VERSION ""

NS_ :

BS_:

BU_: CAMERA_ALL ALM_DX ALM_SX CAMERA_DEFAULT LOGBOX CAMERA_POS0 CAMERA_POS1 CAMERA_POS2 CAMERA_POS3 CAMERA_POS4 CAMERA_POS5 CAMERA_POS6 CAMERA_POS7 SVS RUR RUF RUC BC _TESTER BMS3_ADB BMS0_ADB BMS4_ADB BMS5_ADB BMS6_ADB
VAL_TABLE_ ___spare___ 3 "_SPARE_3" 2 "_SPARE_2" 1 "_SPARE_1" 0 "_SPARE_0" ;
VAL_TABLE_ HeaterWaterTemp 255 "NOT AVAILABLE" 254 "ERROR" ;

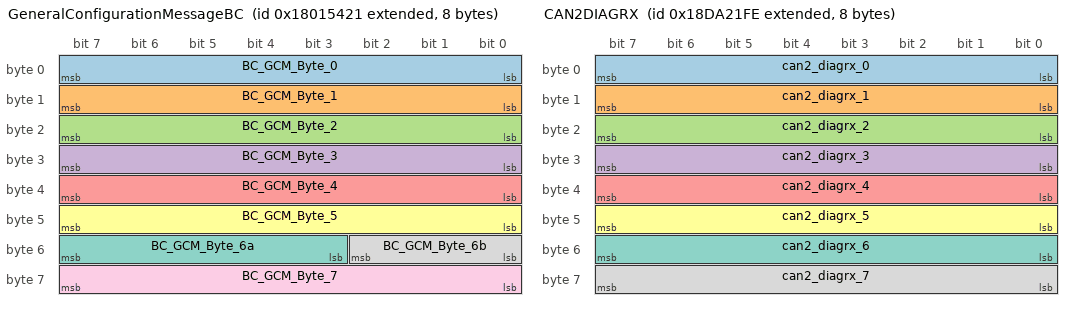
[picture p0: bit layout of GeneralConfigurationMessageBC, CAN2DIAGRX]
BO_ 2550223905 GeneralConfigurationMessageBC: 8 BC
 SG_ BC_GCM_Byte_0 : 0|8@1+ (1,0) [170|170] "-"  SVS
 SG_ BC_GCM_Byte_1 : 8|8@1+ (1,0) [107|107] "-"  SVS
 SG_ BC_GCM_Byte_2 : 16|8@1+ (1,0) [128|136] "-"  SVS
 SG_ BC_GCM_Byte_3 : 24|8@1+ (1,0) [0|0] "-"  SVS
 SG_ BC_GCM_Byte_4 : 32|8@1+ (1,0) [0|0] "-"  SVS
 SG_ BC_GCM_Byte_5 : 40|8@1+ (1,0) [0|0] "-"  SVS
 SG_ BC_GCM_Byte_6a : 51|5@1+ (1,0) [0|0] "-"  SVS
 SG_ BC_GCM_Byte_6b : 48|3@1+ (1,0) [0|7] "-"  SVS
 SG_ BC_GCM_Byte_7 : 56|8@1+ (1,0) [128|135] "-"  SVS

BO_ 2564432382 CAN2DIAGRX: 8 _TESTER
 SG_ can2_diagrx_0 : 0|8@1+ (1,0) [0|0] "-"  BC
 SG_ can2_diagrx_1 : 8|8@1+ (1,0) [0|0] "-"  BC
 SG_ can2_diagrx_2 : 16|8@1+ (1,0) [0|0] "-"  BC
 SG_ can2_diagrx_3 : 24|8@1+ (1,0) [0|0] "-"  BC
 SG_ can2_diagrx_4 : 32|8@1+ (1,0) [0|0] "-"  BC
 SG_ can2_diagrx_5 : 40|8@1+ (1,0) [0|0] "-"  BC
 SG_ can2_diagrx_6 : 48|8@1+ (1,0) [0|0] "-"  BC
 SG_ can2_diagrx_7 : 56|8@1+ (1,0) [0|0] "-"  BC

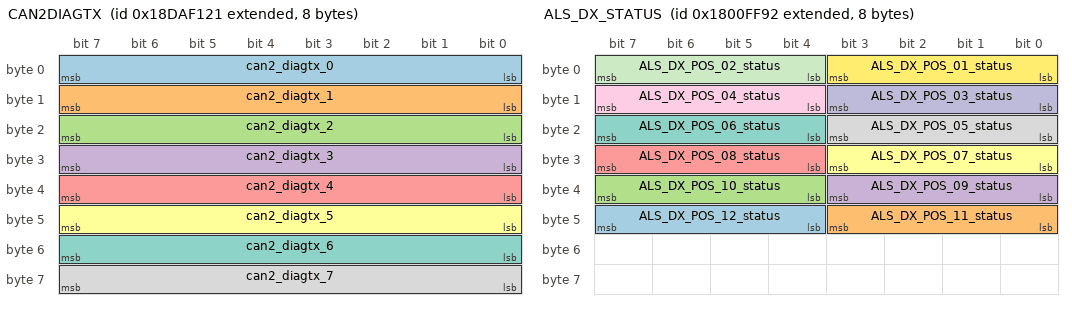
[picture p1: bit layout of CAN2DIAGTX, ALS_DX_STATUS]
BO_ 2564485409 CAN2DIAGTX: 8 BC
 SG_ can2_diagtx_0 : 0|8@1+ (1,0) [0|0] "-"  _TESTER
 SG_ can2_diagtx_1 : 8|8@1+ (1,0) [0|0] "-"  _TESTER
 SG_ can2_diagtx_2 : 16|8@1+ (1,0) [0|0] "-"  _TESTER
 SG_ can2_diagtx_3 : 24|8@1+ (1,0) [0|0] "-"  _TESTER
 SG_ can2_diagtx_4 : 32|8@1+ (1,0) [0|0] "-"  _TESTER
 SG_ can2_diagtx_5 : 40|8@1+ (1,0) [0|0] "-"  _TESTER
 SG_ can2_diagtx_6 : 48|8@1+ (1,0) [0|0] "-"  _TESTER
 SG_ can2_diagtx_7 : 56|8@1+ (1,0) [0|0] "-"  _TESTER

BO_ 2550202258 ALS_DX_STATUS: 8 ALM_DX
 SG_ ALS_DX_POS_12_status : 44|4@1+ (1,0) [0|15] "-"  BC,LOGBOX,SVS
 SG_ ALS_DX_POS_11_status : 40|4@1+ (1,0) [0|15] "-"  BC,LOGBOX,SVS
 SG_ ALS_DX_POS_10_status : 36|4@1+ (1,0) [0|15] "-"  BC,LOGBOX,SVS
 SG_ ALS_DX_POS_09_status : 32|4@1+ (1,0) [0|15] "-"  BC,LOGBOX,SVS
 SG_ ALS_DX_POS_08_status : 28|4@1+ (1,0) [0|15] "-"  BC,LOGBOX,SVS
 SG_ ALS_DX_POS_07_status : 24|4@1+ (1,0) [0|15] "-"  BC,LOGBOX,SVS
 SG_ ALS_DX_POS_06_status : 20|4@1+ (1,0) [0|15] "-"  BC,LOGBOX,SVS
 SG_ ALS_DX_POS_05_status : 16|4@1+ (1,0) [0|15] "-"  BC,LOGBOX,SVS
 SG_ ALS_DX_POS_04_status : 12|4@1+ (1,0) [0|15] "-"  BC,LOGBOX,SVS
 SG_ ALS_DX_POS_03_status : 8|4@1+ (1,0) [0|15] "-"  BC,LOGBOX,SVS
 SG_ ALS_DX_POS_02_status : 4|4@1+ (1,0) [0|15] "-"  BC,LOGBOX,SVS
 SG_ ALS_DX_POS_01_status : 0|4@1+ (1,0) [0|15] "-"  BC,LOGBOX,SVS

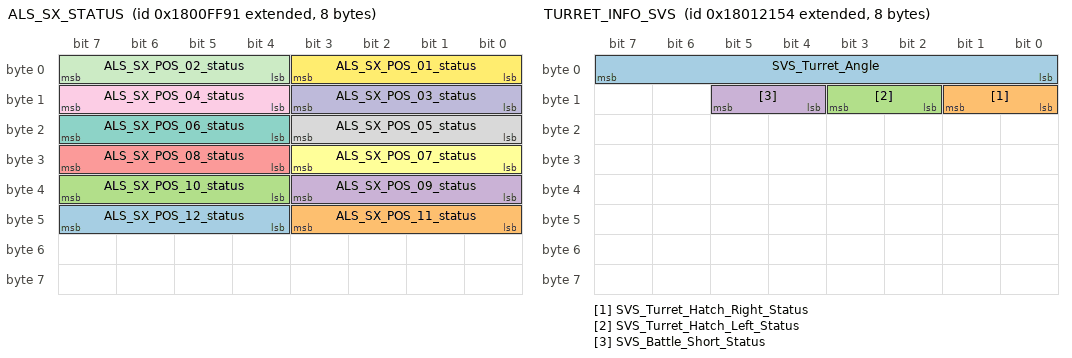
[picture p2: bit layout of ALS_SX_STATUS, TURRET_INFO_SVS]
BO_ 2550202257 ALS_SX_STATUS: 8 ALM_SX
 SG_ ALS_SX_POS_12_status : 44|4@1+ (1,0) [0|15] "-"  BC,LOGBOX,SVS
 SG_ ALS_SX_POS_11_status : 40|4@1+ (1,0) [0|15] "-"  BC,LOGBOX,SVS
 SG_ ALS_SX_POS_10_status : 36|4@1+ (1,0) [0|15] "-"  BC,LOGBOX,SVS
 SG_ ALS_SX_POS_09_status : 32|4@1+ (1,0) [0|15] "-"  BC,LOGBOX,SVS
 SG_ ALS_SX_POS_08_status : 28|4@1+ (1,0) [0|15] "-"  BC,LOGBOX,SVS
 SG_ ALS_SX_POS_07_status : 24|4@1+ (1,0) [0|15] "-"  BC,LOGBOX,SVS
 SG_ ALS_SX_POS_06_status : 20|4@1+ (1,0) [0|15] "-"  BC,LOGBOX,SVS
 SG_ ALS_SX_POS_05_status : 16|4@1+ (1,0) [0|15] "-"  BC,LOGBOX,SVS
 SG_ ALS_SX_POS_04_status : 12|4@1+ (1,0) [0|15] "-"  BC,LOGBOX,SVS
 SG_ ALS_SX_POS_03_status : 8|4@1+ (1,0) [0|15] "-"  BC,LOGBOX,SVS
 SG_ ALS_SX_POS_02_status : 4|4@1+ (1,0) [0|15] "-"  BC,LOGBOX,SVS
 SG_ ALS_SX_POS_01_status : 0|4@1+ (1,0) [0|15] "-"  BC,LOGBOX,SVS

BO_ 2550210900 TURRET_INFO_SVS: 8 SVS
 SG_ SVS_Turret_Angle : 0|8@1+ (1.44,-180) [-180|180] "deg"  LOGBOX,BC
 SG_ SVS_Turret_Hatch_Right_Status : 8|2@1+ (1,0) [0|3] "-"  LOGBOX,BC
 SG_ SVS_Turret_Hatch_Left_Status : 10|2@1+ (1,0) [0|3] "-"  LOGBOX,BC
 SG_ SVS_Battle_Short_Status : 12|2@1+ (1,0) [0|3] "-"  LOGBOX,BC

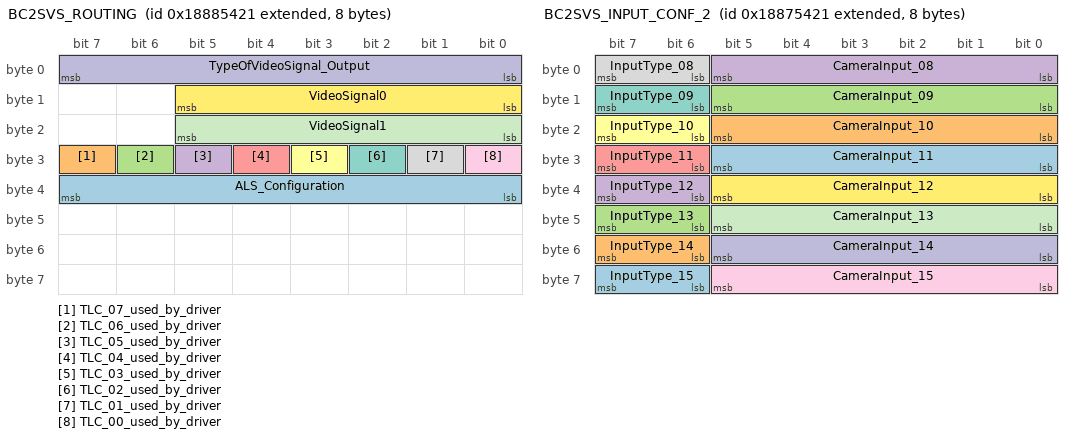
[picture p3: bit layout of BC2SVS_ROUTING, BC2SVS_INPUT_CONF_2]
BO_ 2559071265 BC2SVS_ROUTING: 8 BC
 SG_ ALS_Configuration : 32|8@1+ (1,0) [0|255] "-"  LOGBOX,SVS
 SG_ TLC_07_used_by_driver : 31|1@1+ (1,0) [0|1] "-"  LOGBOX,SVS
 SG_ TLC_06_used_by_driver : 30|1@1+ (1,0) [0|1] "-"  LOGBOX,SVS
 SG_ TLC_05_used_by_driver : 29|1@1+ (1,0) [0|1] "-"  LOGBOX,SVS
 SG_ TLC_04_used_by_driver : 28|1@1+ (1,0) [0|1] "-"  LOGBOX,SVS
 SG_ TLC_03_used_by_driver : 27|1@1+ (1,0) [0|1] "-"  LOGBOX,SVS
 SG_ TLC_02_used_by_driver : 26|1@1+ (1,0) [0|1] "-"  LOGBOX,SVS
 SG_ TLC_01_used_by_driver : 25|1@1+ (1,0) [0|1] "-"  LOGBOX,SVS
 SG_ TLC_00_used_by_driver : 24|1@1+ (1,0) [0|1] "-"  LOGBOX,SVS
 SG_ TypeOfVideoSignal_Output : 0|8@1+ (1,0) [0|255] "-"  LOGBOX,SVS
 SG_ VideoSignal1 : 16|6@1+ (1,0) [0|31] "-"  LOGBOX,SVS
 SG_ VideoSignal0 : 8|6@1+ (1,0) [0|31] "-"  LOGBOX,SVS

BO_ 2559005729 BC2SVS_INPUT_CONF_2: 8 BC
 SG_ InputType_15 : 62|2@1+ (1,0) [0|3] "-"  LOGBOX,SVS
 SG_ InputType_14 : 54|2@1+ (1,0) [0|3] "-"  LOGBOX,SVS
 SG_ InputType_13 : 46|2@1+ (1,0) [0|3] "-"  LOGBOX,SVS
 SG_ InputType_12 : 38|2@1+ (1,0) [0|3] "-"  LOGBOX,SVS
 SG_ InputType_11 : 30|2@1+ (1,0) [0|3] "-"  LOGBOX,SVS
 SG_ InputType_10 : 22|2@1+ (1,0) [0|3] "-"  LOGBOX,SVS
 SG_ InputType_09 : 14|2@1+ (1,0) [0|3] "-"  LOGBOX,SVS
 SG_ InputType_08 : 6|2@1+ (1,0) [0|3] "-"  LOGBOX,SVS
 SG_ CameraInput_15 : 56|6@1+ (1,0) [0|31] "-"  LOGBOX,SVS
 SG_ CameraInput_14 : 48|6@1+ (1,0) [0|31] "-"  LOGBOX,SVS
 SG_ CameraInput_13 : 40|6@1+ (1,0) [0|31] "-"  LOGBOX,SVS
 SG_ CameraInput_12 : 32|6@1+ (1,0) [0|31] "-"  LOGBOX,SVS
 SG_ CameraInput_11 : 24|6@1+ (1,0) [0|31] "-"  LOGBOX,SVS
 SG_ CameraInput_10 : 16|6@1+ (1,0) [0|31] "-"  LOGBOX,SVS
 SG_ CameraInput_09 : 8|6@1+ (1,0) [0|31] "-"  LOGBOX,SVS
 SG_ CameraInput_08 : 0|6@1+ (1,0) [0|31] "-"  LOGBOX,SVS

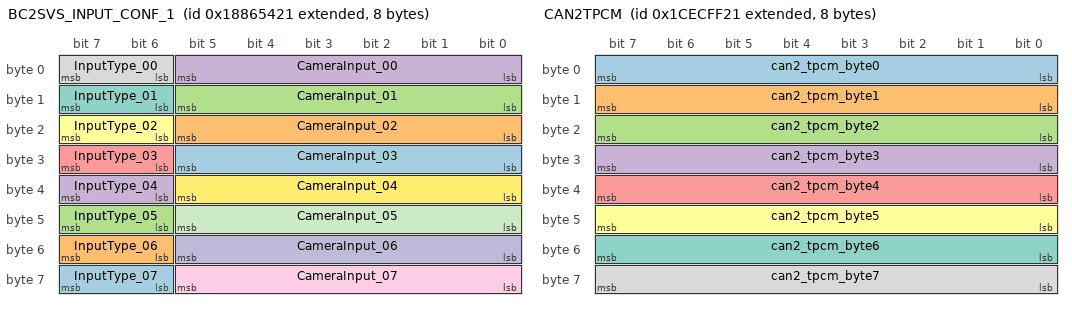
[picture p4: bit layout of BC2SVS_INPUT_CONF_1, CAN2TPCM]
BO_ 2558940193 BC2SVS_INPUT_CONF_1: 8 BC
 SG_ InputType_07 : 62|2@1+ (1,0) [0|3] "-"  LOGBOX,SVS
 SG_ InputType_06 : 54|2@1+ (1,0) [0|3] "-"  LOGBOX,SVS
 SG_ InputType_05 : 46|2@1+ (1,0) [0|3] "-"  LOGBOX,SVS
 SG_ InputType_04 : 38|2@1+ (1,0) [0|3] "-"  LOGBOX,SVS
 SG_ InputType_03 : 30|2@1+ (1,0) [0|3] "-"  LOGBOX,SVS
 SG_ InputType_02 : 22|2@1+ (1,0) [0|3] "-"  LOGBOX,SVS
 SG_ InputType_01 : 14|2@1+ (1,0) [0|3] "-"  LOGBOX,SVS
 SG_ InputType_00 : 6|2@1+ (1,0) [0|3] "-"  LOGBOX,SVS
 SG_ CameraInput_07 : 56|6@1+ (1,0) [0|31] "-"  LOGBOX,SVS
 SG_ CameraInput_06 : 48|6@1+ (1,0) [0|31] "-"  LOGBOX,SVS
 SG_ CameraInput_05 : 40|6@1+ (1,0) [0|31] "-"  LOGBOX,SVS
 SG_ CameraInput_04 : 32|6@1+ (1,0) [0|31] "-"  LOGBOX,SVS
 SG_ CameraInput_03 : 24|6@1+ (1,0) [0|31] "-"  LOGBOX,SVS
 SG_ CameraInput_02 : 16|6@1+ (1,0) [0|31] "-"  LOGBOX,SVS
 SG_ CameraInput_01 : 8|6@1+ (1,0) [0|31] "-"  LOGBOX,SVS
 SG_ CameraInput_00 : 0|6@1+ (1,0) [0|31] "-"  LOGBOX,SVS

BO_ 2632777505 CAN2TPCM: 8 BC
 SG_ can2_tpcm_byte0 : 0|8@1+ (1,0) [0|0] "-"  LOGBOX,_TESTER
 SG_ can2_tpcm_byte1 : 8|8@1+ (1,0) [0|0] "-"  LOGBOX,_TESTER
 SG_ can2_tpcm_byte2 : 16|8@1+ (1,0) [0|0] "-"  LOGBOX,_TESTER
 SG_ can2_tpcm_byte3 : 24|8@1+ (1,0) [0|0] "-"  LOGBOX,_TESTER
 SG_ can2_tpcm_byte4 : 32|8@1+ (1,0) [0|0] "-"  LOGBOX,_TESTER
 SG_ can2_tpcm_byte5 : 40|8@1+ (1,0) [0|0] "-"  LOGBOX,_TESTER
 SG_ can2_tpcm_byte6 : 48|8@1+ (1,0) [0|0] "-"  LOGBOX,_TESTER
 SG_ can2_tpcm_byte7 : 56|8@1+ (1,0) [0|0] "-"  LOGBOX,_TESTER

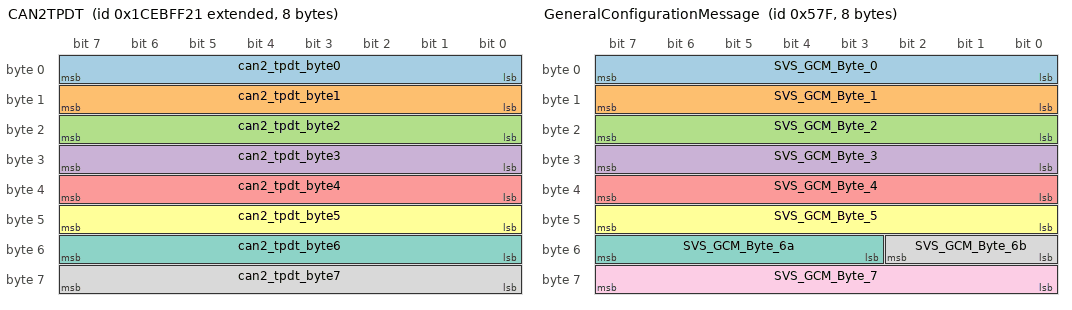
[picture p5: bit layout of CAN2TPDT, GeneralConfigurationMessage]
BO_ 2632711969 CAN2TPDT: 8 BC
 SG_ can2_tpdt_byte0 : 0|8@1+ (1,0) [0|0] "-"  LOGBOX,_TESTER
 SG_ can2_tpdt_byte1 : 8|8@1+ (1,0) [0|0] "-"  LOGBOX,_TESTER
 SG_ can2_tpdt_byte2 : 16|8@1+ (1,0) [0|0] "-"  LOGBOX,_TESTER
 SG_ can2_tpdt_byte3 : 24|8@1+ (1,0) [0|0] "-"  LOGBOX,_TESTER
 SG_ can2_tpdt_byte4 : 32|8@1+ (1,0) [0|0] "-"  LOGBOX,_TESTER
 SG_ can2_tpdt_byte5 : 40|8@1+ (1,0) [0|0] "-"  LOGBOX,_TESTER
 SG_ can2_tpdt_byte6 : 48|8@1+ (1,0) [0|0] "-"  LOGBOX,_TESTER
 SG_ can2_tpdt_byte7 : 56|8@1+ (1,0) [0|0] "-"  LOGBOX,_TESTER

BO_ 2550145364 CameraStatus: 8 SVS
 SG_ SVS_IN_31_status : 62|2@1+ (1,0) [0|3] "-"  LOGBOX
 SG_ SVS_IN_30_status : 60|2@1+ (1,0) [0|3] "-"  LOGBOX
 SG_ SVS_IN_29_status : 58|2@1+ (1,0) [0|3] "-"  LOGBOX
 SG_ SVS_IN_28_status : 56|2@1+ (1,0) [0|3] "-"  LOGBOX
 SG_ SVS_IN_27_status : 54|2@1+ (1,0) [0|3] "-"  LOGBOX
 SG_ SVS_IN_26_status : 52|2@1+ (1,0) [0|3] "-"  LOGBOX
 SG_ SVS_IN_25_status : 50|2@1+ (1,0) [0|3] "-"  LOGBOX
 SG_ SVS_IN_24_status : 48|2@1+ (1,0) [0|3] "-"  LOGBOX
 SG_ SVS_IN_23_status : 46|2@1+ (1,0) [0|3] "-"  LOGBOX
 SG_ SVS_IN_22_status : 44|2@1+ (1,0) [0|3] "-"  LOGBOX
 SG_ SVS_IN_21_status : 42|2@1+ (1,0) [0|3] "-"  LOGBOX
 SG_ SVS_IN_20_status : 40|2@1+ (1,0) [0|3] "-"  LOGBOX
 SG_ SVS_IN_19_status : 38|2@1+ (1,0) [0|3] "-"  LOGBOX
 SG_ SVS_IN_18_status : 36|2@1+ (1,0) [0|3] "-"  LOGBOX
 SG_ SVS_IN_17_status : 34|2@1+ (1,0) [0|3] "-"  LOGBOX
 SG_ SVS_IN_16_status : 32|2@1+ (1,0) [0|3] "-"  LOGBOX
 SG_ SVS_IN_15_status : 30|2@1+ (1,0) [0|3] "-"  LOGBOX
 SG_ SVS_IN_14_status : 28|2@1+ (1,0) [0|3] "-"  LOGBOX
 SG_ SVS_IN_13_status : 26|2@1+ (1,0) [0|3] "-"  LOGBOX
 SG_ SVS_IN_12_status : 24|2@1+ (1,0) [0|3] "-"  LOGBOX
 SG_ SVS_IN_11_status : 22|2@1+ (1,0) [0|3] "-"  LOGBOX
 SG_ SVS_IN_10_status : 20|2@1+ (1,0) [0|3] "-"  LOGBOX
 SG_ SVS_IN_09_status : 18|2@1+ (1,0) [0|3] "-"  LOGBOX
 SG_ SVS_IN_08_status : 16|2@1+ (1,0) [0|3] "-"  LOGBOX
 SG_ SVS_IN_07_status : 14|2@1+ (1,0) [0|3] "-"  LOGBOX
 SG_ SVS_IN_06_status : 12|2@1+ (1,0) [0|3] "-"  BC,LOGBOX
 SG_ SVS_IN_05_status : 10|2@1+ (1,0) [0|3] "-"  BC,LOGBOX
 SG_ SVS_IN_04_status : 8|2@1+ (1,0) [0|3] "-"  BC,LOGBOX
 SG_ SVS_IN_03_status : 6|2@1+ (1,0) [0|3] "-"  BC,LOGBOX
 SG_ SVS_IN_02_status : 4|2@1+ (1,0) [0|3] "-"  BC,LOGBOX
 SG_ SVS_IN_01_status : 2|2@1+ (1,0) [0|3] "-"  BC,LOGBOX
 SG_ SVS_IN_00_status : 0|2@1+ (1,0) [0|3] "-"  BC,LOGBOX

BO_ 2550158369 CameraControlBC: 8 BC
 SG_ CCBC_Reserved_02 : 32|7@1+ (1,0) [0|0] "-"  LOGBOX,SVS
 SG_ CCBC_DCAM_Preset : 44|4@1+ (1,0) [0|8] "-"  LOGBOX,SVS
 SG_ CCBC_TI_NUC_mode_reset_p1 : 0|4@1+ (1,0) [0|8] "-"  LOGBOX,SVS
 SG_ CCBC_ProtectiveLid : 4|2@1+ (1,0) [0|2] "-"  LOGBOX,SVS
 SG_ CCBC_VideoSource_ch0 : 6|2@1+ (1,0) [0|2] "-"  LOGBOX,SVS
 SG_ CCBC_TI_DDE : 8|2@1+ (1,0) [0|2] "-"  LOGBOX,SVS
 SG_ CCBC_HorizontalFlip : 10|2@1+ (1,0) [0|2] "-"  LOGBOX,SVS
 SG_ CCBC_OverlayGraphics : 12|2@1+ (1,0) [0|2] "-"  LOGBOX,SVS
 SG_ CCBC_VideoSource_ch1 : 14|2@1+ (1,0) [0|0] "-"  LOGBOX,SVS
 SG_ CCBC_TI_Polarity : 16|2@1+ (1,0) [0|2] "-"  LOGBOX,SVS
 SG_ CCBC_TI_Zoom : 18|2@1+ (1,0) [0|2] "-"  LOGBOX,SVS
 SG_ CCBC_TI_ROI : 20|4@1+ (1,0) [0|8] "-"  LOGBOX,SVS
 SG_ CCBC_VideoBlending_ch0 : 24|4@1+ (1,0) [0|8] "-"  LOGBOX,SVS
 SG_ CCBC_Reserved_01 : 28|3@1+ (1,0) [0|0] "-"  LOGBOX,SVS
 SG_ CCBC_TI_NUC_mode_reset_p2 : 31|1@1+ (1,0) [0|0] "-"  LOGBOX,SVS
 SG_ CCBC_WindowHeaters : 39|1@1+ (1,0) [0|1] "-"  LOGBOX,SVS
 SG_ CCBC_TLC_07_Requested : 63|1@1+ (1,0) [0|1] "-"  LOGBOX,SVS
 SG_ CCBC_TLC_06_Requested : 62|1@1+ (1,0) [0|1] "-"  LOGBOX,SVS
 SG_ CCBC_TLC_05_Requested : 61|1@1+ (1,0) [0|1] "-"  LOGBOX,SVS
 SG_ CCBC_TLC_04_Requested : 60|1@1+ (1,0) [0|1] "-"  LOGBOX,SVS
 SG_ CCBC_TLC_03_Requested : 59|1@1+ (1,0) [0|1] "-"  LOGBOX,SVS
 SG_ CCBC_TLC_02_Requested : 58|1@1+ (1,0) [0|1] "-"  LOGBOX,SVS
 SG_ CCBC_TLC_01_Requested : 57|1@1+ (1,0) [0|1] "-"  LOGBOX,SVS
 SG_ CCBC_TLC_00_Requested : 56|1@1+ (1,0) [0|1] "-"  LOGBOX,SVS
 SG_ CCBC_Reserved_03 : 40|4@1+ (1,0) [0|0] "-"  LOGBOX,SVS
 SG_ CCBC_Reserved_04 : 48|8@1+ (1,0) [0|0] "-"  LOGBOX,SVS

BO_ 2015 InformationMessage: 8 CAMERA_ALL
 SG_ IM_VideoSource_ch1 : 15|1@1+ (1,0) [0|1] "-"  LOGBOX,SVS
 SG_ IM_CameraPosition : 0|3@1+ (1,0) [0|7] "-"  LOGBOX,SVS
 SG_ IM_Reserved_01 : 3|1@1+ (1,0) [0|0] "-"  LOGBOX,SVS
 SG_ IM_ImageBlending_Available : 4|1@1+ (1,0) [0|1] "-"  LOGBOX,SVS
 SG_ IM_Reserved_02 : 5|1@1+ (1,0) [0|0] "-"  LOGBOX,SVS
 SG_ IM_DCAM_Available : 6|1@1+ (1,0) [0|1] "-"  LOGBOX,SVS
 SG_ IM_TI_Available : 7|1@1+ (1,0) [0|1] "-"  LOGBOX,SVS
 SG_ IM_Reserved_03 : 8|7@1+ (1,0) [0|0] "-"  LOGBOX,SVS
 SG_ IM_msgID_msb : 16|3@1+ (1,0) [0|7] "-"  LOGBOX,SVS
 SG_ IM_Reserved_04 : 19|5@1+ (1,0) [0|0] "-"  LOGBOX,SVS
 SG_ IM_msgID_lsb : 24|8@1+ (1,0) [0|255] "-"  LOGBOX,SVS
 SG_ IM_FieldOfView : 32|8@1+ (1,0) [0|255] "deg"  LOGBOX,SVS
 SG_ IM_Humidity_TooHigh : 40|1@1+ (1,0) [0|1] "-"  LOGBOX,SVS
 SG_ IM_Temperature_TooHigh : 41|1@1+ (1,0) [0|1] "-"  LOGBOX,SVS
 SG_ IM_POST_Failed : 42|1@1+ (1,0) [0|1] "-"  LOGBOX,SVS
 SG_ IM_Reserved_05 : 43|5@1+ (1,0) [0|0] "-"  LOGBOX,SVS
 SG_ IM_TI_Zoom : 48|2@1+ (1,0) [1|2] "-"  LOGBOX,SVS
 SG_ IM_VideoHeaters : 50|1@1+ (1,0) [0|1] "-"  LOGBOX,SVS
 SG_ IM_HorizontalFlip : 51|1@1+ (1,0) [0|1] "-"  LOGBOX,SVS
 SG_ IM_NUC : 52|1@1+ (1,0) [0|1] "-"  LOGBOX,SVS
 SG_ IM_VideoBlendingMode : 53|1@1+ (1,0) [0|1] "-"  LOGBOX,SVS
 SG_ IM_DCAM_Preset : 54|2@1+ (1,0) [0|0] "-"  LOGBOX,SVS
 SG_ IM_ProtectiveLid : 56|1@1+ (1,0) [0|1] "-"  LOGBOX,SVS
 SG_ IM_VideoSource_ch0 : 57|1@1+ (1,0) [0|1] "-"  LOGBOX,SVS
 SG_ IM_PAL_Stretch : 58|1@1+ (1,0) [0|1] "-"  LOGBOX,SVS
 SG_ IM_TI_DDE : 59|1@1+ (1,0) [0|1] "-"  LOGBOX,SVS
 SG_ IM_OverlayGraphic : 60|1@1+ (1,0) [0|1] "-"  LOGBOX,SVS
 SG_ IM_ROI : 61|2@1+ (1,0) [0|3] "-"  LOGBOX,SVS
 SG_ IM_TI_Polarity : 63|1@1+ (1,0) [0|1] "-"  LOGBOX,SVS

BO_ 1416 CameraControlD: 8 SVS
 SG_ CCD_Reserved_02 : 28|3@1+ (1,0) [0|0] "-"  LOGBOX,CAMERA_DEFAULT
 SG_ CCD_DCAM_Preset : 44|4@1+ (1,0) [0|8] "-"  LOGBOX,CAMERA_DEFAULT
 SG_ CCD_TI_NUC_mode_reset_p1 : 0|4@1+ (1,0) [0|8] "-"  LOGBOX,CAMERA_DEFAULT
 SG_ CCD_ProtectiveLid : 4|2@1+ (1,0) [0|2] "-"  LOGBOX,CAMERA_DEFAULT
 SG_ CCD_VideoSource_ch0 : 6|2@1+ (1,0) [0|2] "-"  LOGBOX,CAMERA_DEFAULT
 SG_ CCD_TI_DDE : 8|2@1+ (1,0) [0|2] "-"  LOGBOX,CAMERA_DEFAULT
 SG_ CCD_HorizontalFlip : 10|2@1+ (1,0) [0|2] "-"  LOGBOX,CAMERA_DEFAULT
 SG_ CCD_OverlayGraphics : 12|2@1+ (1,0) [0|2] "-"  LOGBOX,CAMERA_DEFAULT
 SG_ CCD_VideoSource_ch1 : 14|2@1+ (1,0) [0|0] "-"  LOGBOX,CAMERA_DEFAULT
 SG_ CCD_TI_Polarity : 16|2@1+ (1,0) [0|2] "-"  LOGBOX,CAMERA_DEFAULT
 SG_ CCD_TI_Zoom : 18|2@1+ (1,0) [0|2] "-"  LOGBOX,CAMERA_DEFAULT
 SG_ CCD_TI_ROI : 20|4@1+ (1,0) [0|8] "-"  LOGBOX,CAMERA_DEFAULT
 SG_ CCD_VideoBlending_ch0 : 24|4@1+ (1,0) [0|8] "-"  LOGBOX,CAMERA_DEFAULT
 SG_ CCD_Reserved_03 : 32|7@1+ (1,0) [0|0] "-"  LOGBOX,CAMERA_DEFAULT
 SG_ CCD_TI_NUC_mode_reset_p2 : 31|1@1+ (1,0) [0|0] "-"  LOGBOX,CAMERA_DEFAULT
 SG_ CCD_WindowHeaters : 39|1@1+ (1,0) [0|1] "-"  LOGBOX,CAMERA_DEFAULT
 SG_ CCD_Reserved_04 : 40|4@1+ (1,0) [0|0] "-"  LOGBOX,CAMERA_DEFAULT
 SG_ CCD_Reserved_05 : 48|8@1+ (1,0) [0|0] "-"  LOGBOX,CAMERA_DEFAULT
 SG_ CCD_Reserved_06 : 56|8@1+ (1,0) [0|0] "-"  LOGBOX,CAMERA_DEFAULT

BO_ 1415 CameraControl7: 8 SVS
 SG_ CC7_Reserved_02 : 28|3@1+ (1,0) [0|0] "-"  LOGBOX,CAMERA_POS7
 SG_ CC7_DCAM_Preset : 44|4@1+ (1,0) [0|8] "-"  LOGBOX,CAMERA_POS7
 SG_ CC7_TI_NUC_mode_reset_p1 : 0|4@1+ (1,0) [0|8] "-"  LOGBOX,CAMERA_POS7
 SG_ CC7_ProtectiveLid : 4|2@1+ (1,0) [0|2] "-"  LOGBOX,CAMERA_POS7
 SG_ CC7_VideoSource_ch0 : 6|2@1+ (1,0) [0|2] "-"  LOGBOX,CAMERA_POS7
 SG_ CC7_TI_DDE : 8|2@1+ (1,0) [0|2] "-"  LOGBOX,CAMERA_POS7
 SG_ CC7_HorizontalFlip : 10|2@1+ (1,0) [0|2] "-"  LOGBOX,CAMERA_POS7
 SG_ CC7_OverlayGraphics : 12|2@1+ (1,0) [0|2] "-"  LOGBOX,CAMERA_POS7
 SG_ CC7_VideoSource_ch1 : 14|2@1+ (1,0) [0|0] "-"  LOGBOX,CAMERA_POS7
 SG_ CC7_TI_Polarity : 16|2@1+ (1,0) [0|2] "-"  LOGBOX,CAMERA_POS7
 SG_ CC7_TI_Zoom : 18|2@1+ (1,0) [0|2] "-"  LOGBOX,CAMERA_POS7
 SG_ CC7_TI_ROI : 20|4@1+ (1,0) [0|8] "-"  LOGBOX,CAMERA_POS7
 SG_ CC7_VideoBlending_ch0 : 24|4@1+ (1,0) [0|8] "-"  LOGBOX,CAMERA_POS7
 SG_ CC7_Reserved_03 : 32|7@1+ (1,0) [0|0] "-"  LOGBOX,CAMERA_POS7
 SG_ CC7_TI_NUC_mode_reset_p2 : 31|1@1+ (1,0) [0|0] "-"  LOGBOX,CAMERA_POS7
 SG_ CC7_WindowHeaters : 39|1@1+ (1,0) [0|1] "-"  LOGBOX,CAMERA_POS7
 SG_ CC7_Reserved_04 : 40|4@1+ (1,0) [0|0] "-"  LOGBOX,CAMERA_POS7
 SG_ CC7_Reserved_05 : 48|8@1+ (1,0) [0|0] "-"  LOGBOX,CAMERA_POS7
 SG_ CC7_Reserved_06 : 56|8@1+ (1,0) [0|0] "-"  LOGBOX,CAMERA_POS7

BO_ 1414 CameraControl6: 8 SVS
 SG_ CC6_Reserved_02 : 28|3@1+ (1,0) [0|0] "-"  LOGBOX,CAMERA_POS6
 SG_ CC6_DCAM_Preset : 44|4@1+ (1,0) [0|8] "-"  LOGBOX,CAMERA_POS6
 SG_ CC6_TI_NUC_mode_reset_p1 : 0|4@1+ (1,0) [0|8] "-"  LOGBOX,CAMERA_POS6
 SG_ CC6_ProtectiveLid : 4|2@1+ (1,0) [0|2] "-"  LOGBOX,CAMERA_POS6
 SG_ CC6_VideoSource_ch0 : 6|2@1+ (1,0) [0|2] "-"  LOGBOX,CAMERA_POS6
 SG_ CC6_TI_DDE : 8|2@1+ (1,0) [0|2] "-"  LOGBOX,CAMERA_POS6
 SG_ CC6_HorizontalFlip : 10|2@1+ (1,0) [0|2] "-"  LOGBOX,CAMERA_POS6
 SG_ CC6_OverlayGraphics : 12|2@1+ (1,0) [0|2] "-"  LOGBOX,CAMERA_POS6
 SG_ CC6_VideoSource_ch1 : 14|2@1+ (1,0) [0|0] "-"  LOGBOX,CAMERA_POS6
 SG_ CC6_TI_Polarity : 16|2@1+ (1,0) [0|2] "-"  LOGBOX,CAMERA_POS6
 SG_ CC6_TI_Zoom : 18|2@1+ (1,0) [0|2] "-"  LOGBOX,CAMERA_POS6
 SG_ CC6_TI_ROI : 20|4@1+ (1,0) [0|8] "-"  LOGBOX,CAMERA_POS6
 SG_ CC6_VideoBlending_ch0 : 24|4@1+ (1,0) [0|8] "-"  LOGBOX,CAMERA_POS6
 SG_ CC6_Reserved_03 : 32|7@1+ (1,0) [0|0] "-"  LOGBOX,CAMERA_POS6
 SG_ CC6_TI_NUC_mode_reset_p2 : 31|1@1+ (1,0) [0|0] "-"  LOGBOX,CAMERA_POS6
 SG_ CC6_WindowHeaters : 39|1@1+ (1,0) [0|1] "-"  LOGBOX,CAMERA_POS6
 SG_ CC6_Reserved_04 : 40|4@1+ (1,0) [0|0] "-"  LOGBOX,CAMERA_POS6
 SG_ CC6_Reserved_05 : 48|8@1+ (1,0) [0|0] "-"  LOGBOX,CAMERA_POS6
 SG_ CC6_Reserved_06 : 56|8@1+ (1,0) [0|0] "-"  LOGBOX,CAMERA_POS6

BO_ 1413 CameraControl5: 8 SVS
 SG_ CC5_Reserved_02 : 28|3@1+ (1,0) [0|0] "-"  LOGBOX,CAMERA_POS5
 SG_ CC5_DCAM_Preset : 44|4@1+ (1,0) [0|8] "-"  LOGBOX,CAMERA_POS5
 SG_ CC5_TI_NUC_mode_reset_p1 : 0|4@1+ (1,0) [0|8] "-"  LOGBOX,CAMERA_POS5
 SG_ CC5_ProtectiveLid : 4|2@1+ (1,0) [0|2] "-"  LOGBOX,CAMERA_POS5
 SG_ CC5_VideoSource_ch0 : 6|2@1+ (1,0) [0|2] "-"  LOGBOX,CAMERA_POS5
 SG_ CC5_TI_DDE : 8|2@1+ (1,0) [0|2] "-"  LOGBOX,CAMERA_POS5
 SG_ CC5_HorizontalFlip : 10|2@1+ (1,0) [0|2] "-"  LOGBOX,CAMERA_POS5
 SG_ CC5_OverlayGraphics : 12|2@1+ (1,0) [0|2] "-"  LOGBOX,CAMERA_POS5
 SG_ CC5_VideoSource_ch1 : 14|2@1+ (1,0) [0|0] "-"  LOGBOX,CAMERA_POS5
 SG_ CC5_TI_Polarity : 16|2@1+ (1,0) [0|2] "-"  LOGBOX,CAMERA_POS5
 SG_ CC5_TI_Zoom : 18|2@1+ (1,0) [0|2] "-"  LOGBOX,CAMERA_POS5
 SG_ CC5_TI_ROI : 20|4@1+ (1,0) [0|8] "-"  LOGBOX,CAMERA_POS5
 SG_ CC5_VideoBlending_ch0 : 24|4@1+ (1,0) [0|8] "-"  LOGBOX,CAMERA_POS5
 SG_ CC5_Reserved_03 : 32|7@1+ (1,0) [0|0] "-"  LOGBOX,CAMERA_POS5
 SG_ CC5_TI_NUC_mode_reset_p2 : 31|1@1+ (1,0) [0|0] "-"  LOGBOX,CAMERA_POS5
 SG_ CC5_WindowHeaters : 39|1@1+ (1,0) [0|1] "-"  LOGBOX,CAMERA_POS5
 SG_ CC5_Reserved_04 : 40|4@1+ (1,0) [0|0] "-"  LOGBOX,CAMERA_POS5
 SG_ CC5_Reserved_05 : 48|8@1+ (1,0) [0|0] "-"  LOGBOX,CAMERA_POS5
 SG_ CC5_Reserved_06 : 56|8@1+ (1,0) [0|0] "-"  LOGBOX,CAMERA_POS5

BO_ 1412 CameraControl4: 8 SVS
 SG_ CC4_Reserved_02 : 28|3@1+ (1,0) [0|0] "-"  LOGBOX,CAMERA_POS4
 SG_ CC4_DCAM_Preset : 44|4@1+ (1,0) [0|8] "-"  LOGBOX,CAMERA_POS4
 SG_ CC4_TI_NUC_mode_reset_p1 : 0|4@1+ (1,0) [0|8] "-"  LOGBOX,CAMERA_POS4
 SG_ CC4_ProtectiveLid : 4|2@1+ (1,0) [0|2] "-"  LOGBOX,CAMERA_POS4
 SG_ CC4_VideoSource_ch0 : 6|2@1+ (1,0) [0|2] "-"  LOGBOX,CAMERA_POS4
 SG_ CC4_TI_DDE : 8|2@1+ (1,0) [0|2] "-"  LOGBOX,CAMERA_POS4
 SG_ CC4_HorizontalFlip : 10|2@1+ (1,0) [0|2] "-"  LOGBOX,CAMERA_POS4
 SG_ CC4_OverlayGraphics : 12|2@1+ (1,0) [0|2] "-"  LOGBOX,CAMERA_POS4
 SG_ CC4_VideoSource_ch1 : 14|2@1+ (1,0) [0|0] "-"  LOGBOX,CAMERA_POS4
 SG_ CC4_TI_Polarity : 16|2@1+ (1,0) [0|2] "-"  LOGBOX,CAMERA_POS4
 SG_ CC4_TI_Zoom : 18|2@1+ (1,0) [0|2] "-"  LOGBOX,CAMERA_POS4
 SG_ CC4_TI_ROI : 20|4@1+ (1,0) [0|8] "-"  LOGBOX,CAMERA_POS4
 SG_ CC4_VideoBlending_ch0 : 24|4@1+ (1,0) [0|8] "-"  LOGBOX,CAMERA_POS4
 SG_ CC4_Reserved_03 : 32|7@1+ (1,0) [0|0] "-"  LOGBOX,CAMERA_POS4
 SG_ CC4_TI_NUC_mode_reset_p2 : 31|1@1+ (1,0) [0|0] "-"  LOGBOX,CAMERA_POS4
 SG_ CC4_WindowHeaters : 39|1@1+ (1,0) [0|1] "-"  LOGBOX,CAMERA_POS4
 SG_ CC4_Reserved_04 : 40|4@1+ (1,0) [0|0] "-"  LOGBOX,CAMERA_POS4
 SG_ CC4_Reserved_05 : 48|8@1+ (1,0) [0|0] "-"  LOGBOX,CAMERA_POS4
 SG_ CC4_Reserved_06 : 56|8@1+ (1,0) [0|0] "-"  LOGBOX,CAMERA_POS4

BO_ 1411 CameraControl3: 8 SVS
 SG_ CC3_Reserved_02 : 28|3@1+ (1,0) [0|0] "-"  LOGBOX,CAMERA_POS3
 SG_ CC3_DCAM_Preset : 44|4@1+ (1,0) [0|8] "-"  LOGBOX,CAMERA_POS3
 SG_ CC3_TI_NUC_mode_reset_p1 : 0|4@1+ (1,0) [0|8] "-"  LOGBOX,CAMERA_POS3
 SG_ CC3_ProtectiveLid : 4|2@1+ (1,0) [0|2] "-"  LOGBOX,CAMERA_POS3
 SG_ CC3_VideoSource_ch0 : 6|2@1+ (1,0) [0|2] "-"  LOGBOX,CAMERA_POS3
 SG_ CC3_TI_DDE : 8|2@1+ (1,0) [0|2] "-"  LOGBOX,CAMERA_POS3
 SG_ CC3_HorizontalFlip : 10|2@1+ (1,0) [0|2] "-"  LOGBOX,CAMERA_POS3
 SG_ CC3_OverlayGraphics : 12|2@1+ (1,0) [0|2] "-"  LOGBOX,CAMERA_POS3
 SG_ CC3_VideoSource_ch1 : 14|2@1+ (1,0) [0|0] "-"  LOGBOX,CAMERA_POS3
 SG_ CC3_TI_Polarity : 16|2@1+ (1,0) [0|2] "-"  LOGBOX,CAMERA_POS3
 SG_ CC3_TI_Zoom : 18|2@1+ (1,0) [0|2] "-"  LOGBOX,CAMERA_POS3
 SG_ CC3_TI_ROI : 20|4@1+ (1,0) [0|8] "-"  LOGBOX,CAMERA_POS3
 SG_ CC3_VideoBlending_ch0 : 24|4@1+ (1,0) [0|8] "-"  LOGBOX,CAMERA_POS3
 SG_ CC3_Reserved_03 : 32|7@1+ (1,0) [0|0] "-"  LOGBOX,CAMERA_POS3
 SG_ CC3_TI_NUC_mode_reset_p2 : 31|1@1+ (1,0) [0|0] "-"  LOGBOX,CAMERA_POS3
 SG_ CC3_WindowHeaters : 39|1@1+ (1,0) [0|1] "-"  LOGBOX,CAMERA_POS3
 SG_ CC3_Reserved_04 : 40|4@1+ (1,0) [0|0] "-"  LOGBOX,CAMERA_POS3
 SG_ CC3_Reserved_05 : 48|8@1+ (1,0) [0|0] "-"  LOGBOX,CAMERA_POS3
 SG_ CC3_Reserved_06 : 56|8@1+ (1,0) [0|0] "-"  LOGBOX,CAMERA_POS3

BO_ 1410 CameraControl2: 8 SVS
 SG_ CC2_Reserved_02 : 28|3@1+ (1,0) [0|0] "-"  LOGBOX,CAMERA_POS2
 SG_ CC2_DCAM_Preset : 44|4@1+ (1,0) [0|8] "-"  LOGBOX,CAMERA_POS2
 SG_ CC2_TI_NUC_mode_reset_p1 : 0|4@1+ (1,0) [0|8] "-"  LOGBOX,CAMERA_POS2
 SG_ CC2_ProtectiveLid : 4|2@1+ (1,0) [0|2] "-"  LOGBOX,CAMERA_POS2
 SG_ CC2_VideoSource_ch0 : 6|2@1+ (1,0) [0|2] "-"  LOGBOX,CAMERA_POS2
 SG_ CC2_TI_DDE : 8|2@1+ (1,0) [0|2] "-"  LOGBOX,CAMERA_POS2
 SG_ CC2_HorizontalFlip : 10|2@1+ (1,0) [0|2] "-"  LOGBOX,CAMERA_POS2
 SG_ CC2_OverlayGraphics : 12|2@1+ (1,0) [0|2] "-"  LOGBOX,CAMERA_POS2
 SG_ CC2_VideoSource_ch1 : 14|2@1+ (1,0) [0|0] "-"  LOGBOX,CAMERA_POS2
 SG_ CC2_TI_Polarity : 16|2@1+ (1,0) [0|2] "-"  LOGBOX,CAMERA_POS2
 SG_ CC2_TI_Zoom : 18|2@1+ (1,0) [0|2] "-"  LOGBOX,CAMERA_POS2
 SG_ CC2_TI_ROI : 20|4@1+ (1,0) [0|8] "-"  LOGBOX,CAMERA_POS2
 SG_ CC2_VideoBlending_ch0 : 24|4@1+ (1,0) [0|8] "-"  LOGBOX,CAMERA_POS2
 SG_ CC2_Reserved_03 : 32|7@1+ (1,0) [0|0] "-"  LOGBOX,CAMERA_POS2
 SG_ CC2_TI_NUC_mode_reset_p2 : 31|1@1+ (1,0) [0|0] "-"  LOGBOX,CAMERA_POS2
 SG_ CC2_WindowHeaters : 39|1@1+ (1,0) [0|1] "-"  LOGBOX,CAMERA_POS2
 SG_ CC2_Reserved_04 : 40|4@1+ (1,0) [0|0] "-"  LOGBOX,CAMERA_POS2
 SG_ CC2_Reserved_05 : 48|8@1+ (1,0) [0|0] "-"  LOGBOX,CAMERA_POS2
 SG_ CC2_Reserved_06 : 56|8@1+ (1,0) [0|0] "-"  LOGBOX,CAMERA_POS2

BO_ 1409 CameraControl1: 8 SVS
 SG_ CC1_Reserved_02 : 28|3@1+ (1,0) [0|0] "-"  LOGBOX,CAMERA_POS1
 SG_ CC1_DCAM_Preset : 44|4@1+ (1,0) [0|8] "-"  LOGBOX,CAMERA_POS1
 SG_ CC1_TI_NUC_mode_reset_p1 : 0|4@1+ (1,0) [0|8] "-"  LOGBOX,CAMERA_POS1
 SG_ CC1_ProtectiveLid : 4|2@1+ (1,0) [0|2] "-"  LOGBOX,CAMERA_POS1
 SG_ CC1_VideoSource_ch0 : 6|2@1+ (1,0) [0|2] "-"  LOGBOX,CAMERA_POS1
 SG_ CC1_TI_DDE : 8|2@1+ (1,0) [0|2] "-"  LOGBOX,CAMERA_POS1
 SG_ CC1_HorizontalFlip : 10|2@1+ (1,0) [0|2] "-"  LOGBOX,CAMERA_POS1
 SG_ CC1_OverlayGraphics : 12|2@1+ (1,0) [0|2] "-"  LOGBOX,CAMERA_POS1
 SG_ CC1_VideoSource_ch1 : 14|2@1+ (1,0) [0|0] "-"  LOGBOX,CAMERA_POS1
 SG_ CC1_TI_Polarity : 16|2@1+ (1,0) [0|2] "-"  LOGBOX,CAMERA_POS1
 SG_ CC1_TI_Zoom : 18|2@1+ (1,0) [0|2] "-"  LOGBOX,CAMERA_POS1
 SG_ CC1_TI_ROI : 20|4@1+ (1,0) [0|8] "-"  LOGBOX,CAMERA_POS1
 SG_ CC1_VideoBlending_ch0 : 24|4@1+ (1,0) [0|8] "-"  LOGBOX,CAMERA_POS1
 SG_ CC1_Reserved_03 : 32|7@1+ (1,0) [0|0] "-"  LOGBOX,CAMERA_POS1
 SG_ CC1_TI_NUC_mode_reset_p2 : 31|1@1+ (1,0) [0|0] "-"  LOGBOX,CAMERA_POS1
 SG_ CC1_WindowHeaters : 39|1@1+ (1,0) [0|1] "-"  LOGBOX,CAMERA_POS1
 SG_ CC1_Reserved_04 : 40|4@1+ (1,0) [0|0] "-"  LOGBOX,CAMERA_POS1
 SG_ CC1_Reserved_05 : 48|8@1+ (1,0) [0|0] "-"  LOGBOX,CAMERA_POS1
 SG_ CC1_Reserved_06 : 56|8@1+ (1,0) [0|0] "-"  LOGBOX,CAMERA_POS1

BO_ 1408 CameraControl0: 8 SVS
 SG_ CC0_Reserved_02 : 28|3@1+ (1,0) [0|0] "-"  LOGBOX,CAMERA_POS0
 SG_ CC0_DCAM_Preset : 44|4@1+ (1,0) [0|8] "-"  LOGBOX,CAMERA_POS0
 SG_ CC0_TI_NUC_mode_reset_p1 : 0|4@1+ (1,0) [0|8] "-"  LOGBOX,CAMERA_POS0
 SG_ CC0_ProtectiveLid : 4|2@1+ (1,0) [0|2] "-"  LOGBOX,CAMERA_POS0
 SG_ CC0_VideoSource_ch0 : 6|2@1+ (1,0) [0|2] "-"  LOGBOX,CAMERA_POS0
 SG_ CC0_TI_DDE : 8|2@1+ (1,0) [0|2] "-"  LOGBOX,CAMERA_POS0
 SG_ CC0_HorizontalFlip : 10|2@1+ (1,0) [0|2] "-"  LOGBOX,CAMERA_POS0
 SG_ CC0_OverlayGraphics : 12|2@1+ (1,0) [0|2] "-"  LOGBOX,CAMERA_POS0
 SG_ CC0_VideoSource_ch1 : 14|2@1+ (1,0) [0|0] "-"  LOGBOX,CAMERA_POS0
 SG_ CC0_TI_Polarity : 16|2@1+ (1,0) [0|2] "-"  LOGBOX,CAMERA_POS0
 SG_ CC0_TI_Zoom : 18|2@1+ (1,0) [0|2] "-"  LOGBOX,CAMERA_POS0
 SG_ CC0_TI_ROI : 20|4@1+ (1,0) [0|8] "-"  LOGBOX,CAMERA_POS0
 SG_ CC0_VideoBlending_ch0 : 24|4@1+ (1,0) [0|8] "-"  LOGBOX,CAMERA_POS0
 SG_ CC0_Reserved_03 : 32|7@1+ (1,0) [0|0] "-"  LOGBOX,CAMERA_POS0
 SG_ CC0_TI_NUC_mode_reset_p2 : 31|1@1+ (1,0) [0|0] "-"  LOGBOX,CAMERA_POS0
 SG_ CC0_WindowHeaters : 39|1@1+ (1,0) [0|1] "-"  LOGBOX,CAMERA_POS0
 SG_ CC0_Reserved_04 : 40|4@1+ (1,0) [0|0] "-"  LOGBOX,CAMERA_POS0
 SG_ CC0_Reserved_05 : 48|8@1+ (1,0) [0|0] "-"  LOGBOX,CAMERA_POS0
 SG_ CC0_Reserved_06 : 56|8@1+ (1,0) [0|0] "-"  LOGBOX,CAMERA_POS0

BO_ 1407 GeneralConfigurationMessage: 8 SVS
 SG_ SVS_GCM_Byte_0 : 0|8@1+ (1,0) [170|170] "-"  CAMERA_DEFAULT,CAMERA_POS7,CAMERA_POS6,CAMERA_POS5,CAMERA_POS4,CAMERA_POS3,CAMERA_POS2,CAMERA_POS1,LOGBOX,CAMERA_POS0
 SG_ SVS_GCM_Byte_1 : 8|8@1+ (1,0) [107|107] "-"  CAMERA_DEFAULT,CAMERA_POS7,CAMERA_POS6,CAMERA_POS5,CAMERA_POS4,CAMERA_POS3,CAMERA_POS2,CAMERA_POS1,LOGBOX,CAMERA_POS0
 SG_ SVS_GCM_Byte_2 : 16|8@1+ (1,0) [128|136] "-"  CAMERA_DEFAULT,CAMERA_POS7,CAMERA_POS6,CAMERA_POS5,CAMERA_POS4,CAMERA_POS3,CAMERA_POS2,CAMERA_POS1,LOGBOX,CAMERA_POS0
 SG_ SVS_GCM_Byte_3 : 24|8@1+ (1,0) [0|0] "-"  CAMERA_DEFAULT,CAMERA_POS7,CAMERA_POS6,CAMERA_POS5,CAMERA_POS4,CAMERA_POS3,CAMERA_POS2,CAMERA_POS1,LOGBOX,CAMERA_POS0
 SG_ SVS_GCM_Byte_4 : 32|8@1+ (1,0) [0|0] "-"  CAMERA_DEFAULT,CAMERA_POS7,CAMERA_POS6,CAMERA_POS5,CAMERA_POS4,CAMERA_POS3,CAMERA_POS2,CAMERA_POS1,LOGBOX,CAMERA_POS0
 SG_ SVS_GCM_Byte_5 : 40|8@1+ (1,0) [0|0] "-"  CAMERA_DEFAULT,CAMERA_POS7,CAMERA_POS6,CAMERA_POS5,CAMERA_POS4,CAMERA_POS3,CAMERA_POS2,CAMERA_POS1,LOGBOX,CAMERA_POS0
 SG_ SVS_GCM_Byte_6a : 51|5@1+ (1,0) [0|0] "-"  CAMERA_DEFAULT,CAMERA_POS7,CAMERA_POS6,CAMERA_POS5,CAMERA_POS4,CAMERA_POS3,CAMERA_POS2,CAMERA_POS1,LOGBOX,CAMERA_POS0
 SG_ SVS_GCM_Byte_6b : 48|3@1+ (1,0) [0|7] "-"  CAMERA_DEFAULT,CAMERA_POS7,CAMERA_POS6,CAMERA_POS5,CAMERA_POS4,CAMERA_POS3,CAMERA_POS2,CAMERA_POS1,LOGBOX,CAMERA_POS0
 SG_ SVS_GCM_Byte_7 : 56|8@1+ (1,0) [128|135] "-"  CAMERA_DEFAULT,CAMERA_POS7,CAMERA_POS6,CAMERA_POS5,CAMERA_POS4,CAMERA_POS3,CAMERA_POS2,CAMERA_POS1,LOGBOX,CAMERA_POS0

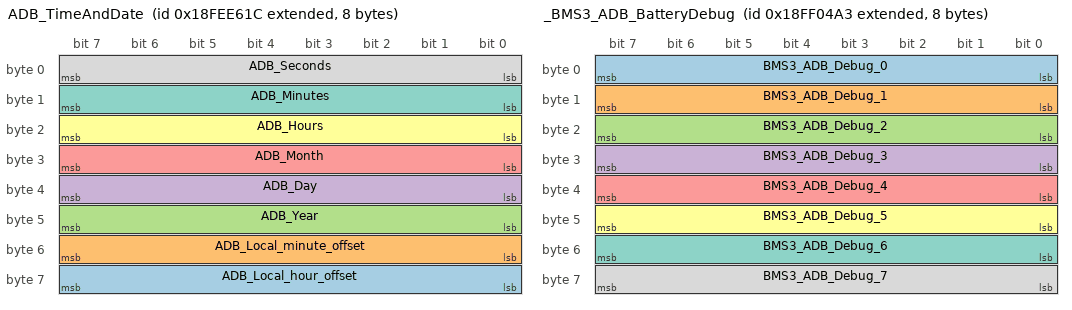
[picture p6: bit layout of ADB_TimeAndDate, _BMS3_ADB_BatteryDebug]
BO_ 2566841884 ADB_TimeAndDate: 8 LOGBOX
 SG_ ADB_Local_hour_offset : 56|8@1+ (1,-125) [-23|23] "hr"  LOGBOX
 SG_ ADB_Local_minute_offset : 48|8@1+ (1,-125) [-125|125] "min"  LOGBOX
 SG_ ADB_Year : 40|8@1+ (1,1985) [1985|2235] "-"  LOGBOX
 SG_ ADB_Day : 32|8@1+ (0.25,0.75) [0.25|31.75] "-"  LOGBOX
 SG_ ADB_Month : 24|8@1+ (1,0) [1|12] "-"  LOGBOX
 SG_ ADB_Hours : 16|8@1+ (1,0) [0|23] "hr"  LOGBOX
 SG_ ADB_Minutes : 8|8@1+ (1,0) [0|59] "min"  LOGBOX
 SG_ ADB_Seconds : 0|8@1+ (0.25,0) [0|59.75] "sec"  LOGBOX

BO_ 2566849955 BMS3_ADB_BatterySummaryStatus: 8 BMS3_ADB
 SG_ BMS3_ADB_BatSumS_serial_number : 0|24@1+ (1,0) [0|16777214] "-"  BC,LOGBOX
 SG_ BMS3_ADB_BatSumS_Reserved_01 : 24|8@1+ (1,0) [0|255] "-"  LOGBOX
 SG_ BMS3_ADB_BatSumS_State_of_Charge : 32|8@1+ (1,0) [0|100] "%"  LOGBOX,BC
 SG_ BMS3_ADB_BatSumS_State_of_Health : 40|8@1+ (1,0) [0|2] "-"  LOGBOX,BC
 SG_ BMS3_ADB_BatSumS_Temp_Alarm : 48|2@1+ (1,0) [0|3] "-"  LOGBOX,BC
 SG_ BMS3_ADB_BatSumS_DischargeDis : 50|1@1+ (1,0) [0|1] "-"  LOGBOX,BC
 SG_ BMS3_ADB_BatSumS_ChargingDisable : 51|1@1+ (1,0) [0|1] "-"  LOGBOX,BC
 SG_ BMS3_ADB_BatSumS_HeaterEnabled : 52|1@1+ (1,0) [0|1] "-"  LOGBOX,BC
 SG_ BMS3_ADB_BatSumS_BypassEnabled : 53|1@1+ (1,0) [0|1] "-"  LOGBOX,BC
 SG_ BMS3_ADB_BatSumS_Voltage_Alarm : 56|1@1+ (1,0) [0|1] "-"  LOGBOX,BC
 SG_ BMS3_ADB_BatSumS_Reserved_04 : 54|2@1+ (1,0) [0|3] "-"  LOGBOX
 SG_ BMS3_ADB_BatSumS_Reserved_05 : 57|1@1+ (1,0) [0|1] "-"  LOGBOX,BC
 SG_ BMS3_ADB_BatSumS_Reserved_06 : 58|1@1+ (1,0) [0|1] "-"  LOGBOX
 SG_ BMS3_ADB_BatSumS_Reserved_07 : 59|1@1+ (1,0) [0|1] "-"  LOGBOX
 SG_ BMS3_ADB_BatSumS_Reserved_08 : 60|1@1+ (1,0) [0|1] "-"  LOGBOX
 SG_ BMS3_ADB_BatSumS_Reserved_09 : 61|1@1+ (1,0) [0|1] "-"  LOGBOX
 SG_ BMS3_ADB_BatSumS_Reserved_10 : 62|1@1+ (1,0) [0|1] "-"  LOGBOX
 SG_ BMS3_ADB_BatSumS_Reserved_11 : 63|1@1+ (1,0) [0|1] "-"  LOGBOX

BO_ 2566849699 _BMS3_ADB_BatteryDebug: 8 BMS3_ADB
 SG_ BMS3_ADB_Debug_0 : 0|8@1+ (1,0) [0|255] "-"  LOGBOX
 SG_ BMS3_ADB_Debug_1 : 8|8@1+ (1,0) [0|255] "-"  LOGBOX
 SG_ BMS3_ADB_Debug_2 : 16|8@1+ (1,0) [0|255] "-"  LOGBOX
 SG_ BMS3_ADB_Debug_3 : 24|8@1+ (1,0) [0|255] "-"  LOGBOX
 SG_ BMS3_ADB_Debug_4 : 32|8@1+ (1,0) [0|255] "-"  LOGBOX
 SG_ BMS3_ADB_Debug_5 : 40|8@1+ (1,0) [0|255] "-"  LOGBOX
 SG_ BMS3_ADB_Debug_6 : 48|8@1+ (1,0) [0|255] "-"  LOGBOX
 SG_ BMS3_ADB_Debug_7 : 56|8@1+ (1,0) [0|255] "-"  LOGBOX

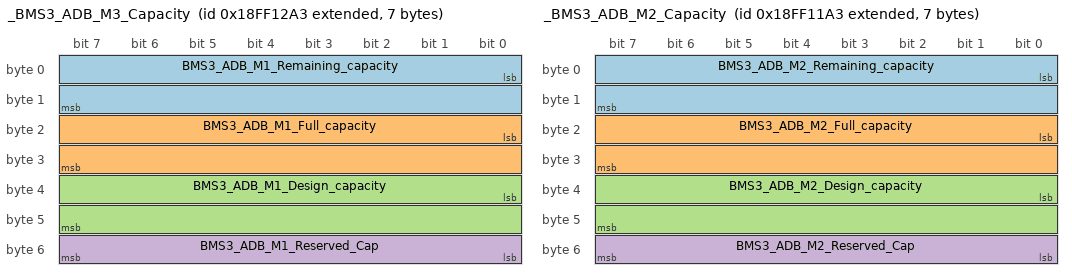
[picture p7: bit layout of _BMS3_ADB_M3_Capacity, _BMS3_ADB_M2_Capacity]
BO_ 2566853283 _BMS3_ADB_M3_Capacity: 7 BMS3_ADB
 SG_ BMS3_ADB_M1_Remaining_capacity : 0|16@1+ (0.01,0) [0|642.55] "Ah"  LOGBOX
 SG_ BMS3_ADB_M1_Full_capacity : 16|16@1+ (0.01,0) [0|642.55] "Ah"  LOGBOX
 SG_ BMS3_ADB_M1_Design_capacity : 32|16@1+ (0.01,0) [0|642.55] "Ah"  LOGBOX
 SG_ BMS3_ADB_M1_Reserved_Cap : 48|8@1+ (1,0) [255|255] "-"  LOGBOX

BO_ 2566853027 _BMS3_ADB_M2_Capacity: 7 BMS3_ADB
 SG_ BMS3_ADB_M2_Remaining_capacity : 0|16@1+ (0.01,0) [0|642.55] "Ah"  LOGBOX
 SG_ BMS3_ADB_M2_Full_capacity : 16|16@1+ (0.01,0) [0|642.55] "Ah"  LOGBOX
 SG_ BMS3_ADB_M2_Design_capacity : 32|16@1+ (0.01,0) [0|642.55] "Ah"  LOGBOX
 SG_ BMS3_ADB_M2_Reserved_Cap : 48|8@1+ (1,0) [255|255] "-"  LOGBOX

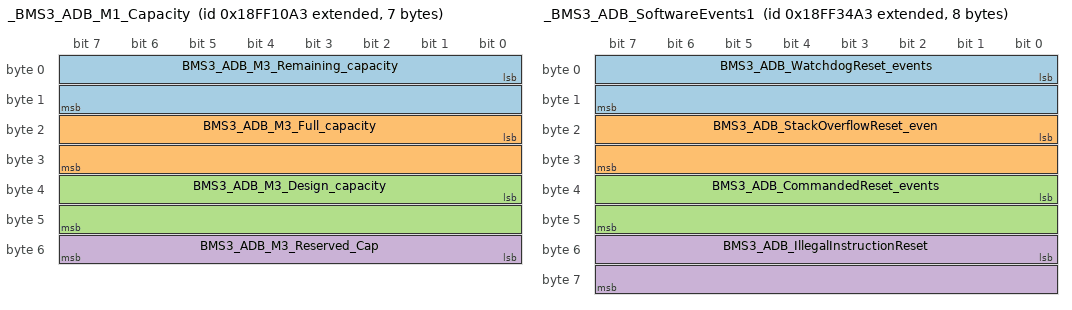
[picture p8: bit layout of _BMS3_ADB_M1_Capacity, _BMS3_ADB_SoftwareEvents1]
BO_ 2566852771 _BMS3_ADB_M1_Capacity: 7 BMS3_ADB
 SG_ BMS3_ADB_M3_Remaining_capacity : 0|16@1+ (0.01,0) [0|642.55] "Ah"  LOGBOX
 SG_ BMS3_ADB_M3_Full_capacity : 16|16@1+ (0.01,0) [0|642.55] "Ah"  LOGBOX
 SG_ BMS3_ADB_M3_Design_capacity : 32|16@1+ (0.01,0) [0|642.55] "Ah"  LOGBOX
 SG_ BMS3_ADB_M3_Reserved_Cap : 48|8@1+ (1,0) [255|255] "-"  LOGBOX

BO_ 2566861987 _BMS3_ADB_SoftwareEvents1: 8 BMS3_ADB
 SG_ BMS3_ADB_WatchdogReset_events : 0|16@1+ (1,0) [0|64255] "-"  LOGBOX
 SG_ BMS3_ADB_StackOverflowReset_even : 16|16@1+ (1,0) [0|64255] "-"  LOGBOX
 SG_ BMS3_ADB_CommandedReset_events : 32|16@1+ (1,0) [0|64255] "-"  LOGBOX
 SG_ BMS3_ADB_IllegalInstructionReset : 48|16@1+ (1,0) [0|64255] "-"  LOGBOX

BO_ 2566861731 _BMS3_ADB_VoltageEvents: 4 BMS3_ADB
 SG_ BMS3_ADB_OverVoltage_events : 0|16@1+ (1,0) [0|64255] "-"  LOGBOX
 SG_ BMS3_ADB_UnderVoltage_events : 16|16@1+ (1,0) [0|64255] "-"  LOGBOX

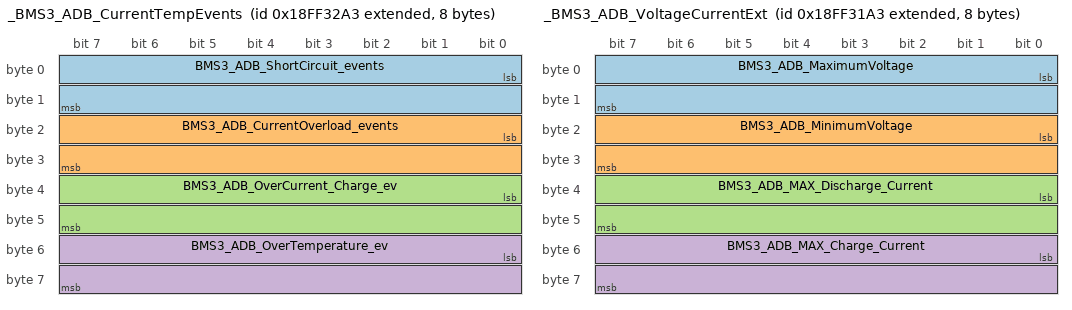
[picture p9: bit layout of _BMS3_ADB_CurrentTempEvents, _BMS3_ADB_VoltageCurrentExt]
BO_ 2566861475 _BMS3_ADB_CurrentTempEvents: 8 BMS3_ADB
 SG_ BMS3_ADB_ShortCircuit_events : 0|16@1+ (1,0) [0|64255] "-"  LOGBOX
 SG_ BMS3_ADB_CurrentOverload_events : 16|16@1+ (1,0) [0|64255] "-"  LOGBOX
 SG_ BMS3_ADB_OverCurrent_Charge_ev : 32|16@1+ (1,0) [0|64255] "-"  LOGBOX
 SG_ BMS3_ADB_OverTemperature_ev : 48|16@1+ (1,0) [0|64255] "-"  LOGBOX

BO_ 2566861219 _BMS3_ADB_VoltageCurrentExt: 8 BMS3_ADB
 SG_ BMS3_ADB_MaximumVoltage : 0|16@1+ (0.001,0) [0|64255] "V"  LOGBOX
 SG_ BMS3_ADB_MinimumVoltage : 16|16@1+ (0.001,0) [0|64255] "V"  LOGBOX
 SG_ BMS3_ADB_MAX_Discharge_Current : 32|16@1+ (0.1,0) [0|6425.5] "A"  LOGBOX
 SG_ BMS3_ADB_MAX_Charge_Current : 48|16@1+ (0.1,0) [0|6425.5] "A"  LOGBOX

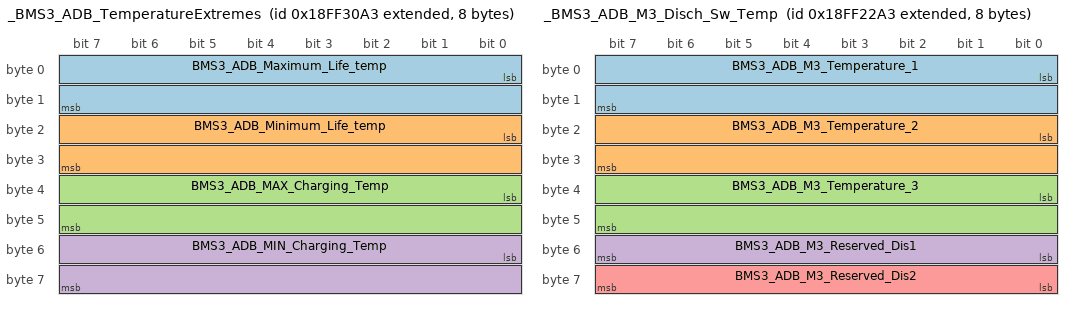
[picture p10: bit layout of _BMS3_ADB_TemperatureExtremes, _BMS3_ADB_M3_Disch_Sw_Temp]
BO_ 2566860963 _BMS3_ADB_TemperatureExtremes: 8 BMS3_ADB
 SG_ BMS3_ADB_Maximum_Life_temp : 0|16@1+ (0.1,-100) [-100|200] "°C"  LOGBOX
 SG_ BMS3_ADB_Minimum_Life_temp : 16|16@1+ (0.1,-100) [-100|200] "°C"  LOGBOX
 SG_ BMS3_ADB_MAX_Charging_Temp : 32|16@1+ (0.1,-100) [-100|200] "°C"  LOGBOX
 SG_ BMS3_ADB_MIN_Charging_Temp : 48|16@1+ (0.1,-100) [-100|200] "°C"  LOGBOX

BO_ 2566857379 _BMS3_ADB_M3_Disch_Sw_Temp: 8 BMS3_ADB
 SG_ BMS3_ADB_M3_Temperature_1 : 0|16@1+ (0.1,-100) [-100|200] "°C"  LOGBOX
 SG_ BMS3_ADB_M3_Temperature_2 : 16|16@1+ (0.1,-100) [-100|200] "°C"  LOGBOX
 SG_ BMS3_ADB_M3_Temperature_3 : 32|16@1+ (0.1,-100) [-100|200] "°C"  LOGBOX
 SG_ BMS3_ADB_M3_Reserved_Dis1 : 48|8@1+ (1,0) [255|255] "-"  LOGBOX
 SG_ BMS3_ADB_M3_Reserved_Dis2 : 56|8@1+ (1,0) [255|255] "-"  LOGBOX

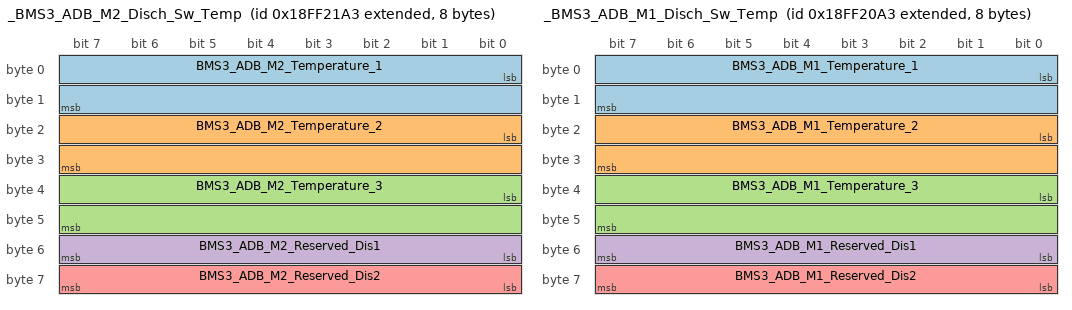
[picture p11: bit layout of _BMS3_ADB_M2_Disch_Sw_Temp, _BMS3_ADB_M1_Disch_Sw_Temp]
BO_ 2566857123 _BMS3_ADB_M2_Disch_Sw_Temp: 8 BMS3_ADB
 SG_ BMS3_ADB_M2_Temperature_1 : 0|16@1+ (0.1,-100) [-100|200] "°C"  LOGBOX
 SG_ BMS3_ADB_M2_Temperature_2 : 16|16@1+ (0.1,-100) [-100|200] "°C"  LOGBOX
 SG_ BMS3_ADB_M2_Temperature_3 : 32|16@1+ (0.1,-100) [-100|200] "°C"  LOGBOX
 SG_ BMS3_ADB_M2_Reserved_Dis1 : 48|8@1+ (1,0) [255|255] "-"  LOGBOX
 SG_ BMS3_ADB_M2_Reserved_Dis2 : 56|8@1+ (1,0) [255|255] "-"  LOGBOX

BO_ 2566856867 _BMS3_ADB_M1_Disch_Sw_Temp: 8 BMS3_ADB
 SG_ BMS3_ADB_M1_Temperature_1 : 0|16@1+ (0.1,-100) [-100|200] "°C"  LOGBOX
 SG_ BMS3_ADB_M1_Temperature_2 : 16|16@1+ (0.1,-100) [-100|200] "°C"  LOGBOX
 SG_ BMS3_ADB_M1_Temperature_3 : 32|16@1+ (0.1,-100) [-100|200] "°C"  LOGBOX
 SG_ BMS3_ADB_M1_Reserved_Dis1 : 48|8@1+ (1,0) [255|255] "-"  LOGBOX
 SG_ BMS3_ADB_M1_Reserved_Dis2 : 56|8@1+ (1,0) [255|255] "-"  LOGBOX

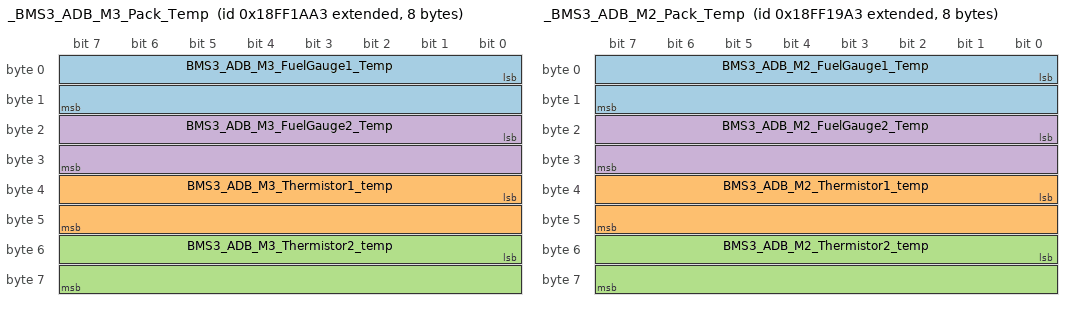
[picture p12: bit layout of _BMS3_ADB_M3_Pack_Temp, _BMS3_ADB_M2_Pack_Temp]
BO_ 2566855331 _BMS3_ADB_M3_Pack_Temp: 8 BMS3_ADB
 SG_ BMS3_ADB_M3_FuelGauge1_Temp : 0|16@1+ (0.1,-100) [-100|200] "°C"  LOGBOX
 SG_ BMS3_ADB_M3_Thermistor1_temp : 32|16@1+ (0.1,-100) [-100|200] "-"  LOGBOX
 SG_ BMS3_ADB_M3_Thermistor2_temp : 48|16@1+ (0.1,-100) [-100|200] "-"  LOGBOX
 SG_ BMS3_ADB_M3_FuelGauge2_Temp : 16|16@1+ (0.1,-100) [-100|200] "°C"  LOGBOX

BO_ 2566855075 _BMS3_ADB_M2_Pack_Temp: 8 BMS3_ADB
 SG_ BMS3_ADB_M2_FuelGauge1_Temp : 0|16@1+ (0.1,-100) [-100|200] "°C"  LOGBOX
 SG_ BMS3_ADB_M2_Thermistor1_temp : 32|16@1+ (0.1,-100) [-100|200] "-"  LOGBOX
 SG_ BMS3_ADB_M2_Thermistor2_temp : 48|16@1+ (0.1,-100) [-100|200] "-"  LOGBOX
 SG_ BMS3_ADB_M2_FuelGauge2_Temp : 16|16@1+ (0.1,-100) [-100|200] "°C"  LOGBOX

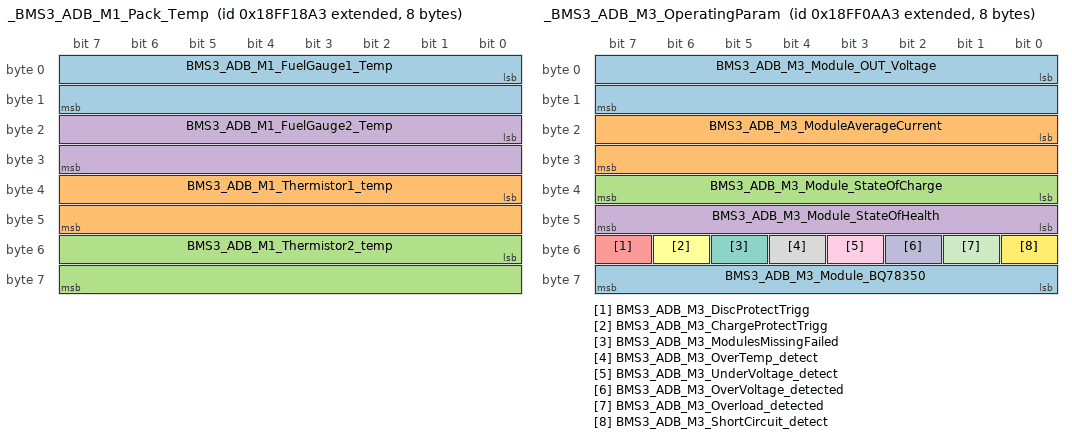
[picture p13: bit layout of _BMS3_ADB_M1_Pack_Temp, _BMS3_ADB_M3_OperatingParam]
BO_ 2566854819 _BMS3_ADB_M1_Pack_Temp: 8 BMS3_ADB
 SG_ BMS3_ADB_M1_FuelGauge1_Temp : 0|16@1+ (0.1,-100) [-100|200] "°C"  LOGBOX
 SG_ BMS3_ADB_M1_Thermistor1_temp : 32|16@1+ (0.1,-100) [-100|200] "-"  LOGBOX
 SG_ BMS3_ADB_M1_Thermistor2_temp : 48|16@1+ (0.1,-100) [-100|200] "-"  LOGBOX
 SG_ BMS3_ADB_M1_FuelGauge2_Temp : 16|16@1+ (0.1,-100) [-100|200] "°C"  LOGBOX

BO_ 2566851235 _BMS3_ADB_M3_OperatingParam: 8 BMS3_ADB
 SG_ BMS3_ADB_M3_Module_OUT_Voltage : 0|16@1+ (0.001,0) [0|64255] "V"  LOGBOX
 SG_ BMS3_ADB_M3_ModuleAverageCurrent : 16|16@1+ (0.1,-5500) [-5500|925.5] "A"  LOGBOX
 SG_ BMS3_ADB_M3_Module_StateOfCharge : 32|8@1+ (1,0) [0|100] "%"  LOGBOX
 SG_ BMS3_ADB_M3_Module_StateOfHealth : 40|8@1+ (1,0) [0|2] "-"  LOGBOX
 SG_ BMS3_ADB_M3_DiscProtectTrigg : 55|1@1+ (1,0) [0|1] "-"  LOGBOX
 SG_ BMS3_ADB_M3_ChargeProtectTrigg : 54|1@1+ (1,0) [0|1] "-"  LOGBOX
 SG_ BMS3_ADB_M3_ModulesMissingFailed : 53|1@1+ (1,0) [0|1] "-"  LOGBOX
 SG_ BMS3_ADB_M3_OverTemp_detect : 52|1@1+ (1,0) [0|1] "-"  LOGBOX
 SG_ BMS3_ADB_M3_UnderVoltage_detect : 51|1@1+ (1,0) [0|1] "-"  LOGBOX
 SG_ BMS3_ADB_M3_OverVoltage_detected : 50|1@1+ (1,0) [0|1] "-"  LOGBOX
 SG_ BMS3_ADB_M3_Overload_detected : 49|1@1+ (1,0) [0|1] "-"  LOGBOX
 SG_ BMS3_ADB_M3_ShortCircuit_detect : 48|1@1+ (1,0) [0|1] "-"  LOGBOX
 SG_ BMS3_ADB_M3_Module_BQ78350 : 56|8@1+ (1,0) [0|2] "-"  LOGBOX

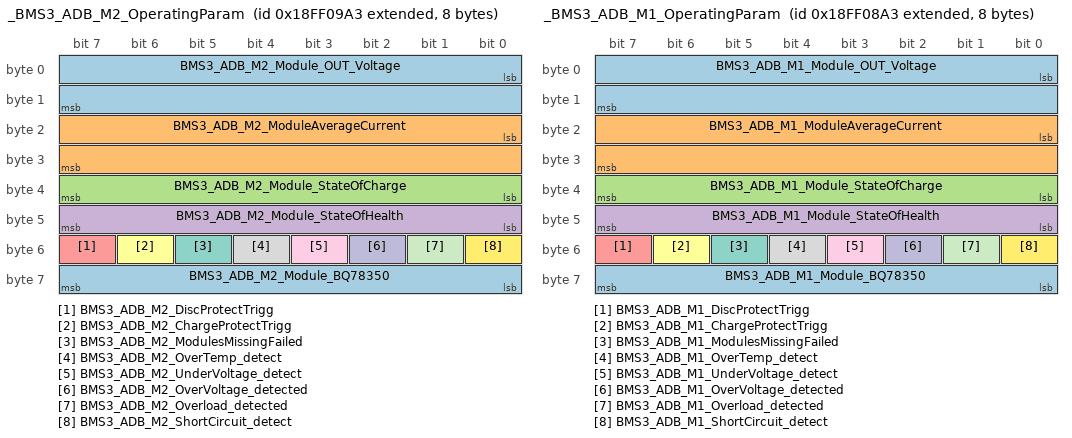
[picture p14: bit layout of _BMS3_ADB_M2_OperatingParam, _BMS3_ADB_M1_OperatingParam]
BO_ 2566850979 _BMS3_ADB_M2_OperatingParam: 8 BMS3_ADB
 SG_ BMS3_ADB_M2_Module_OUT_Voltage : 0|16@1+ (0.001,0) [0|64255] "V"  LOGBOX
 SG_ BMS3_ADB_M2_ModuleAverageCurrent : 16|16@1+ (0.1,-5500) [-5500|925.5] "A"  LOGBOX
 SG_ BMS3_ADB_M2_Module_StateOfCharge : 32|8@1+ (1,0) [0|100] "%"  LOGBOX
 SG_ BMS3_ADB_M2_Module_StateOfHealth : 40|8@1+ (1,0) [0|2] "-"  LOGBOX
 SG_ BMS3_ADB_M2_DiscProtectTrigg : 55|1@1+ (1,0) [0|1] "-"  LOGBOX
 SG_ BMS3_ADB_M2_ChargeProtectTrigg : 54|1@1+ (1,0) [0|1] "-"  LOGBOX
 SG_ BMS3_ADB_M2_ModulesMissingFailed : 53|1@1+ (1,0) [0|1] "-"  LOGBOX
 SG_ BMS3_ADB_M2_OverTemp_detect : 52|1@1+ (1,0) [0|1] "-"  LOGBOX
 SG_ BMS3_ADB_M2_UnderVoltage_detect : 51|1@1+ (1,0) [0|1] "-"  LOGBOX
 SG_ BMS3_ADB_M2_OverVoltage_detected : 50|1@1+ (1,0) [0|1] "-"  LOGBOX
 SG_ BMS3_ADB_M2_Overload_detected : 49|1@1+ (1,0) [0|1] "-"  LOGBOX
 SG_ BMS3_ADB_M2_ShortCircuit_detect : 48|1@1+ (1,0) [0|1] "-"  LOGBOX
 SG_ BMS3_ADB_M2_Module_BQ78350 : 56|8@1+ (1,0) [0|2] "-"  LOGBOX

BO_ 2566850723 _BMS3_ADB_M1_OperatingParam: 8 BMS3_ADB
 SG_ BMS3_ADB_M1_Module_OUT_Voltage : 0|16@1+ (0.001,0) [0|64255] "V"  LOGBOX
 SG_ BMS3_ADB_M1_ModuleAverageCurrent : 16|16@1+ (0.1,-5500) [-5500|925.5] "A"  LOGBOX
 SG_ BMS3_ADB_M1_Module_StateOfCharge : 32|8@1+ (1,0) [0|100] "%"  LOGBOX
 SG_ BMS3_ADB_M1_Module_StateOfHealth : 40|8@1+ (1,0) [0|2] "-"  LOGBOX
 SG_ BMS3_ADB_M1_DiscProtectTrigg : 55|1@1+ (1,0) [0|1] "-"  LOGBOX
 SG_ BMS3_ADB_M1_ChargeProtectTrigg : 54|1@1+ (1,0) [0|1] "-"  LOGBOX
 SG_ BMS3_ADB_M1_ModulesMissingFailed : 53|1@1+ (1,0) [0|1] "-"  LOGBOX
 SG_ BMS3_ADB_M1_OverTemp_detect : 52|1@1+ (1,0) [0|1] "-"  LOGBOX
 SG_ BMS3_ADB_M1_UnderVoltage_detect : 51|1@1+ (1,0) [0|1] "-"  LOGBOX
 SG_ BMS3_ADB_M1_OverVoltage_detected : 50|1@1+ (1,0) [0|1] "-"  LOGBOX
 SG_ BMS3_ADB_M1_Overload_detected : 49|1@1+ (1,0) [0|1] "-"  LOGBOX
 SG_ BMS3_ADB_M1_ShortCircuit_detect : 48|1@1+ (1,0) [0|1] "-"  LOGBOX
 SG_ BMS3_ADB_M1_Module_BQ78350 : 56|8@1+ (1,0) [0|2] "-"  LOGBOX

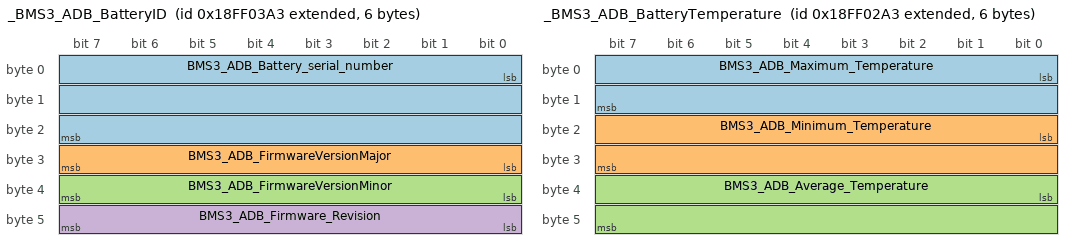
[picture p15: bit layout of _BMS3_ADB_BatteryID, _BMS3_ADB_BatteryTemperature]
BO_ 2566849443 _BMS3_ADB_BatteryID: 6 BMS3_ADB
 SG_ BMS3_ADB_Battery_serial_number : 0|24@1+ (1,0) [0|16777214] "-"  LOGBOX
 SG_ BMS3_ADB_FirmwareVersionMajor : 24|8@1+ (1,0) [0|255] "-"  LOGBOX
 SG_ BMS3_ADB_FirmwareVersionMinor : 32|8@1+ (1,0) [0|255] "-"  LOGBOX
 SG_ BMS3_ADB_Firmware_Revision : 40|8@1+ (1,0) [0|255] "-"  LOGBOX

BO_ 2566849187 _BMS3_ADB_BatteryTemperature: 6 BMS3_ADB
 SG_ BMS3_ADB_Maximum_Temperature : 0|16@1+ (0.1,-100) [-100|200] "°C"  LOGBOX
 SG_ BMS3_ADB_Minimum_Temperature : 16|16@1+ (0.1,-100) [-100|200] "°C"  LOGBOX
 SG_ BMS3_ADB_Average_Temperature : 32|16@1+ (0.1,-100) [-100|200] "°C"  LOGBOX

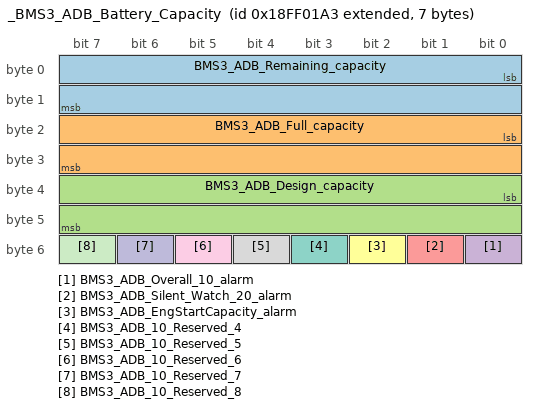
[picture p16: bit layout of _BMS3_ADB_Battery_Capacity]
BO_ 2566848931 _BMS3_ADB_Battery_Capacity: 7 BMS3_ADB
 SG_ BMS3_ADB_Remaining_capacity : 0|16@1+ (0.01,0) [0|642.55] "Ah"  LOGBOX
 SG_ BMS3_ADB_Full_capacity : 16|16@1+ (0.01,0) [0|642.55] "Ah"  LOGBOX
 SG_ BMS3_ADB_Design_capacity : 32|16@1+ (0.01,0) [0|642.55] "Ah"  LOGBOX
 SG_ BMS3_ADB_Overall_10_alarm : 48|1@1+ (1,0) [0|1] "-"  LOGBOX
 SG_ BMS3_ADB_Silent_Watch_20_alarm : 49|1@1+ (1,0) [0|1] "-"  LOGBOX
 SG_ BMS3_ADB_EngStartCapacity_alarm : 50|1@1+ (1,0) [0|1] "-"  LOGBOX
 SG_ BMS3_ADB_10_Reserved_4 : 51|1@1+ (1,0) [0|0] "-"  LOGBOX
 SG_ BMS3_ADB_10_Reserved_5 : 52|1@1+ (1,0) [0|0] "-"  LOGBOX
 SG_ BMS3_ADB_10_Reserved_6 : 53|1@1+ (1,0) [0|0] "-"  LOGBOX
 SG_ BMS3_ADB_10_Reserved_7 : 54|1@1+ (1,0) [0|0] "-"  LOGBOX
 SG_ BMS3_ADB_10_Reserved_8 : 55|1@1+ (1,0) [0|0] "-"  LOGBOX

BO_ 2566848675 _BMS3_ADB_BatteryOperatingParam: 8 BMS3_ADB
 SG_ BMS3_ADB_Batt_OUT_Voltage : 0|16@1+ (0.001,0) [0|64255] "V"  LOGBOX
 SG_ BMS3_ADB_Batt_Average_Current : 16|16@1+ (0.1,-5500) [-5500|925.5] "A"  LOGBOX
 SG_ BMS3_ADB_Batt_StsOfCharge : 32|8@1+ (1,0) [0|100] "%"  LOGBOX
 SG_ BMS3_ADB_Batt_StsOfHealth : 40|8@1+ (1,0) [0|2] "-"  LOGBOX
 SG_ BMS3_ADB_Batt_PS8_discharge_prot : 55|1@1+ (1,0) [0|1] "-"  LOGBOX
 SG_ BMS3_ADB_Batt_PS7_charge_prot : 54|1@1+ (1,0) [0|1] "-"  LOGBOX
 SG_ BMS3_ADB_Batt_PS6_mod_failed : 53|1@1+ (1,0) [0|1] "-"  LOGBOX
 SG_ BMS3_ADB_Batt_PS5_over_temp : 52|1@1+ (1,0) [0|1] "-"  LOGBOX
 SG_ BMS3_ADB_Batt_PS4_under_voltage : 51|1@1+ (1,0) [0|1] "-"  LOGBOX
 SG_ BMS3_ADB_Batt_PS3_over_voltage : 50|1@1+ (1,0) [0|1] "-"  LOGBOX
 SG_ BMS3_ADB_Batt_PS2_overload : 49|1@1+ (1,0) [0|1] "-"  LOGBOX
 SG_ BMS3_ADB_Batt_PS1_short_circuit : 48|1@1+ (1,0) [0|1] "-"  LOGBOX
 SG_ BMS3_ADB_Batt_OS_8_sleep_mode : 63|1@1+ (1,0) [0|1] "-"  LOGBOX
 SG_ BMS3_ADB_Batt_OS_7_emerg_used : 62|1@1+ (1,0) [0|1] "-"  LOGBOX
 SG_ BMS3_ADB_Batt_OS_6_emergency : 61|1@1+ (1,0) [0|1] "-"  LOGBOX
 SG_ BMS3_ADB_Batt_OS_45_charge_level : 59|2@1+ (1,0) [0|3] "-"  LOGBOX
 SG_ BMS3_ADB_Batt_OS_3_charge_cont : 58|1@1+ (1,0) [0|1] "-"  LOGBOX
 SG_ BMS3_ADB_Batt_OS_2_heater_cont : 57|1@1+ (1,0) [0|1] "-"  LOGBOX
 SG_ BMS3_ADB_Batt_OS_1_master_prot : 56|1@1+ (1,0) [0|1] "-"  LOGBOX

BO_ 2566804131 _BMS3_ADB_VEP_3: 8 BMS3_ADB
 SG_ _nu_BMS3_ADB_AlternatorCurrent : 0|16@1+ (0.05,-1600) [-1600|1612.75] "A"  LOGBOX
 SG_ BMS3_ADB_NetBattery_Current : 16|16@1+ (0.05,-1600) [-1600|1612.75] "A"  LOGBOX

BO_ 2566803619 _BMS3_ADB_Battery_1_Temp: 8 BMS3_ADB
 SG_ BMS3_ADB_Battery1_Temperature : 0|8@1+ (1,-40) [-40|210] "°C"  LOGBOX
 SG_ _nu_BMS3_ADB_Battery2_Temp : 8|8@1+ (1,-40) [-40|210] "°C"  LOGBOX

CM_ "Auxiliary data bus";
CM_ BU_ CAMERA_ALL "Telecamera 'fittizia' per simulare 'tutte' le telecamere";
CM_ BU_ ALM_DX "Ammunition loading (right)";
CM_ BU_ ALM_SX "Ammunition loading (left)";
CM_ BU_ CAMERA_DEFAULT "Telecamera in posizione deafult";
CM_ BU_ LOGBOX "Logbox";
CM_ BU_ CAMERA_POS0 "Telecamera in posizione 0";
CM_ BU_ CAMERA_POS1 "Telecamera in posizione 1";
CM_ BU_ CAMERA_POS2 "Telecamera in posizione 2";
CM_ BU_ CAMERA_POS3 "Telecamera in posizione 3";
CM_ BU_ CAMERA_POS4 "Telecamera in posizione 4";
CM_ BU_ CAMERA_POS5 "Telecamera in posizione 5";
CM_ BU_ CAMERA_POS6 "Telecamera in posizione 6";
CM_ BU_ CAMERA_POS7 "Telecamera in posizione 7";
CM_ BU_ SVS "Switch Video System";
CM_ BU_ RUR "Remote Unit Rear (MUX slave)";
CM_ BU_ RUF "Remote Unit Front (MUX slave)";
CM_ BU_ RUC "Remote Unit Central (MUX slave)";
CM_ BU_ BC "Body Computer";
CM_ BU_ _TESTER "Strumento di diagnosi per configurazione telecamere.
Potrà essere sostituito dal BC.";
CM_ BU_ BMS3_ADB "BMS3 (Normal battery)";
CM_ BU_ BMS0_ADB "BMSx (Normal or Extra battery)";
CM_ BU_ BMS4_ADB "BMS4 (Normal battery)";
CM_ BU_ BMS5_ADB "BMS5 (Normal battery)";
CM_ BU_ BMS6_ADB "BMS6 (Normal battery)";
CM_ BO_ 2550223905 "Camera configuration message";
CM_ SG_ 2550223905 BC_GCM_Byte_0 "Should be 0xAA.";
CM_ SG_ 2550223905 BC_GCM_Byte_1 "Should be 0x6B.";
CM_ SG_ 2550223905 BC_GCM_Byte_2 "The PARAM field defines the parameter to configure:
0x88 Set camera to use default control message ID.
0x80 Set camera control message ID according to field CAN_HI and CAN_LOW.
For all PARAM values other than 0x80, CAN_HI and CAN_LOW
are don’t care. Note that the control message ID is not stored to non-volatile memory until a node specific control message with command 'Store control message ID' has been sent. Hence if the store command is not issued before a power reset the camera will startup and use the last stored ID.";
CM_ SG_ 2550223905 BC_GCM_Byte_3 "Reserved, set to 0.";
CM_ SG_ 2550223905 BC_GCM_Byte_4 "Reserved, set to 0.";
CM_ SG_ 2550223905 BC_GCM_Byte_5 "Reserved, set to 0.";
CM_ SG_ 2550223905 BC_GCM_Byte_6a "Reserved, set to 0.";
CM_ SG_ 2550223905 BC_GCM_Byte_6b "3 most significant bits of source’s CAN message ID, should be 0x5.";
CM_ SG_ 2550223905 BC_GCM_Byte_7 "8 last significant bits of source’s CAN message ID, should be in the range 0x80 to 0x87.";
CM_ BO_ 2564432382 "Diagnostic message - used for tester communication";
CM_ SG_ 2564432382 can2_diagrx_0 "Diagnostic signal - used for tester communication";
CM_ SG_ 2564432382 can2_diagrx_1 "Diagnostic signal - used for tester communication";
CM_ SG_ 2564432382 can2_diagrx_2 "Diagnostic signal - used for tester communication";
CM_ SG_ 2564432382 can2_diagrx_3 "Diagnostic signal - used for tester communication";
CM_ SG_ 2564432382 can2_diagrx_4 "Diagnostic signal - used for tester communication";
CM_ SG_ 2564432382 can2_diagrx_5 "Diagnostic signal - used for tester communication";
CM_ SG_ 2564432382 can2_diagrx_6 "Diagnostic signal - used for tester communication";
CM_ SG_ 2564432382 can2_diagrx_7 "Diagnostic signal - used for tester communication";
CM_ BO_ 2564485409 "Diagnostic message - used for tester communication";
CM_ SG_ 2564485409 can2_diagtx_0 "Diagnostic signal - used for tester communication";
CM_ SG_ 2564485409 can2_diagtx_1 "Diagnostic signal - used for tester communication";
CM_ SG_ 2564485409 can2_diagtx_2 "Diagnostic signal - used for tester communication";
CM_ SG_ 2564485409 can2_diagtx_3 "Diagnostic signal - used for tester communication";
CM_ SG_ 2564485409 can2_diagtx_4 "Diagnostic signal - used for tester communication";
CM_ SG_ 2564485409 can2_diagtx_5 "Diagnostic signal - used for tester communication";
CM_ SG_ 2564485409 can2_diagtx_6 "Diagnostic signal - used for tester communication";
CM_ SG_ 2564485409 can2_diagtx_7 "Diagnostic signal - used for tester communication";
CM_ BO_ 2550202258 "Status of right ammunition loading (9 ammunitions)";
CM_ SG_ 2550202258 ALS_DX_POS_12_status "This signal contains the type of ammunition presente in the position 12 of the right ammunition loading.
The configuration used on the C2 application is:

0: EMPTY
1: HE
2: AP
3: MP";
CM_ SG_ 2550202258 ALS_DX_POS_11_status "This signal contains the type of ammunition presente in the position 12 of the right ammunition loading.
The configuration used on the C2 application is:

0: EMPTY
1: HE
2: AP
3: MP";
CM_ SG_ 2550202258 ALS_DX_POS_10_status "This signal contains the type of ammunition presente in the position 12 of the right ammunition loading.
The configuration used on the C2 application is:

0: EMPTY
1: HE
2: AP
3: MP";
CM_ SG_ 2550202258 ALS_DX_POS_09_status "This signal contains the type of ammunition presente in the position 12 of the right ammunition loading.
The configuration used on the C2 application is:

0: EMPTY
1: HE
2: AP
3: MP";
CM_ SG_ 2550202258 ALS_DX_POS_08_status "This signal contains the type of ammunition presente in the position 12 of the right ammunition loading.
The configuration used on the C2 application is:

0: EMPTY
1: HE
2: AP
3: MP";
CM_ SG_ 2550202258 ALS_DX_POS_07_status "This signal contains the type of ammunition presente in the position 12 of the right ammunition loading.
The configuration used on the C2 application is:

0: EMPTY
1: HE
2: AP
3: MP";
CM_ SG_ 2550202258 ALS_DX_POS_06_status "This signal contains the type of ammunition presente in the position 12 of the right ammunition loading.
The configuration used on the C2 application is:

0: EMPTY
1: HE
2: AP
3: MP";
CM_ SG_ 2550202258 ALS_DX_POS_05_status "This signal contains the type of ammunition presente in the position 12 of the right ammunition loading.
The configuration used on the C2 application is:

0: EMPTY
1: HE
2: AP
3: MP";
CM_ SG_ 2550202258 ALS_DX_POS_04_status "This signal contains the type of ammunition presente in the position 12 of the right ammunition loading.
The configuration used on the C2 application is:

0: EMPTY
1: HE
2: AP
3: MP";
CM_ SG_ 2550202258 ALS_DX_POS_03_status "This signal contains the type of ammunition presente in the position 12 of the right ammunition loading.
The configuration used on the C2 application is:

0: EMPTY
1: HE
2: AP
3: MP";
CM_ SG_ 2550202258 ALS_DX_POS_02_status "This signal contains the type of ammunition presente in the position 12 of the right ammunition loading.
The configuration used on the C2 application is:

0: EMPTY
1: HE
2: AP
3: MP";
CM_ SG_ 2550202258 ALS_DX_POS_01_status "This signal contains the type of ammunition presente in the position 12 of the right ammunition loading.
The configuration used on the C2 application is:

0: EMPTY
1: HE
2: AP
3: MP";
CM_ BO_ 2550202257 "Status of left  ammunition loading (10 ammunitions)";
CM_ SG_ 2550202257 ALS_SX_POS_12_status "This signal contains the type of ammunition presente in the position 12 of the right ammunition loading.
The configuration used on the C2 application is:

0: EMPTY
1: HE
2: AP
3: MP";
CM_ SG_ 2550202257 ALS_SX_POS_11_status "This signal contains the type of ammunition presente in the position 12 of the right ammunition loading.
The configuration used on the C2 application is:

0: EMPTY
1: HE
2: AP
3: MP";
CM_ SG_ 2550202257 ALS_SX_POS_10_status "This signal contains the type of ammunition presente in the position 12 of the right ammunition loading.
The configuration used on the C2 application is:

0: EMPTY
1: HE
2: AP
3: MP";
CM_ SG_ 2550202257 ALS_SX_POS_09_status "This signal contains the type of ammunition presente in the position 12 of the right ammunition loading.
The configuration used on the C2 application is:

0: EMPTY
1: HE
2: AP
3: MP";
CM_ SG_ 2550202257 ALS_SX_POS_08_status "This signal contains the type of ammunition presente in the position 12 of the right ammunition loading.
The configuration used on the C2 application is:

0: EMPTY
1: HE
2: AP
3: MP";
CM_ SG_ 2550202257 ALS_SX_POS_07_status "This signal contains the type of ammunition presente in the position 12 of the right ammunition loading.
The configuration used on the C2 application is:

0: EMPTY
1: HE
2: AP
3: MP";
CM_ SG_ 2550202257 ALS_SX_POS_06_status "This signal contains the type of ammunition presente in the position 12 of the right ammunition loading.
The configuration used on the C2 application is:

0: EMPTY
1: HE
2: AP
3: MP";
CM_ SG_ 2550202257 ALS_SX_POS_05_status "This signal contains the type of ammunition presente in the position 12 of the right ammunition loading.
The configuration used on the C2 application is:

0: EMPTY
1: HE
2: AP
3: MP";
CM_ SG_ 2550202257 ALS_SX_POS_04_status "This signal contains the type of ammunition presente in the position 12 of the right ammunition loading.
The configuration used on the C2 application is:

0: EMPTY
1: HE
2: AP
3: MP";
CM_ SG_ 2550202257 ALS_SX_POS_03_status "This signal contains the type of ammunition presente in the position 12 of the right ammunition loading.
The configuration used on the C2 application is:

0: EMPTY
1: HE
2: AP
3: MP";
CM_ SG_ 2550202257 ALS_SX_POS_02_status "This signal contains the type of ammunition presente in the position 12 of the right ammunition loading.
The configuration used on the C2 application is:

0: EMPTY
1: HE
2: AP
3: MP";
CM_ SG_ 2550202257 ALS_SX_POS_01_status "This signal contains the type of ammunition presente in the position 12 of the right ammunition loading.
The configuration used on the C2 application is:

0: EMPTY
1: HE
2: AP
3: MP";
CM_ BO_ 2550210900 "Turret information (coming from the turret)";
CM_ SG_ 2550210900 SVS_Turret_Angle "The signal define the current Turret Angle (coming from the turret).";
CM_ SG_ 2550210900 SVS_Turret_Hatch_Right_Status "The signal define the current Turret Right Hatch Status (coming from the turret).";
CM_ SG_ 2550210900 SVS_Turret_Hatch_Left_Status "The signal define the current Turret Left Hatch Status (coming from the turret).";
CM_ SG_ 2550210900 SVS_Battle_Short_Status "The signal define the current Battle Short Status (coming from the turret).";
CM_ BO_ 2559071265 "SVS configuration message";
CM_ SG_ 2559071265 ALS_Configuration "This signal indicates the ALS configuration installed on the vehicle";
CM_ SG_ 2559071265 TLC_07_used_by_driver "This signal indicates that the camera is used by the driver";
CM_ SG_ 2559071265 TLC_06_used_by_driver "This signal indicates that the camera is used by the driver";
CM_ SG_ 2559071265 TLC_05_used_by_driver "This signal indicates that the camera is used by the driver";
CM_ SG_ 2559071265 TLC_04_used_by_driver "This signal indicates that the camera is used by the driver";
CM_ SG_ 2559071265 TLC_03_used_by_driver "This signal indicates that the camera is used by the driver";
CM_ SG_ 2559071265 TLC_02_used_by_driver "This signal indicates that the camera is used by the driver";
CM_ SG_ 2559071265 TLC_01_used_by_driver "This signal indicates that the camera is used by the driver";
CM_ SG_ 2559071265 TLC_00_used_by_driver "This signal indicates that the camera is used by the driver";
CM_ SG_ 2559071265 TypeOfVideoSignal_Output "This signal indicates the type of the composite video signal to be used.
The allowed values are:";
CM_ SG_ 2559071265 VideoSignal1 "This signal indicates the first input channel to be used for the 'double monitor' composite immage.";
CM_ SG_ 2559071265 VideoSignal0 "This signal indicates the second input channel to be used for the 'double monitor' composite immage.";
CM_ BO_ 2559005729 "SVS configuration message";
CM_ SG_ 2559005729 InputType_15 "This signal indicates the type of the input to be used for the selected SVS output.
The allowed values are:
- INPUT_CAMERA
- NOT_CONNECTED";
CM_ SG_ 2559005729 InputType_14 "This signal indicates the type of the input to be used for the selected SVS output.
The allowed values are:
- INPUT_CAMERA
- NOT_CONNECTED";
CM_ SG_ 2559005729 InputType_13 "This signal indicates the type of the input to be used for the selected SVS output.
The allowed values are:
- INPUT_CAMERA
- NOT_CONNECTED";
CM_ SG_ 2559005729 InputType_12 "This signal indicates the type of the input to be used for the selected SVS output.
The allowed values are:
- INPUT_CAMERA
- NOT_CONNECTED";
CM_ SG_ 2559005729 InputType_11 "This signal indicates the type of the input to be used for the selected SVS output.
The allowed values are:
- INPUT_CAMERA
- NOT_CONNECTED";
CM_ SG_ 2559005729 InputType_10 "This signal indicates the type of the input to be used for the selected SVS output.
The allowed values are:
- INPUT_CAMERA
- NOT_CONNECTED";
CM_ SG_ 2559005729 InputType_09 "This signal indicates the type of the input to be used for the selected SVS output.
The allowed values are:
- INPUT_CAMERA
- NOT_CONNECTED";
CM_ SG_ 2559005729 InputType_08 "This signal indicates the type of the input to be used for the selected SVS output.
The allowed values are:
- INPUT_CAMERA
- NOT_CONNECTED";
CM_ SG_ 2559005729 CameraInput_15 "This signal indicates the camera to be connected to the SVS output N#15";
CM_ SG_ 2559005729 CameraInput_14 "This signal indicates the camera to be connected to the SVS output n#14";
CM_ SG_ 2559005729 CameraInput_13 "This signal indicates the camera to be connected to the SVS output n#13";
CM_ SG_ 2559005729 CameraInput_12 "This signal indicates the camera to be connected to the SVS output n#12";
CM_ SG_ 2559005729 CameraInput_11 "This signal indicates the camera to be connected to the SVS output n#11";
CM_ SG_ 2559005729 CameraInput_10 "This signal indicates the camera to be connected to the SVS output n#10";
CM_ SG_ 2559005729 CameraInput_09 "This signal indicates the camera to be connected to the SVS output n#09";
CM_ SG_ 2559005729 CameraInput_08 "This signal indicates the camera to be connected to the SVS output n#08";
CM_ BO_ 2558940193 "SVS configuration message";
CM_ SG_ 2558940193 InputType_07 "This signal indicates the type of the input to be used for the selected SVS output.
The allowed values are:
- INPUT_CAMERA
- NOT_CONNECTED";
CM_ SG_ 2558940193 InputType_06 "This signal indicates the type of the input to be used for the selected SVS output.
The allowed values are:
- INPUT_CAMERA
- NOT_CONNECTED";
CM_ SG_ 2558940193 InputType_05 "This signal indicates the type of the input to be used for the selected SVS output.
The allowed values are:
- INPUT_CAMERA
- NOT_CONNECTED";
CM_ SG_ 2558940193 InputType_04 "This signal indicates the type of the input to be used for the selected SVS output.
The allowed values are:
- INPUT_CAMERA
- NOT_CONNECTED";
CM_ SG_ 2558940193 InputType_03 "This signal indicates the type of the input to be used for the selected SVS output.
The allowed values are:
- INPUT_CAMERA
- NOT_CONNECTED";
CM_ SG_ 2558940193 InputType_02 "This signal indicates the type of the input to be used for the selected SVS output.
The allowed values are:
- INPUT_CAMERA
- NOT_CONNECTED";
CM_ SG_ 2558940193 InputType_01 "This signal indicates the type of the input to be used for the selected SVS output.
The allowed values are:
- INPUT_CAMERA
- NOT_CONNECTED";
CM_ SG_ 2558940193 InputType_00 "This signal indicates the type of the input to be used for the selected SVS output.
The allowed values are:
- INPUT_CAMERA
- NOT_CONNECTED";
CM_ SG_ 2558940193 CameraInput_07 "This signal indicates the camera to be connected to the SVS output n#07";
CM_ SG_ 2558940193 CameraInput_06 "This signal indicates the camera to be connected to the SVS output n#06";
CM_ SG_ 2558940193 CameraInput_05 "This signal indicates the camera to be connected to the SVS output n#05";
CM_ SG_ 2558940193 CameraInput_04 "This signal indicates the camera to be connected to the SVS output n#04";
CM_ SG_ 2558940193 CameraInput_03 "This signal indicates the camera to be connected to the SVS output n#03";
CM_ SG_ 2558940193 CameraInput_02 "This signal indicates the camera to be connected to the SVS output n#02";
CM_ SG_ 2558940193 CameraInput_01 "This signal indicates the camera to be connected to the SVS output n#01";
CM_ SG_ 2558940193 CameraInput_00 "This signal indicates the camera to be connected to the SVS output n#00";
CM_ BO_ 2632777505 "Diagnostic message - used for tester communication";
CM_ SG_ 2632777505 can2_tpcm_byte0 "Diagnostic signal - used for tester communication";
CM_ SG_ 2632777505 can2_tpcm_byte1 "Diagnostic signal - used for tester communication";
CM_ SG_ 2632777505 can2_tpcm_byte2 "Diagnostic signal - used for tester communication";
CM_ SG_ 2632777505 can2_tpcm_byte3 "Diagnostic signal - used for tester communication";
CM_ SG_ 2632777505 can2_tpcm_byte4 "Diagnostic signal - used for tester communication";
CM_ SG_ 2632777505 can2_tpcm_byte5 "Diagnostic signal - used for tester communication";
CM_ SG_ 2632777505 can2_tpcm_byte6 "Diagnostic signal - used for tester communication";
CM_ SG_ 2632777505 can2_tpcm_byte7 "Diagnostic signal - used for tester communication";
CM_ BO_ 2632711969 "Diagnostic message - used for tester communication";
CM_ SG_ 2632711969 can2_tpdt_byte0 "Diagnostic signal - used for tester communication";
CM_ SG_ 2632711969 can2_tpdt_byte1 "Diagnostic signal - used for tester communication";
CM_ SG_ 2632711969 can2_tpdt_byte2 "Diagnostic signal - used for tester communication";
CM_ SG_ 2632711969 can2_tpdt_byte3 "Diagnostic signal - used for tester communication";
CM_ SG_ 2632711969 can2_tpdt_byte4 "Diagnostic signal - used for tester communication";
CM_ SG_ 2632711969 can2_tpdt_byte5 "Diagnostic signal - used for tester communication";
CM_ SG_ 2632711969 can2_tpdt_byte6 "Diagnostic signal - used for tester communication";
CM_ SG_ 2632711969 can2_tpdt_byte7 "Diagnostic signal - used for tester communication";
CM_ BO_ 2550145364 "Camera status message";
CM_ SG_ 2550145364 SVS_IN_31_status "This signal indicate the input channel status";
CM_ SG_ 2550145364 SVS_IN_30_status "This signal indicate the input channel status";
CM_ SG_ 2550145364 SVS_IN_29_status "This signal indicate the input channel status";
CM_ SG_ 2550145364 SVS_IN_28_status "This signal indicate the input channel status";
CM_ SG_ 2550145364 SVS_IN_27_status "This signal indicate the input channel status";
CM_ SG_ 2550145364 SVS_IN_26_status "This signal indicate the input channel status";
CM_ SG_ 2550145364 SVS_IN_25_status "This signal indicate the input channel status";
CM_ SG_ 2550145364 SVS_IN_24_status "This signal indicate the input channel status";
CM_ SG_ 2550145364 SVS_IN_23_status "This signal indicate the input channel status";
CM_ SG_ 2550145364 SVS_IN_22_status "This signal indicate the input channel status";
CM_ SG_ 2550145364 SVS_IN_21_status "This signal indicate the input channel status";
CM_ SG_ 2550145364 SVS_IN_20_status "This signal indicate the input channel status";
CM_ SG_ 2550145364 SVS_IN_19_status "This signal indicate the input channel status";
CM_ SG_ 2550145364 SVS_IN_18_status "This signal indicate the input channel status";
CM_ SG_ 2550145364 SVS_IN_17_status "This signal indicate the input channel status";
CM_ SG_ 2550145364 SVS_IN_16_status "This signal indicate the input channel status";
CM_ SG_ 2550145364 SVS_IN_15_status "This signal indicate the input channel status";
CM_ SG_ 2550145364 SVS_IN_14_status "This signal indicate the input channel status";
CM_ SG_ 2550145364 SVS_IN_13_status "This signal indicate the input channel status";
CM_ SG_ 2550145364 SVS_IN_12_status "This signal indicate the input channel status";
CM_ SG_ 2550145364 SVS_IN_11_status "This signal indicate the input channel status";
CM_ SG_ 2550145364 SVS_IN_10_status "This signal indicate the input channel status";
CM_ SG_ 2550145364 SVS_IN_09_status "This signal indicate the input channel status";
CM_ SG_ 2550145364 SVS_IN_08_status "This signal indicate the input channel status";
CM_ SG_ 2550145364 SVS_IN_07_status "This signal indicate the input channel status";
CM_ SG_ 2550145364 SVS_IN_06_status "This signal indicate the input channel status";
CM_ SG_ 2550145364 SVS_IN_05_status "This signal indicate the input channel status";
CM_ SG_ 2550145364 SVS_IN_04_status "This signal indicate the input channel status";
CM_ SG_ 2550145364 SVS_IN_03_status "This signal indicate the input channel status";
CM_ SG_ 2550145364 SVS_IN_02_status "This signal indicate the input channel status";
CM_ SG_ 2550145364 SVS_IN_01_status "This signal indicate the input channel status";
CM_ SG_ 2550145364 SVS_IN_00_status "This signal indicate the input channel status";
CM_ BO_ 2550158369 "Camera control message";
CM_ SG_ 2550158369 CCBC_Reserved_02 "Reserved for future use";
CM_ SG_ 2550158369 CCBC_DCAM_Preset "This signal indicates the selected Day camera preset referred to lighting (LUX value setting). ";
CM_ SG_ 2550158369 CCBC_TI_NUC_mode_reset_p1 "This signal indicates the NUC (NON UNIFORMITY CORRECTION) status of the selected camera";
CM_ SG_ 2550158369 CCBC_ProtectiveLid "This signal indicates the PROTECTIVE LID status of the selected camera";
CM_ SG_ 2550158369 CCBC_VideoSource_ch0 "This signal indicates the requested camera mode for channel 0.";
CM_ SG_ 2550158369 CCBC_TI_DDE "This signal indicates the DDE status of the selected camera";
CM_ SG_ 2550158369 CCBC_HorizontalFlip "This signal indicates the MIRRORING status of the selected camera";
CM_ SG_ 2550158369 CCBC_OverlayGraphics "This signal indicates the OVERLAY status of the selected camera";
CM_ SG_ 2550158369 CCBC_VideoSource_ch1 "Reserved for future use";
CM_ SG_ 2550158369 CCBC_TI_Polarity "This signal indicates the POLARITY (WHITE HOT or BLACK HOT) status of the selected camera";
CM_ SG_ 2550158369 CCBC_TI_Zoom "This signal indicates the Thermal Zoom status of the selected camera.
Note: the DCAM camera has no zoom.";
CM_ SG_ 2550158369 CCBC_TI_ROI "This signal indicates the ROI (Region of Interest) status of the selected camera.
The region of interest could have the following values:
- TOP HALF
- CENTER BLOCK
- BOTTOM HALF
- FULL SCREEN";
CM_ SG_ 2550158369 CCBC_VideoBlending_ch0 "This signal indicates the Blending  status of the channel 0 of the selected camera.";
CM_ SG_ 2550158369 CCBC_Reserved_01 "Reserved for future use";
CM_ SG_ 2550158369 CCBC_TI_NUC_mode_reset_p2 "This signal is used to disable the automatic NUC.";
CM_ SG_ 2550158369 CCBC_WindowHeaters "This signal indicates the Window heater status of the selected camera
";
CM_ SG_ 2550158369 CCBC_TLC_07_Requested "This signal indicates the cameras that have to receive the specific BC command";
CM_ SG_ 2550158369 CCBC_TLC_06_Requested "This signal indicates the cameras that have to receive the specific BC command";
CM_ SG_ 2550158369 CCBC_TLC_05_Requested "This signal indicates the cameras that have to receive the specific BC command";
CM_ SG_ 2550158369 CCBC_TLC_04_Requested "This signal indicates the cameras that have to receive the specific BC command";
CM_ SG_ 2550158369 CCBC_TLC_03_Requested "This signal indicates the cameras that have to receive the specific BC command";
CM_ SG_ 2550158369 CCBC_TLC_02_Requested "This signal indicates the cameras that have to receive the specific BC command";
CM_ SG_ 2550158369 CCBC_TLC_01_Requested "This signal indicates the cameras that have to receive the specific BC command";
CM_ SG_ 2550158369 CCBC_TLC_00_Requested "This signal indicates the cameras that have to receive the specific BC command";
CM_ SG_ 2550158369 CCBC_Reserved_03 "Reserved for future use";
CM_ SG_ 2550158369 CCBC_Reserved_04 "Reserved for future use";
CM_ BO_ 2015 "Camera information message";
CM_ SG_ 2015 IM_VideoSource_ch1 "This signal indicates the camera mode for channel 1. ";
CM_ SG_ 2015 IM_CameraPosition "Status of the selected camera.";
CM_ SG_ 2015 IM_Reserved_01 "Reserved for future use";
CM_ SG_ 2015 IM_ImageBlending_Available "This signal indicates the Blending  status of the channel 0 of the selected camera (Available or not available).";
CM_ SG_ 2015 IM_Reserved_02 "Reserved for future use";
CM_ SG_ 2015 IM_DCAM_Available "Status of the selected camera.";
CM_ SG_ 2015 IM_TI_Available "Status of the selected camera.";
CM_ SG_ 2015 IM_Reserved_03 "Reserved for future use";
CM_ SG_ 2015 IM_msgID_msb "Status of the selected camera.";
CM_ SG_ 2015 IM_Reserved_04 "Reserved for future use";
CM_ SG_ 2015 IM_msgID_lsb "Status of the selected camera.";
CM_ SG_ 2015 IM_FieldOfView "Status of the selected camera.";
CM_ SG_ 2015 IM_Humidity_TooHigh "Status of the selected camera.";
CM_ SG_ 2015 IM_Temperature_TooHigh "Status of the selected camera.";
CM_ SG_ 2015 IM_POST_Failed "Status of the selected camera.";
CM_ SG_ 2015 IM_Reserved_05 "Reserved for future use";
CM_ SG_ 2015 IM_TI_Zoom "This signal indicates the Thermal Zoom status of the selected camera.
Note: the DCAM camera has no zoom.";
CM_ SG_ 2015 IM_VideoHeaters "This signal indicates the Window heater status of the selected camera
";
CM_ SG_ 2015 IM_HorizontalFlip "This signal indicates the MIRRORING status of the selected camera";
CM_ SG_ 2015 IM_NUC "This signal indicates the NUC (NON UNIFORMITY CORRECTION) status of the selected camera";
CM_ SG_ 2015 IM_VideoBlendingMode "This signal indicates the Blending  status of the channel 0 of the selected camera.";
CM_ SG_ 2015 IM_DCAM_Preset "Reserved for future use";
CM_ SG_ 2015 IM_ProtectiveLid "This signal indicates the PROTECTIVE LID status of the selected camera";
CM_ SG_ 2015 IM_VideoSource_ch0 "This signal indicates the camera mode for output channel 0. ";
CM_ SG_ 2015 IM_PAL_Stretch "Status of the selected camera.";
CM_ SG_ 2015 IM_TI_DDE "This signal indicates the DDE status of the selected camera";
CM_ SG_ 2015 IM_OverlayGraphic "This signal indicates the OVERLAY status of the selected camera";
CM_ SG_ 2015 IM_ROI "This signal indicates the ROI (Region of Interest) status of the selected camera.
The region of interest could have the following values:
- TOP HALF
- CENTER BLOCK
- BOTTOM HALF
- FULL SCREEN";
CM_ SG_ 2015 IM_TI_Polarity "This signal indicates the POLARITY (WHITE HOT or BLACK HOT) status of the selected camera";
CM_ BO_ 1416 "Camera control message";
CM_ SG_ 1416 CCD_Reserved_02 "Reserved for future use";
CM_ SG_ 1416 CCD_DCAM_Preset "This signal indicates the selected Day Camera LUX setting for the Camera Control..";
CM_ SG_ 1416 CCD_TI_NUC_mode_reset_p1 "This signal indicates the NUC (NON UNIFORMITY CORRECTION) status of the selected camera";
CM_ SG_ 1416 CCD_ProtectiveLid "This signal indicates the PROTECTIVE LID status of the selected camera";
CM_ SG_ 1416 CCD_VideoSource_ch0 "This signal indicates the requested camera mode for channel 0, default camera.";
CM_ SG_ 1416 CCD_TI_DDE "This signal indicates the DDE status of the selected camera";
CM_ SG_ 1416 CCD_HorizontalFlip "This signal indicates the MIRRORING status of the selected camera";
CM_ SG_ 1416 CCD_OverlayGraphics "This signal indicates the OVERLAY status of the selected camera";
CM_ SG_ 1416 CCD_VideoSource_ch1 "This signal indicates the requested camera mode for channel 1.";
CM_ SG_ 1416 CCD_TI_Polarity "This signal indicates the POLARITY (WHITE HOT or BLACK HOT) status of the selected camera";
CM_ SG_ 1416 CCD_TI_Zoom "This signal indicates the Thermal Zoom status of the selected camera.
Note: the DCAM camera has no zoom.";
CM_ SG_ 1416 CCD_TI_ROI "This signal indicates the ROI (Region of Interest) status of the selected camera.
The region of interest could have the following values:
- TOP HALF
- CENTER BLOCK
- BOTTOM HALF
- FULL SCREEN";
CM_ SG_ 1416 CCD_VideoBlending_ch0 "This signal indicates the Blending  status of the channel 0 of the selected camera.";
CM_ SG_ 1416 CCD_Reserved_03 "Reserved for future use";
CM_ SG_ 1416 CCD_TI_NUC_mode_reset_p2 "This signal is used to disable the automatic NUC.";
CM_ SG_ 1416 CCD_WindowHeaters "This signal indicates the Window heater status of the selected camera
";
CM_ SG_ 1416 CCD_Reserved_04 "Reserved for future use";
CM_ SG_ 1416 CCD_Reserved_05 "Reserved for future use";
CM_ SG_ 1416 CCD_Reserved_06 "Reserved for future use";
CM_ BO_ 1415 "Camera control message";
CM_ SG_ 1415 CC7_Reserved_02 "Reserved for future use";
CM_ SG_ 1415 CC7_DCAM_Preset "This signal indicates the selected Day Camera LUX setting for the Camera 7.";
CM_ SG_ 1415 CC7_TI_NUC_mode_reset_p1 "This signal indicates the NUC (NON UNIFORMITY CORRECTION) status of the selected camera";
CM_ SG_ 1415 CC7_ProtectiveLid "This signal indicates the PROTECTIVE LID status of the selected camera";
CM_ SG_ 1415 CC7_VideoSource_ch0 "This signal indicates the requested camera mode for channel 0, camera 7.";
CM_ SG_ 1415 CC7_TI_DDE "This signal indicates the DDE status of the selected camera";
CM_ SG_ 1415 CC7_HorizontalFlip "This signal indicates the MIRRORING status of the selected camera";
CM_ SG_ 1415 CC7_OverlayGraphics "This signal indicates the OVERLAY status of the selected camera";
CM_ SG_ 1415 CC7_VideoSource_ch1 "This signal indicates the requested camera mode for channel 1.";
CM_ SG_ 1415 CC7_TI_Polarity "This signal indicates the POLARITY (WHITE HOT or BLACK HOT) status of the selected camera";
CM_ SG_ 1415 CC7_TI_Zoom "This signal indicates the Thermal Zoom status of the selected camera.
Note: the DCAM camera has no zoom.";
CM_ SG_ 1415 CC7_TI_ROI "This signal indicates the ROI (Region of Interest) status of the selected camera.
The region of interest could have the following values:
- TOP HALF
- CENTER BLOCK
- BOTTOM HALF
- FULL SCREEN";
CM_ SG_ 1415 CC7_VideoBlending_ch0 "This signal indicates the Blending  status of the channel 0 of the selected camera.";
CM_ SG_ 1415 CC7_Reserved_03 "Reserved for future use";
CM_ SG_ 1415 CC7_TI_NUC_mode_reset_p2 "This signal is used to disable the automatic NUC.";
CM_ SG_ 1415 CC7_WindowHeaters "This signal indicates the Window heater status of the selected camera
";
CM_ SG_ 1415 CC7_Reserved_04 "Reserved for future use";
CM_ SG_ 1415 CC7_Reserved_05 "Reserved for future use";
CM_ SG_ 1415 CC7_Reserved_06 "Reserved for future use";
CM_ BO_ 1414 "Camera control message";
CM_ SG_ 1414 CC6_Reserved_02 "Reserved for future use";
CM_ SG_ 1414 CC6_DCAM_Preset "This signal indicates the selected Day Camera LUX setting for the Camera 6.";
CM_ SG_ 1414 CC6_TI_NUC_mode_reset_p1 "This signal indicates the NUC (NON UNIFORMITY CORRECTION) status of the selected camera";
CM_ SG_ 1414 CC6_ProtectiveLid "This signal indicates the PROTECTIVE LID status of the selected camera";
CM_ SG_ 1414 CC6_VideoSource_ch0 "This signal indicates the requested camera mode for channel 0, camera 6.";
CM_ SG_ 1414 CC6_TI_DDE "This signal indicates the DDE status of the selected camera";
CM_ SG_ 1414 CC6_HorizontalFlip "This signal indicates the MIRRORING status of the selected camera";
CM_ SG_ 1414 CC6_OverlayGraphics "This signal indicates the OVERLAY status of the selected camera";
CM_ SG_ 1414 CC6_VideoSource_ch1 "This signal indicates the requested camera mode for channel 1.";
CM_ SG_ 1414 CC6_TI_Polarity "This signal indicates the POLARITY (WHITE HOT or BLACK HOT) status of the selected camera";
CM_ SG_ 1414 CC6_TI_Zoom "This signal indicates the Thermal Zoom status of the selected camera.
Note: the DCAM camera has no zoom.";
CM_ SG_ 1414 CC6_TI_ROI "This signal indicates the ROI (Region of Interest) status of the selected camera.
The region of interest could have the following values:
- TOP HALF
- CENTER BLOCK
- BOTTOM HALF
- FULL SCREEN";
CM_ SG_ 1414 CC6_VideoBlending_ch0 "This signal indicates the Blending  status of the channel 0 of the selected camera.";
CM_ SG_ 1414 CC6_Reserved_03 "Reserved for future use";
CM_ SG_ 1414 CC6_TI_NUC_mode_reset_p2 "This signal is used to disable the automatic NUC.";
CM_ SG_ 1414 CC6_WindowHeaters "This signal indicates the Window heater status of the selected camera
";
CM_ SG_ 1414 CC6_Reserved_04 "Reserved for future use";
CM_ SG_ 1414 CC6_Reserved_05 "Reserved for future use";
CM_ SG_ 1414 CC6_Reserved_06 "Reserved for future use";
CM_ BO_ 1413 "Camera control message";
CM_ SG_ 1413 CC5_Reserved_02 "Reserved for future use";
CM_ SG_ 1413 CC5_DCAM_Preset "This signal indicates the selected Day Camera LUX setting for the Camera 5.";
CM_ SG_ 1413 CC5_TI_NUC_mode_reset_p1 "This signal indicates the NUC (NON UNIFORMITY CORRECTION) status of the selected camera";
CM_ SG_ 1413 CC5_ProtectiveLid "This signal indicates the PROTECTIVE LID status of the selected camera";
CM_ SG_ 1413 CC5_VideoSource_ch0 "This signal indicates the requested camera mode for channel 0, camera 5.";
CM_ SG_ 1413 CC5_TI_DDE "This signal indicates the DDE status of the selected camera";
CM_ SG_ 1413 CC5_HorizontalFlip "This signal indicates the MIRRORING status of the selected camera";
CM_ SG_ 1413 CC5_OverlayGraphics "This signal indicates the OVERLAY status of the selected camera";
CM_ SG_ 1413 CC5_VideoSource_ch1 "This signal indicates the requested camera mode for channel 1.";
CM_ SG_ 1413 CC5_TI_Polarity "This signal indicates the POLARITY (WHITE HOT or BLACK HOT) status of the selected camera";
CM_ SG_ 1413 CC5_TI_Zoom "This signal indicates the Thermal Zoom status of the selected camera.
Note: the DCAM camera has no zoom.";
CM_ SG_ 1413 CC5_TI_ROI "This signal indicates the ROI (Region of Interest) status of the selected camera.
The region of interest could have the following values:
- TOP HALF
- CENTER BLOCK
- BOTTOM HALF
- FULL SCREEN";
CM_ SG_ 1413 CC5_VideoBlending_ch0 "This signal indicates the Blending  status of the channel 0 of the selected camera.";
CM_ SG_ 1413 CC5_Reserved_03 "Reserved for future use";
CM_ SG_ 1413 CC5_TI_NUC_mode_reset_p2 "This signal is used to disable the automatic NUC.";
CM_ SG_ 1413 CC5_WindowHeaters "This signal indicates the Window heater status of the selected camera
";
CM_ SG_ 1413 CC5_Reserved_04 "Reserved for future use";
CM_ SG_ 1413 CC5_Reserved_05 "Reserved for future use";
CM_ SG_ 1413 CC5_Reserved_06 "Reserved for future use";
CM_ BO_ 1412 "Camera control message";
CM_ SG_ 1412 CC4_Reserved_02 "Reserved for future use";
CM_ SG_ 1412 CC4_DCAM_Preset "This signal indicates the selected Day Camera LUX setting for the Camera 4.";
CM_ SG_ 1412 CC4_TI_NUC_mode_reset_p1 "This signal indicates the NUC (NON UNIFORMITY CORRECTION) status of the selected camera";
CM_ SG_ 1412 CC4_ProtectiveLid "This signal indicates the PROTECTIVE LID status of the selected camera";
CM_ SG_ 1412 CC4_VideoSource_ch0 "This signal indicates the requested camera mode for channel 0, camera 4.";
CM_ SG_ 1412 CC4_TI_DDE "This signal indicates the DDE status of the selected camera";
CM_ SG_ 1412 CC4_HorizontalFlip "This signal indicates the MIRRORING status of the selected camera";
CM_ SG_ 1412 CC4_OverlayGraphics "This signal indicates the OVERLAY status of the selected camera";
CM_ SG_ 1412 CC4_VideoSource_ch1 "This signal indicates the requested camera mode for channel 1.";
CM_ SG_ 1412 CC4_TI_Polarity "This signal indicates the POLARITY (WHITE HOT or BLACK HOT) status of the selected camera";
CM_ SG_ 1412 CC4_TI_Zoom "This signal indicates the Thermal Zoom status of the selected camera.
Note: the DCAM camera has no zoom.";
CM_ SG_ 1412 CC4_TI_ROI "This signal indicates the ROI (Region of Interest) status of the selected camera.
The region of interest could have the following values:
- TOP HALF
- CENTER BLOCK
- BOTTOM HALF
- FULL SCREEN";
CM_ SG_ 1412 CC4_VideoBlending_ch0 "This signal indicates the Blending  status of the channel 0 of the selected camera.";
CM_ SG_ 1412 CC4_Reserved_03 "Reserved for future use";
CM_ SG_ 1412 CC4_TI_NUC_mode_reset_p2 "This signal is used to disable the automatic NUC.";
CM_ SG_ 1412 CC4_WindowHeaters "This signal indicates the Window heater status of the selected camera
";
CM_ SG_ 1412 CC4_Reserved_04 "Reserved for future use";
CM_ SG_ 1412 CC4_Reserved_05 "Reserved for future use";
CM_ SG_ 1412 CC4_Reserved_06 "Reserved for future use";
CM_ BO_ 1411 "Camera control message";
CM_ SG_ 1411 CC3_Reserved_02 "Reserved for future use";
CM_ SG_ 1411 CC3_DCAM_Preset "This signal indicates the selected Day Camera LUX setting for the Camera 3.";
CM_ SG_ 1411 CC3_TI_NUC_mode_reset_p1 "This signal indicates the NUC (NON UNIFORMITY CORRECTION) status of the selected camera";
CM_ SG_ 1411 CC3_ProtectiveLid "This signal indicates the PROTECTIVE LID status of the selected camera";
CM_ SG_ 1411 CC3_VideoSource_ch0 "This signal indicates the requested camera mode for channel 0, camera 3.";
CM_ SG_ 1411 CC3_TI_DDE "This signal indicates the DDE status of the selected camera";
CM_ SG_ 1411 CC3_HorizontalFlip "This signal indicates the MIRRORING status of the selected camera";
CM_ SG_ 1411 CC3_OverlayGraphics "This signal indicates the OVERLAY status of the selected camera";
CM_ SG_ 1411 CC3_VideoSource_ch1 "This signal indicates the requested camera mode for channel 1.";
CM_ SG_ 1411 CC3_TI_Polarity "This signal indicates the POLARITY (WHITE HOT or BLACK HOT) status of the selected camera";
CM_ SG_ 1411 CC3_TI_Zoom "This signal indicates the Thermal Zoom status of the selected camera.
Note: the DCAM camera has no zoom.";
CM_ SG_ 1411 CC3_TI_ROI "This signal indicates the ROI (Region of Interest) status of the selected camera.
The region of interest could have the following values:
- TOP HALF
- CENTER BLOCK
- BOTTOM HALF
- FULL SCREEN";
CM_ SG_ 1411 CC3_VideoBlending_ch0 "This signal indicates the Blending  status of the channel 0 of the selected camera.";
CM_ SG_ 1411 CC3_Reserved_03 "Reserved for future use";
CM_ SG_ 1411 CC3_TI_NUC_mode_reset_p2 "This signal is used to disable the automatic NUC.";
CM_ SG_ 1411 CC3_WindowHeaters "This signal indicates the Window heater status of the selected camera
";
CM_ SG_ 1411 CC3_Reserved_04 "Reserved for future use";
CM_ SG_ 1411 CC3_Reserved_05 "Reserved for future use";
CM_ SG_ 1411 CC3_Reserved_06 "Reserved for future use";
CM_ BO_ 1410 "Camera control message";
CM_ SG_ 1410 CC2_Reserved_02 "Reserved for future use";
CM_ SG_ 1410 CC2_DCAM_Preset "This signal indicates the selected Day Camera LUX setting for the Camera 2.";
CM_ SG_ 1410 CC2_TI_NUC_mode_reset_p1 "This signal indicates the NUC (NON UNIFORMITY CORRECTION) status of the selected camera";
CM_ SG_ 1410 CC2_ProtectiveLid "This signal indicates the PROTECTIVE LID status of the selected camera";
CM_ SG_ 1410 CC2_VideoSource_ch0 "This signal indicates the requested camera mode for channel 0, camera 2.";
CM_ SG_ 1410 CC2_TI_DDE "This signal indicates the DDE status of the selected camera";
CM_ SG_ 1410 CC2_HorizontalFlip "This signal indicates the MIRRORING status of the selected camera";
CM_ SG_ 1410 CC2_OverlayGraphics "This signal indicates the OVERLAY status of the selected camera";
CM_ SG_ 1410 CC2_VideoSource_ch1 "This signal indicates the requested camera mode for channel 1.";
CM_ SG_ 1410 CC2_TI_Polarity "This signal indicates the POLARITY (WHITE HOT or BLACK HOT) status of the selected camera";
CM_ SG_ 1410 CC2_TI_Zoom "This signal indicates the Thermal Zoom status of the selected camera.
Note: the DCAM camera has no zoom.";
CM_ SG_ 1410 CC2_TI_ROI "This signal indicates the ROI (Region of Interest) status of the selected camera.
The region of interest could have the following values:
- TOP HALF
- CENTER BLOCK
- BOTTOM HALF
- FULL SCREEN";
CM_ SG_ 1410 CC2_VideoBlending_ch0 "This signal indicates the Blending  status of the channel 0 of the selected camera.";
CM_ SG_ 1410 CC2_Reserved_03 "Reserved for future use";
CM_ SG_ 1410 CC2_TI_NUC_mode_reset_p2 "This signal is used to disable the automatic NUC.";
CM_ SG_ 1410 CC2_WindowHeaters "This signal indicates the Window heater status of the selected camera
";
CM_ SG_ 1410 CC2_Reserved_04 "Reserved for future use";
CM_ SG_ 1410 CC2_Reserved_05 "Reserved for future use";
CM_ SG_ 1410 CC2_Reserved_06 "Reserved for future use";
CM_ BO_ 1409 "Camera control message";
CM_ SG_ 1409 CC1_Reserved_02 "Reserved for future use";
CM_ SG_ 1409 CC1_DCAM_Preset "This signal indicates the selected Day Camera LUX setting for the Camera 1.";
CM_ SG_ 1409 CC1_TI_NUC_mode_reset_p1 "This signal indicates the NUC (NON UNIFORMITY CORRECTION) status of the selected camera";
CM_ SG_ 1409 CC1_ProtectiveLid "This signal indicates the PROTECTIVE LID status of the selected camera";
CM_ SG_ 1409 CC1_VideoSource_ch0 "This signal indicates the requested camera mode for channel 0, camera 1.";
CM_ SG_ 1409 CC1_TI_DDE "This signal indicates the DDE status of the selected camera";
CM_ SG_ 1409 CC1_HorizontalFlip "This signal indicates the MIRRORING status of the selected camera";
CM_ SG_ 1409 CC1_OverlayGraphics "This signal indicates the OVERLAY status of the selected camera";
CM_ SG_ 1409 CC1_VideoSource_ch1 "This signal indicates the requested camera mode for channel 1.";
CM_ SG_ 1409 CC1_TI_Polarity "This signal indicates the POLARITY (WHITE HOT or BLACK HOT) status of the selected camera";
CM_ SG_ 1409 CC1_TI_Zoom "This signal indicates the Thermal Zoom status of the selected camera.
Note: the DCAM camera has no zoom.";
CM_ SG_ 1409 CC1_TI_ROI "This signal indicates the ROI (Region of Interest) status of the selected camera.
The region of interest could have the following values:
- TOP HALF
- CENTER BLOCK
- BOTTOM HALF
- FULL SCREEN";
CM_ SG_ 1409 CC1_VideoBlending_ch0 "This signal indicates the Blending  status of the channel 0 of the selected camera.";
CM_ SG_ 1409 CC1_Reserved_03 "Reserved for future use";
CM_ SG_ 1409 CC1_TI_NUC_mode_reset_p2 "This signal is used to disable the automatic NUC.";
CM_ SG_ 1409 CC1_WindowHeaters "This signal indicates the Window heater status of the selected camera
";
CM_ SG_ 1409 CC1_Reserved_04 "Reserved for future use";
CM_ SG_ 1409 CC1_Reserved_05 "Reserved for future use";
CM_ SG_ 1409 CC1_Reserved_06 "Reserved for future use";
CM_ BO_ 1408 "Camera control message";
CM_ SG_ 1408 CC0_Reserved_02 "Reserved for future use";
CM_ SG_ 1408 CC0_DCAM_Preset "This signal indicates the selected Day Camera LUX setting for the Camera 0.";
CM_ SG_ 1408 CC0_TI_NUC_mode_reset_p1 "This signal indicates the NUC (NON UNIFORMITY CORRECTION) status of the selected camera";
CM_ SG_ 1408 CC0_ProtectiveLid "This signal indicates the PROTECTIVE LID status of the selected camera";
CM_ SG_ 1408 CC0_VideoSource_ch0 "This signal indicates the requested camera mode for channel 0, camera 0.";
CM_ SG_ 1408 CC0_TI_DDE "This signal indicates the DDE status of the selected camera";
CM_ SG_ 1408 CC0_HorizontalFlip "This signal indicates the MIRRORING status of the selected camera";
CM_ SG_ 1408 CC0_OverlayGraphics "This signal indicates the OVERLAY status of the selected camera";
CM_ SG_ 1408 CC0_VideoSource_ch1 "This signal indicates the requested camera mode.";
CM_ SG_ 1408 CC0_TI_Polarity "This signal indicates the POLARITY (WHITE HOT or BLACK HOT) status of the selected camera";
CM_ SG_ 1408 CC0_TI_Zoom "This signal indicates the Thermal Zoom status of the selected camera.
Note: the DCAM camera has no zoom.";
CM_ SG_ 1408 CC0_TI_ROI "This signal indicates the ROI (Region of Interest) status of the selected camera.
The region of interest could have the following values:
- TOP HALF
- CENTER BLOCK
- BOTTOM HALF
- FULL SCREEN";
CM_ SG_ 1408 CC0_VideoBlending_ch0 "This signal indicates the Blending  status of the channel 0 of the selected camera.";
CM_ SG_ 1408 CC0_Reserved_03 "Reserved for future use";
CM_ SG_ 1408 CC0_TI_NUC_mode_reset_p2 "This signal is used to disable the automatic NUC.";
CM_ SG_ 1408 CC0_WindowHeaters "This signal indicates the Window heater status of the selected camera
";
CM_ SG_ 1408 CC0_Reserved_04 "Reserved for future use";
CM_ SG_ 1408 CC0_Reserved_05 "Reserved for future use";
CM_ SG_ 1408 CC0_Reserved_06 "Reserved for future use";
CM_ BO_ 1407 "Camera configuration message";
CM_ SG_ 1407 SVS_GCM_Byte_0 "Should be 0xAA.";
CM_ SG_ 1407 SVS_GCM_Byte_1 "Should be 0x6B.";
CM_ SG_ 1407 SVS_GCM_Byte_2 "The PARAM field defines the parameter to configure:
0x88 Set camera to use default control message ID.
0x80 Set camera control message ID according to field CAN_HI and CAN_LOW.
For all PARAM values other than 0x80, CAN_HI and CAN_LOW
are don’t care. Note that the control message ID is not stored to non-volatile memory until a node specific control message with command 'Store control message ID' has been sent. Hence if the store command is not issued before a power reset the camera will startup and use the last stored ID.";
CM_ SG_ 1407 SVS_GCM_Byte_3 "Reserved, set to 0.";
CM_ SG_ 1407 SVS_GCM_Byte_4 "Reserved, set to 0.";
CM_ SG_ 1407 SVS_GCM_Byte_5 "Reserved, set to 0.";
CM_ SG_ 1407 SVS_GCM_Byte_6a "Reserved, set to 0.";
CM_ SG_ 1407 SVS_GCM_Byte_6b "3 most significant bits of source’s CAN message ID, should be 0x5.";
CM_ SG_ 1407 SVS_GCM_Byte_7 "8 last significant bits of source’s CAN message ID, should be in the range 0x80 to 0x87.";
CM_ SG_ 2566841884 ADB_Local_hour_offset "SPN 1602 Local hour offset
The hour component of the offset between the UTC (Universal Time Coordinate) time and date and a local time zone time
and date. This is the number of hours to add to UTC, a.k.a. GMT, time and date to convert to the time and date in the
local time zone. This parameter indicates the time reference of the data reported in the Time and Date SPNs 959, 960.
961, 962, 963, and 964. The Local Offset is a positive value for time zones East of the Prime Meridian to the International
Date Line. The Local Offset is a negative value for time zones West of the Prime Meridian to the International Date Line.
The Local Hour Offset is only applicable when the Time and Date parameters are reported as UTC time and date.
Recommended Settings:
Applications should not use the $FF 'Not Available' if using the Time and Date parameters due to some ambiguity of the
time standard for the reported time and date values. The recommended settings for the Local Hour Offset settings are:
If reporting the ";
CM_ SG_ 2566841884 ADB_Local_minute_offset "The minute component of the offset between the UTC time and date and a local time zone time and date. This is the
number of minutes to add to UTC (Universal Time Coordinate) time and date to convert to the time and date in the local
time zone . The Local Offset is a positive value for time zones East of the Prime Meridian to the International Date Line.
The Local Offset is a negative value for time zones West of the Prime Meridian to the International Date Line.
The Local Minute Offset is only applicable when the Time and Date parameters are reported as UTC time and date.
Refer to SPN 1602 for details.";
CM_ SG_ 2566841884 ADB_Year "The year component of the current calendar date. This should be reported as the year component of the current date at
UTC (Universal Time Coordinate), a.k.a. GMT; however, it may be reported as the year component of the current date at
a local time zone. The Local Hour Offset parameter (SPN 1602) is used to indicate if the calendar date (SPNs 962, 963,
and 964) is the current UTC date or a local time zone date. Refer to SPN 1602 for details.
NOTE - A value of 0 for the year identifies the year 1985; a value of 1 identifies 1986; etc.";
CM_ SG_ 2566841884 ADB_Month "The month component of the current calendar date. This should be reported as the month component of the current date
at UTC (Universal Time Coordinate), a.k.a. GMT; however, it may be reported as the month component of the current
date at a local time zone. The Local Hour Offset parameter (SPN 1602) is used to indicate if the calendar date (SPNs
962, 963, and 964) is the current UTC date or a local time zone date. Refer to SPN 1602 for details.
NOTE - A value of 0 for the month is null. The value 1 identifies January; 2 identifies February; etc.";
CM_ SG_ 2566841884 ADB_Hours "The hour component of the current time of day. This should be reported as the hour component of the current time at
UTC (Universal Time Coordinate), a.k.a. GMT; however, it may be reported as the hour component of the current time at
a local time zone. The Local Hour Offset parameter (SPN 1602) is used to indicate if time of day (SPNs 959, 960, and
961) is the current UTC time or a local time zone time. Refer to SPN 1602 for details.";
CM_ SG_ 2566841884 ADB_Minutes "The minutes component of the current time of day. This should be reported as the minutes component of the current time
at UTC (Universal Time Coordinate), a.k.a. GMT; however, it may be reported as the minutes component of the current
time at a local time zone. The Local Hour Offset parameter (SPN 1602) is used to indicate if the time of day (SPNs 959,
960, and 961) is the current UTC time or a local time zone time. Refer to SPN 1602 for details.";
CM_ SG_ 2566841884 ADB_Seconds "The seconds component of the current time of day. This should be reported as the seconds component of the current
time at UTC (Universal Time Coordinate), a.k.a. GMT; however, it may be reported as the seconds component of the
current time at a local time zone. The Local Hour Offset parameter (SPN 1602) is used to indicate if the time of day
(SPNs 959, 960, and 961) is the current UTC time or a local time zone time. Refer to SPN 1602 for details.";
CM_ BO_ 2566849955 "This PGN reports a summary of the the operating parameters of the full battery: serial number, state of charge, state of health, temperature alarm, voltage alarm for the battery.";
CM_ SG_ 2566849955 BMS3_ADB_BatSumS_serial_number "This parameter contains the manufactured serial number of the battery. The lowest 21 bits of this 24 bit serial number are also used in the J1939 NAME – see 2.1.";
CM_ SG_ 2566849955 BMS3_ADB_BatSumS_Reserved_01 "Reserved";
CM_ SG_ 2566849955 BMS3_ADB_BatSumS_State_of_Charge "This parameter contains the ratio of the remaining capacity of the battery to the full capacity expressed as a percentage.";
CM_ SG_ 2566849955 BMS3_ADB_BatSumS_State_of_Health "This parameter contains a value relating to the state of health of the battery based on defined thresholds of the ratio of full capacity to design capacity.";
CM_ SG_ 2566849955 BMS3_ADB_BatSumS_Temp_Alarm "This parameter contains the temperature alarm, based on the maximum battery temperature.
0x00: No fault;
0x01: Low Temperature Alarm
0x02: High Temperature Alarm
0x03: Wrong Temperature Alarm";
CM_ SG_ 2566849955 BMS3_ADB_BatSumS_DischargeDis "This parameter indicates when the battery is not able to be discharged.
0x00: Discharge Enable;
0x01: Discharge Disable";
CM_ SG_ 2566849955 BMS3_ADB_BatSumS_ChargingDisable "This parameter indicates when the battery is not able to be discharged.
0x00: Charging Enable;
0x01: Charging Disable";
CM_ SG_ 2566849955 BMS3_ADB_BatSumS_HeaterEnabled "This parameter indicates when the heater is enabled.
0x00: Heater Disabled;
0x01: Heater Enabled";
CM_ SG_ 2566849955 BMS3_ADB_BatSumS_BypassEnabled "This parameter indicates when the bypass is enabled.
0x00: Bypass Disabled;
0x01: Bypass Enabled";
CM_ SG_ 2566849955 BMS3_ADB_BatSumS_Voltage_Alarm "This parameter indicates an over voltage condition in one or more modules.
0x00: No fault;
0x01:Over Voltage Alarm";
CM_ SG_ 2566849955 BMS3_ADB_BatSumS_Reserved_04 "Reserved";
CM_ SG_ 2566849955 BMS3_ADB_BatSumS_Reserved_05 "Reserved";
CM_ SG_ 2566849955 BMS3_ADB_BatSumS_Reserved_06 "Reserved";
CM_ SG_ 2566849955 BMS3_ADB_BatSumS_Reserved_07 "Reserved";
CM_ SG_ 2566849955 BMS3_ADB_BatSumS_Reserved_08 "Reserved";
CM_ SG_ 2566849955 BMS3_ADB_BatSumS_Reserved_09 "Reserved";
CM_ SG_ 2566849955 BMS3_ADB_BatSumS_Reserved_10 "Reserved";
CM_ SG_ 2566849955 BMS3_ADB_BatSumS_Reserved_11 "Reserved";
CM_ BO_ 2566849699 "Used for debugging purposes.";
CM_ SG_ 2566849699 BMS3_ADB_Debug_0 "Used for debugging purpose - byte 0";
CM_ SG_ 2566849699 BMS3_ADB_Debug_1 "Used for debugging purpose - byte 1";
CM_ SG_ 2566849699 BMS3_ADB_Debug_2 "Used for debugging purpose - byte 2";
CM_ SG_ 2566849699 BMS3_ADB_Debug_3 "Used for debugging purpose - byte 3";
CM_ SG_ 2566849699 BMS3_ADB_Debug_4 "Used for debugging purpose - byte 4";
CM_ SG_ 2566849699 BMS3_ADB_Debug_5 "Used for debugging purpose - byte 5";
CM_ SG_ 2566849699 BMS3_ADB_Debug_6 "Used for debugging purpose - byte 6";
CM_ SG_ 2566849699 BMS3_ADB_Debug_7 "Used for debugging purpose - byte 7";
CM_ BO_ 2566853283 "This PGN reports the remaining module capacity, the expected full module capacity and the designed module capacity for module 3.";
CM_ SG_ 2566853283 BMS3_ADB_M1_Remaining_capacity "This parameter contains the remaining capacity of the battery.";
CM_ SG_ 2566853283 BMS3_ADB_M1_Full_capacity "This parameter contains the full capacity of the battery.";
CM_ SG_ 2566853283 BMS3_ADB_M1_Design_capacity "This parameter contains the design capacity of the battery.";
CM_ SG_ 2566853283 BMS3_ADB_M1_Reserved_Cap "Reserved";
CM_ BO_ 2566853027 "This PGN reports the remaining module capacity, the expected full module capacity and the designed module capacity for module 2.";
CM_ SG_ 2566853027 BMS3_ADB_M2_Remaining_capacity "This parameter contains the remaining capacity of the battery.";
CM_ SG_ 2566853027 BMS3_ADB_M2_Full_capacity "This parameter contains the full capacity of the battery.";
CM_ SG_ 2566853027 BMS3_ADB_M2_Design_capacity "This parameter contains the design capacity of the battery.";
CM_ SG_ 2566853027 BMS3_ADB_M2_Reserved_Cap "Reserved";
CM_ BO_ 2566852771 "This PGN reports the remaining module capacity, the expected full module capacity and the designed module capacity for module 1.";
CM_ SG_ 2566852771 BMS3_ADB_M3_Remaining_capacity "This parameter contains the remaining capacity of the battery.";
CM_ SG_ 2566852771 BMS3_ADB_M3_Full_capacity "This parameter contains the full capacity of the battery.";
CM_ SG_ 2566852771 BMS3_ADB_M3_Design_capacity "This parameter contains the design capacity of the battery.";
CM_ SG_ 2566852771 BMS3_ADB_M3_Reserved_Cap "Reserved";
CM_ BO_ 2566861987 "This PGN reports the total number of software-related events that have occurred during the life of the battery.";
CM_ SG_ 2566861987 BMS3_ADB_WatchdogReset_events "This parameter contains a count of the number times the watchdog has reset the firmware due to an internal lock-up.
Data Range: 0 – 64255. A value of 64255 indicates 64255 events or more.";
CM_ SG_ 2566861987 BMS3_ADB_StackOverflowReset_even "This parameter contains a count of the number times the firmware has been reset due to a stack-overflow.
Data Range: 0 – 64255. A value of 64255 indicates 64255 events or more.";
CM_ SG_ 2566861987 BMS3_ADB_CommandedReset_events "This parameter contains a count of the number times the firmware has been reset by a CAN, USB or status button command.
Data Range: 0 – 64255. A value of 64255 indicates 64255 events or more.";
CM_ SG_ 2566861987 BMS3_ADB_IllegalInstructionReset "This parameter contains a count of the number times the firmware has been hard-reset using the status button.
Data Range: 0 – 64255. A value of 64255 indicates 64255 events or more.";
CM_ BO_ 2566861731 "This PGN reports the total number of voltage-related events that have occurred during the life of the battery.";
CM_ SG_ 2566861731 BMS3_ADB_OverVoltage_events "This parameter contains a count of the number of times an over-voltage event has occurred.";
CM_ SG_ 2566861731 BMS3_ADB_UnderVoltage_events "This parameter contains a count of the number of times an under-voltage event has occurred.";
CM_ BO_ 2566861475 "This PGN reports the total number of current and temperature-related events that have occurred during the life of the battery.";
CM_ SG_ 2566861475 BMS3_ADB_ShortCircuit_events "This parameter contains a count of the number of times the battery has been short-circuited.";
CM_ SG_ 2566861475 BMS3_ADB_CurrentOverload_events "This parameter contains a count of the number of times the battery has been overloaded.";
CM_ SG_ 2566861475 BMS3_ADB_OverCurrent_Charge_ev "This parameter contains a count of the number of times the battery’s maximum charge current has been exceeded.";
CM_ SG_ 2566861475 BMS3_ADB_OverTemperature_ev "This parameter contains a count of the number of times the battery’s maximum temperature has been exceeded.";
CM_ BO_ 2566861219 "This PGN reports on the maximum and minimum battery voltages and currents measured during the life of the battery.";
CM_ SG_ 2566861219 BMS3_ADB_MaximumVoltage "This parameter contains the maximum voltage ever measured across the battery cells.";
CM_ SG_ 2566861219 BMS3_ADB_MinimumVoltage "This parameter contains the minimum voltage ever measured across the battery cells.";
CM_ SG_ 2566861219 BMS3_ADB_MAX_Discharge_Current "This parameter contains the maximum discharge current ever measured on the battery.";
CM_ SG_ 2566861219 BMS3_ADB_MAX_Charge_Current "This parameter contains the maximum charge current ever measured on the battery.";
CM_ BO_ 2566860963 "This PGN reports on the maximum and minimum temperatures experienced during the life of the battery.";
CM_ SG_ 2566860963 BMS3_ADB_Maximum_Life_temp "This parameter contains the maximum temperature ever measured in the battery.";
CM_ SG_ 2566860963 BMS3_ADB_Minimum_Life_temp "This parameter contains the minimum temperature ever measured in the battery.";
CM_ SG_ 2566860963 BMS3_ADB_MAX_Charging_Temp "This parameter contains the maximum temperature ever measured while charging the battery.";
CM_ SG_ 2566860963 BMS3_ADB_MIN_Charging_Temp "This parameter contains the minimum temperature ever measured while charging the battery.";
CM_ BO_ 2566857379 "This PGN reports on the individual discharge switch temperatures within module 3 of the battery. The values are only valid when the discharge current exceeds 10A for the entire battery, at other times the values returned will be the J1939 unavailable value.";
CM_ SG_ 2566857379 BMS3_ADB_M3_Temperature_1 "This parameter contains the temperature of a discharge switch sensor.";
CM_ SG_ 2566857379 BMS3_ADB_M3_Temperature_2 "This parameter contains the temperature of a discharge switch sensor.";
CM_ SG_ 2566857379 BMS3_ADB_M3_Temperature_3 "This parameter contains the temperature of a discharge switch sensor.";
CM_ SG_ 2566857379 BMS3_ADB_M3_Reserved_Dis1 "Reserved";
CM_ SG_ 2566857379 BMS3_ADB_M3_Reserved_Dis2 "Reserved";
CM_ BO_ 2566857123 "This PGN reports on the individual discharge switch temperatures within module 2 of the battery. The values are only valid when the discharge current exceeds 10A for the entire battery, at other times the values returned will be the J1939 unavailable value.";
CM_ SG_ 2566857123 BMS3_ADB_M2_Temperature_1 "This parameter contains the temperature of a discharge switch sensor.";
CM_ SG_ 2566857123 BMS3_ADB_M2_Temperature_2 "This parameter contains the temperature of a discharge switch sensor.";
CM_ SG_ 2566857123 BMS3_ADB_M2_Temperature_3 "This parameter contains the temperature of a discharge switch sensor.";
CM_ SG_ 2566857123 BMS3_ADB_M2_Reserved_Dis1 "Reserved";
CM_ SG_ 2566857123 BMS3_ADB_M2_Reserved_Dis2 "Reserved";
CM_ BO_ 2566856867 "This PGN reports on the individual discharge switch temperatures within module 1 of the battery. The values are only valid when the discharge current exceeds 10A for the entire battery, at other times the values returned will be the J1939 unavailable value.";
CM_ SG_ 2566856867 BMS3_ADB_M1_Temperature_1 "This parameter contains the temperature of a discharge switch sensor.";
CM_ SG_ 2566856867 BMS3_ADB_M1_Temperature_2 "This parameter contains the temperature of a discharge switch sensor.";
CM_ SG_ 2566856867 BMS3_ADB_M1_Temperature_3 "This parameter contains the temperature of a discharge switch sensor.";
CM_ SG_ 2566856867 BMS3_ADB_M1_Reserved_Dis1 "Reserved";
CM_ SG_ 2566856867 BMS3_ADB_M1_Reserved_Dis2 "Reserved";
CM_ BO_ 2566855331 "This PGN reports on the individual temperatures measured within module 3 of the battery.";
CM_ SG_ 2566855331 BMS3_ADB_M3_FuelGauge1_Temp "This parameter contains the temperature measured by the module’s fuel gauge IC.";
CM_ SG_ 2566855331 BMS3_ADB_M3_Thermistor1_temp "This parameter contains the temperature measured by one of the module’s Thermistors.";
CM_ SG_ 2566855331 BMS3_ADB_M3_Thermistor2_temp "This parameter contains the temperature measured by one of the module’s Thermistors.";
CM_ SG_ 2566855331 BMS3_ADB_M3_FuelGauge2_Temp "This parameter contains the temperature measured by the module’s fuel gauge IC.";
CM_ BO_ 2566855075 "This PGN reports on the individual temperatures measured within module 2 of the battery.";
CM_ SG_ 2566855075 BMS3_ADB_M2_FuelGauge1_Temp "This parameter contains the temperature measured by the module’s fuel gauge IC.";
CM_ SG_ 2566855075 BMS3_ADB_M2_Thermistor1_temp "This parameter contains the temperature measured by one of the module’s Thermistors.";
CM_ SG_ 2566855075 BMS3_ADB_M2_Thermistor2_temp "This parameter contains the temperature measured by one of the module’s Thermistors.";
CM_ SG_ 2566855075 BMS3_ADB_M2_FuelGauge2_Temp "This parameter contains the temperature measured by the module’s fuel gauge IC.";
CM_ BO_ 2566854819 "This PGN reports on the individual temperatures measured within module 1 of the battery.";
CM_ SG_ 2566854819 BMS3_ADB_M1_FuelGauge1_Temp "This parameter contains the temperature measured by the module’s fuel gauge IC.";
CM_ SG_ 2566854819 BMS3_ADB_M1_Thermistor1_temp "This parameter contains the temperature measured by one of the module’s Thermistors.";
CM_ SG_ 2566854819 BMS3_ADB_M1_Thermistor2_temp "This parameter contains the temperature measured by one of the module’s Thermistors.";
CM_ SG_ 2566854819 BMS3_ADB_M1_FuelGauge2_Temp "This parameter contains the temperature measured by the module’s fuel gauge IC.";
CM_ BO_ 2566851235 "This PGN reports the operating parameters of module 3 within the battery: output voltage, average current (charge or discharge), the percentage state of charge, a state of health indication and the protection status of the module.";
CM_ SG_ 2566851235 BMS3_ADB_M3_Module_OUT_Voltage "This parameter contains the output voltage of the module.";
CM_ SG_ 2566851235 BMS3_ADB_M3_ModuleAverageCurrent "This parameter contains the charge (positive) or discharge (negative) current of the module averaged over 1 second.";
CM_ SG_ 2566851235 BMS3_ADB_M3_Module_StateOfCharge "This parameter contains the ratio of the remaining capacity of the module to the full capacity of the module expressed as a percentage.";
CM_ SG_ 2566851235 BMS3_ADB_M3_Module_StateOfHealth "This parameter contains a value relating to the state of health of the module based on defined thresholds of the ratio of full capacity to design capacity.";
CM_ SG_ 2566851235 BMS3_ADB_M3_DiscProtectTrigg "This parameter contains the current protection status of the module.
Discharge protection triggered";
CM_ SG_ 2566851235 BMS3_ADB_M3_ChargeProtectTrigg "This parameter contains the current protection status of the module.
Charge protection triggered";
CM_ SG_ 2566851235 BMS3_ADB_M3_ModulesMissingFailed "This parameter contains the current protection status of the module.
Modules missing/failed";
CM_ SG_ 2566851235 BMS3_ADB_M3_OverTemp_detect "This parameter contains the current protection status of the module.
Over-temperature detected";
CM_ SG_ 2566851235 BMS3_ADB_M3_UnderVoltage_detect "This parameter contains the current protection status of the module.
Under-voltage detected";
CM_ SG_ 2566851235 BMS3_ADB_M3_OverVoltage_detected "This parameter contains the current protection status of the module.
Over-voltage detected";
CM_ SG_ 2566851235 BMS3_ADB_M3_Overload_detected "This parameter contains the current protection status of the module.
Overload detected";
CM_ SG_ 2566851235 BMS3_ADB_M3_ShortCircuit_detect "This parameter contains the current protection status of the module.
Short circuit detected";
CM_ SG_ 2566851235 BMS3_ADB_M3_Module_BQ78350 "This parameter contains selected data from the BQ78350 status.
Each bit indicates a different alarm (bit 1 indicates extra 1, bit 2 indicates extra 2 …) where 0 indicates no fault and 1 indicates missing, failed or protection triggered";
CM_ BO_ 2566850979 "This PGN reports the operating parameters of module 2 within the battery: output voltage, average current (charge or discharge), the percentage state of charge, a state of health indication and the protection status of the module.";
CM_ SG_ 2566850979 BMS3_ADB_M2_Module_OUT_Voltage "This parameter contains the output voltage of the module.";
CM_ SG_ 2566850979 BMS3_ADB_M2_ModuleAverageCurrent "This parameter contains the charge (positive) or discharge (negative) current of the module averaged over 1 second.";
CM_ SG_ 2566850979 BMS3_ADB_M2_Module_StateOfCharge "This parameter contains the ratio of the remaining capacity of the module to the full capacity of the module expressed as a percentage.";
CM_ SG_ 2566850979 BMS3_ADB_M2_Module_StateOfHealth "This parameter contains a value relating to the state of health of the module based on defined thresholds of the ratio of full capacity to design capacity.";
CM_ SG_ 2566850979 BMS3_ADB_M2_DiscProtectTrigg "This parameter contains the current protection status of the module.
Discharge protection triggered";
CM_ SG_ 2566850979 BMS3_ADB_M2_ChargeProtectTrigg "This parameter contains the current protection status of the module.
Charge protection triggered";
CM_ SG_ 2566850979 BMS3_ADB_M2_ModulesMissingFailed "This parameter contains the current protection status of the module.
Modules missing/failed";
CM_ SG_ 2566850979 BMS3_ADB_M2_OverTemp_detect "This parameter contains the current protection status of the module.
Over-temperature detected";
CM_ SG_ 2566850979 BMS3_ADB_M2_UnderVoltage_detect "This parameter contains the current protection status of the module.
Under-voltage detected";
CM_ SG_ 2566850979 BMS3_ADB_M2_OverVoltage_detected "This parameter contains the current protection status of the module.
Over-voltage detected";
CM_ SG_ 2566850979 BMS3_ADB_M2_Overload_detected "This parameter contains the current protection status of the module.
Overload detected";
CM_ SG_ 2566850979 BMS3_ADB_M2_ShortCircuit_detect "This parameter contains the current protection status of the module.
Short circuit detected";
CM_ SG_ 2566850979 BMS3_ADB_M2_Module_BQ78350 "This parameter contains selected data from the BQ78350 status.
Each bit indicates a different alarm (bit 1 indicates extra 1, bit 2 indicates extra 2 …) where 0 indicates no fault and 1 indicates missing, failed or protection triggered";
CM_ BO_ 2566850723 "This PGN reports the operating parameters of module 1 within the battery: output voltage, average current (charge or discharge), the percentage state of charge, a state of health indication and the protection status of the module.";
CM_ SG_ 2566850723 BMS3_ADB_M1_Module_OUT_Voltage "This parameter contains the output voltage of the module.";
CM_ SG_ 2566850723 BMS3_ADB_M1_ModuleAverageCurrent "This parameter contains the charge (positive) or discharge (negative) current of the module averaged over 1 second.";
CM_ SG_ 2566850723 BMS3_ADB_M1_Module_StateOfCharge "This parameter contains the ratio of the remaining capacity of the module to the full capacity of the module expressed as a percentage.";
CM_ SG_ 2566850723 BMS3_ADB_M1_Module_StateOfHealth "This parameter contains a value relating to the state of health of the module based on defined thresholds of the ratio of full capacity to design capacity.";
CM_ SG_ 2566850723 BMS3_ADB_M1_DiscProtectTrigg "This parameter contains the current protection status of the module.
Discharge protection triggered";
CM_ SG_ 2566850723 BMS3_ADB_M1_ChargeProtectTrigg "This parameter contains the current protection status of the module.
Charge protection triggered";
CM_ SG_ 2566850723 BMS3_ADB_M1_ModulesMissingFailed "This parameter contains the current protection status of the module.
Modules missing/failed";
CM_ SG_ 2566850723 BMS3_ADB_M1_OverTemp_detect "This parameter contains the current protection status of the module.
Over-temperature detected";
CM_ SG_ 2566850723 BMS3_ADB_M1_UnderVoltage_detect "This parameter contains the current protection status of the module.
Under-voltage detected";
CM_ SG_ 2566850723 BMS3_ADB_M1_OverVoltage_detected "This parameter contains the current protection status of the module.
Over-voltage detected";
CM_ SG_ 2566850723 BMS3_ADB_M1_Overload_detected "This parameter contains the current protection status of the module.
Overload detected";
CM_ SG_ 2566850723 BMS3_ADB_M1_ShortCircuit_detect "This parameter contains the current protection status of the module.
Short circuit detected";
CM_ SG_ 2566850723 BMS3_ADB_M1_Module_BQ78350 "This parameter contains selected data from the BQ78350 status.
Each bit indicates a different alarm (bit 1 indicates extra 1, bit 2 indicates extra 2 …) where 0 indicates no fault and 1 indicates missing, failed or protection triggered";
CM_ BO_ 2566849443 "This PGN reports the battery’s serial and firmware version numbers.";
CM_ SG_ 2566849443 BMS3_ADB_Battery_serial_number "This parameter contains the manufactured serial number of the battery. The lowest 21 bits of this 24 bit serial number are also used in the J1939 NAME – see 2.1.";
CM_ SG_ 2566849443 BMS3_ADB_FirmwareVersionMajor "This parameter contains the major number of the firmware version, i.e. where the firmware has a version XX.YY.ZZZ it represents XX.";
CM_ SG_ 2566849443 BMS3_ADB_FirmwareVersionMinor "This parameter contains the major number of the firmware version, i.e. where the firmware has a version XX.YY.ZZZ it represents YY.";
CM_ SG_ 2566849443 BMS3_ADB_Firmware_Revision "This parameter contains the major number of the firmware version, i.e. where the firmware has a version XX.YY.ZZZ it represents ZZZ.";
CM_ BO_ 2566849187 "This PGN reports the battery temperature. The battery contains a number of temperature sensors which are summarised in this PGN by reporting the maximum, the minimum and the average of all the sensors.";
CM_ SG_ 2566849187 BMS3_ADB_Maximum_Temperature "This parameter contains the highest temperature currently measured within the battery.";
CM_ SG_ 2566849187 BMS3_ADB_Minimum_Temperature "This parameter contains the lowest temperature currently measured within the battery.";
CM_ SG_ 2566849187 BMS3_ADB_Average_Temperature "This parameter contains the average of all the temperatures currently measured within the battery.";
CM_ BO_ 2566848931 "This PGN reports the remaining battery capacity, the expected full battery capacity and the designed battery capacity. If the capacity falls below a defined percentage of the design capacity, the battery enters an alarm state and broadcasts this PGN within 100ms of the event and then repeatedly at 1000ms intervals until the capacity moves above the alarm threshold.";
CM_ SG_ 2566848931 BMS3_ADB_Remaining_capacity "This parameter contains the remaining capacity of the battery.";
CM_ SG_ 2566848931 BMS3_ADB_Full_capacity "This parameter contains the full capacity of the battery.";
CM_ SG_ 2566848931 BMS3_ADB_Design_capacity "This parameter contains the design capacity of the battery.";
CM_ SG_ 2566848931 BMS3_ADB_Overall_10_alarm "This parameter contains fields indicating which, if any, capacity alarm thresholds have been triggered.
Overall – less than 10% of design capacity remaining";
CM_ SG_ 2566848931 BMS3_ADB_Silent_Watch_20_alarm "This parameter contains fields indicating which, if any, capacity alarm thresholds have been triggered.
Silent watch – less than 20% silent watch threshold";
CM_ SG_ 2566848931 BMS3_ADB_EngStartCapacity_alarm "This parameter contains fields indicating which, if any, capacity alarm thresholds have been triggered.
Engine start – capacity below engine start threshold";
CM_ SG_ 2566848931 BMS3_ADB_10_Reserved_4 "Not used";
CM_ SG_ 2566848931 BMS3_ADB_10_Reserved_5 "Not used";
CM_ SG_ 2566848931 BMS3_ADB_10_Reserved_6 "Not used";
CM_ SG_ 2566848931 BMS3_ADB_10_Reserved_7 "Not used";
CM_ SG_ 2566848931 BMS3_ADB_10_Reserved_8 "Not used";
CM_ BO_ 2566848675 "This PGN reports the normal operating parameters of the battery: output voltage, average current (charge or discharge), the percentage state of charge and a state of health indication.
The PGN is broadcast at 1000ms intervals or can be requested.";
CM_ SG_ 2566848675 BMS3_ADB_Batt_OUT_Voltage "This parameter contains the output voltage of the battery.
It only specifies the voltage of the internal modules that are available for discharge: any module which is in over-temperature or under-voltage protection is not included in this figure because it has been internally disconnected.";
CM_ SG_ 2566848675 BMS3_ADB_Batt_Average_Current "This parameter contains the charge (positive) or discharge (negative) current of the battery averaged over 1 second.";
CM_ SG_ 2566848675 BMS3_ADB_Batt_StsOfCharge "This parameter contains the ratio of the remaining capacity of the battery to the full capacity expressed as a percentage.";
CM_ SG_ 2566848675 BMS3_ADB_Batt_StsOfHealth "This parameter contains a value relating to the state of health of the battery based on defined thresholds of the ratio of full capacity to design capacity.";
CM_ SG_ 2566848675 BMS3_ADB_Batt_PS8_discharge_prot "This parameter contains the current protection status of the battery.
Discharge protection triggered.";
CM_ SG_ 2566848675 BMS3_ADB_Batt_PS7_charge_prot "This parameter contains the current protection status of the battery.
Charge protection triggered.";
CM_ SG_ 2566848675 BMS3_ADB_Batt_PS6_mod_failed "This parameter contains the current protection status of the battery.
1 or more modules missing/failed.";
CM_ SG_ 2566848675 BMS3_ADB_Batt_PS5_over_temp "This parameter contains the current protection status of the battery.
Over-temperature detected.";
CM_ SG_ 2566848675 BMS3_ADB_Batt_PS4_under_voltage "This parameter contains the current protection status of the battery.
Under-voltage detected.";
CM_ SG_ 2566848675 BMS3_ADB_Batt_PS3_over_voltage "This parameter contains the current protection status of the battery.
Over-voltage detected.";
CM_ SG_ 2566848675 BMS3_ADB_Batt_PS2_overload "This parameter contains the current protection status of the battery.
Overload detected.";
CM_ SG_ 2566848675 BMS3_ADB_Batt_PS1_short_circuit "This parameter contains the current protection status of the battery.
Short circuit detected.";
CM_ SG_ 2566848675 BMS3_ADB_Batt_OS_8_sleep_mode "This parameter contains the status bits indicating the current state of the emergency load-dump, emergency override, heater and charger controls along with the master protection status bit.
Sleep mode pending (1 = sleep pending, 0 = awake)";
CM_ SG_ 2566848675 BMS3_ADB_Batt_OS_7_emerg_used "This parameter contains the status bits indicating the current state of the emergency load-dump, emergency override, heater and charger controls along with the master protection status bit.
Emergency override used (1= used, 0 = never used)";
CM_ SG_ 2566848675 BMS3_ADB_Batt_OS_6_emergency "This parameter contains the status bits indicating the current state of the emergency load-dump, emergency override, heater and charger controls along with the master protection status bit.
Emergency override (1 = active, 0 = inactive)";
CM_ SG_ 2566848675 BMS3_ADB_Batt_OS_45_charge_level "This parameter contains the status bits indicating the current state of the emergency load-dump, emergency override, heater and charger controls along with the master protection status bit.
Charge level (0 = off, 1 = 25%, 2 = 50%, 3 = full)";
CM_ SG_ 2566848675 BMS3_ADB_Batt_OS_3_charge_cont "This parameter contains the status bits indicating the current state of the emergency load-dump, emergency override, heater and charger controls along with the master protection status bit.
Charge control (1 = on, 0 = off)";
CM_ SG_ 2566848675 BMS3_ADB_Batt_OS_2_heater_cont "This parameter contains the status bits indicating the current state of the emergency load-dump, emergency override, heater and charger controls along with the master protection status bit.
Heater control (1 = on, 0 = off)";
CM_ SG_ 2566848675 BMS3_ADB_Batt_OS_1_master_prot "This parameter contains the status bits indicating the current state of the emergency load-dump, emergency override, heater and charger controls along with the master protection status bit.
Master protect (1 = protect, 0 = off)";
CM_ BO_ 2566804131 "This contains high resolution/range parameters reported from the alternator or power generation components.";
CM_ SG_ 2566804131 _nu_BMS3_ADB_AlternatorCurrent "SPN 1795 Alternator Current (High Range/Resolution)
This parameter indicates the amount of electrical current output from the alternator of the main vehicle. Alternator Current
(SPN 115) has a lower range and resolution.";
CM_ SG_ 2566804131 BMS3_ADB_NetBattery_Current "SPN 2579 Net Battery Current (High Range/Resolution)
Net flow of electrical current into/out-of the battery or batteries. This parameter is the high range and resolution of SPN
114 - Net Battery Current.";
CM_ BO_ 2566803619 "Contains battery temperature information.";
CM_ SG_ 2566803619 BMS3_ADB_Battery1_Temperature "Temperature of the battery 1. The relation to physical location is determined by the equipment manufacturer.";
CM_ SG_ 2566803619 _nu_BMS3_ADB_Battery2_Temp "Temperature of the battery 2. The relation to physical location is determined by the equipment manufacturer.";
BA_DEF_  "ProtocolType" STRING ;
BA_DEF_  "BusType" STRING ;
BA_DEF_  "DBName" STRING ;
BA_DEF_  "DatabaseVersion" STRING ;
BA_DEF_ BO_  "GenMsgCycleTimeFast" INT 0 3600000;
BA_DEF_ BO_  "GenMsgDelayTime" INT 0 3600000;
BA_DEF_ BO_  "GenMsgStartDelayTime" INT 0 10000;
BA_DEF_ BO_  "GenMsgSendType" ENUM  "cyclic","reserved","cyclicIfActive","reserved","reserved","reserved","reserved","reserved","noMsgSendType";
BA_DEF_ BO_  "GenMsgCycleTime" INT 0 3600000;
BA_DEF_ BO_  "GenMsgILSupport" ENUM  "No","Yes";
BA_DEF_ BO_  "VFrameFormat" ENUM  "StandardCAN","ExtendedCAN","reserved","J1939PG";
BA_DEF_ BO_  "GenMsgSendTypex" ENUM  "cyclic","reserved","cyclicIfActive","reserved","reserved","reserved","reserved","reserved","noMsgSendType";
BA_DEF_ BO_  "GenMsgRequestable" INT 0 1;
BA_DEF_ BO_  "GenMsgSencmype" ENUM  "cyclic","reserved","cyclicIfActive","reserved","reserved","reserved","reserved","reserved","noMsgSencmype";
BA_DEF_ BO_  "GenMsgSencmypex" ENUM  "cyclic","reserved","cyclicIfActive","reserved","reserved","reserved","reserved","reserved","noMsgSencmype";
BA_DEF_ BU_  "NmStationAddress" INT 0 255;
BA_DEF_ BU_  "ILUsed" ENUM  "Yes","No";
BA_DEF_ BU_  "NodeLayerModules" STRING ;
BA_DEF_ SG_  "GenSigSendType" ENUM  "Cyclic","OnWrite","reserved","OnChange","reserved","reserved","reserved","NoSigSendType";
BA_DEF_ SG_  "GenSigStartValue" INT 0 10000;
BA_DEF_ SG_  "GenSigEVName" STRING ;
BA_DEF_ SG_  "GenSigILSupport" ENUM  "Yes","No";
BA_DEF_ SG_  "GenSigSendTypex" ENUM  "Cyclic","OnWrite","reserved","OnChange","reserved","reserved","reserved","NoSigSendType";
BA_DEF_ SG_  "GenSigSencmype" ENUM  "Cyclic","OnWrite","reserved","OnChange","reserved","reserved","reserved","NoSigSencmype";
BA_DEF_ SG_  "GenSigSencmypex" ENUM  "Cyclic","OnWrite","reserved","OnChange","reserved","reserved","reserved","NoSigSencmype";
BA_DEF_ SG_  "SigType" ENUM  "Default","Range","RangeSigned","ASCII","Discrete","Control","ReferencePGN","DTC","StringDelimiter","StringLength","StringLengthControl";
BA_DEF_DEF_  "ProtocolType" "J1939";
BA_DEF_DEF_  "BusType" "CAN";
BA_DEF_DEF_  "DBName" "";
BA_DEF_DEF_  "DatabaseVersion" "";
BA_DEF_DEF_  "GenMsgCycleTimeFast" 0;
BA_DEF_DEF_  "GenMsgDelayTime" 0;
BA_DEF_DEF_  "GenMsgStartDelayTime" 0;
BA_DEF_DEF_  "GenMsgSendType" "noMsgSendType";
BA_DEF_DEF_  "GenMsgCycleTime" 0;
BA_DEF_DEF_  "GenMsgILSupport" "Yes";
BA_DEF_DEF_  "VFrameFormat" "J1939PG";
BA_DEF_DEF_  "GenMsgSendTypex" "noMsgSendType";
BA_DEF_DEF_  "GenMsgRequestable" 1;
BA_DEF_DEF_  "GenMsgSencmype" "noMsgSencmype";
BA_DEF_DEF_  "GenMsgSencmypex" "noMsgSencmype";
BA_DEF_DEF_  "NmStationAddress" 254;
BA_DEF_DEF_  "ILUsed" "Yes";
BA_DEF_DEF_  "NodeLayerModules" "CANoeILNLVector.dll";
BA_DEF_DEF_  "GenSigSendType" "NoSigSendType";
BA_DEF_DEF_  "GenSigStartValue" 0;
BA_DEF_DEF_  "GenSigEVName" "Env@Nodename_@Signame";
BA_DEF_DEF_  "GenSigILSupport" "Yes";
BA_DEF_DEF_  "GenSigSendTypex" "NoSigSendType";
BA_DEF_DEF_  "GenSigSencmype" "NoSigSencmype";
BA_DEF_DEF_  "GenSigSencmypex" "NoSigSencmype";
BA_DEF_DEF_  "SigType" "Default";
BA_ "DatabaseVersion" "5";
BA_ "DBName" "C2_ADB";
BA_ "NmStationAddress" BU_ CAMERA_ALL 191;
BA_ "NmStationAddress" BU_ ALM_DX 146;
BA_ "NmStationAddress" BU_ ALM_SX 145;
BA_ "NmStationAddress" BU_ CAMERA_DEFAULT 184;
BA_ "NmStationAddress" BU_ LOGBOX 28;
BA_ "NmStationAddress" BU_ CAMERA_POS0 176;
BA_ "NmStationAddress" BU_ CAMERA_POS1 177;
BA_ "NmStationAddress" BU_ CAMERA_POS2 178;
BA_ "NmStationAddress" BU_ CAMERA_POS3 179;
BA_ "NmStationAddress" BU_ CAMERA_POS4 180;
BA_ "NmStationAddress" BU_ CAMERA_POS5 181;
BA_ "NmStationAddress" BU_ CAMERA_POS6 182;
BA_ "NmStationAddress" BU_ CAMERA_POS7 183;
BA_ "NmStationAddress" BU_ SVS 84;
BA_ "NmStationAddress" BU_ RUR 140;
BA_ "NmStationAddress" BU_ RUF 137;
BA_ "NmStationAddress" BU_ RUC 138;
BA_ "NmStationAddress" BU_ BC 33;
BA_ "NmStationAddress" BU_ _TESTER 29;
BA_ "NmStationAddress" BU_ BMS3_ADB 163;
BA_ "NmStationAddress" BU_ BMS4_ADB 164;
BA_ "NmStationAddress" BU_ BMS5_ADB 165;
BA_ "NmStationAddress" BU_ BMS6_ADB 166;
BA_ "GenMsgSendType" BO_ 2550202258 0;
BA_ "GenMsgCycleTime" BO_ 2550202258 1000;
BA_ "GenMsgSendType" BO_ 2550202257 0;
BA_ "GenMsgCycleTime" BO_ 2550202257 1000;
BA_ "GenMsgCycleTime" BO_ 2550210900 1000;
BA_ "GenMsgSendType" BO_ 2559071265 0;
BA_ "GenMsgCycleTime" BO_ 2559071265 500;
BA_ "GenMsgSendType" BO_ 2559005729 0;
BA_ "GenMsgCycleTime" BO_ 2559005729 500;
BA_ "GenMsgSendType" BO_ 2558940193 0;
BA_ "GenMsgCycleTime" BO_ 2558940193 500;
BA_ "GenMsgCycleTime" BO_ 2550145364 1000;
BA_ "VFrameFormat" BO_ 2015 0;
BA_ "VFrameFormat" BO_ 1416 0;
BA_ "VFrameFormat" BO_ 1415 0;
BA_ "VFrameFormat" BO_ 1414 0;
BA_ "VFrameFormat" BO_ 1413 0;
BA_ "VFrameFormat" BO_ 1412 0;
BA_ "VFrameFormat" BO_ 1411 0;
BA_ "VFrameFormat" BO_ 1410 0;
BA_ "VFrameFormat" BO_ 1409 0;
BA_ "VFrameFormat" BO_ 1408 0;
BA_ "VFrameFormat" BO_ 1407 0;
BA_ "GenMsgCycleTime" BO_ 2566841884 100;
BA_ "GenSigStartValue" SG_ 2550223905 BC_GCM_Byte_0 170;
BA_ "GenSigStartValue" SG_ 2550223905 BC_GCM_Byte_1 107;
BA_ "GenSigStartValue" SG_ 2550223905 BC_GCM_Byte_2 136;
BA_ "GenSigStartValue" SG_ 2550223905 BC_GCM_Byte_6b 5;
BA_ "GenSigStartValue" SG_ 2550223905 BC_GCM_Byte_7 135;
BA_ "GenSigStartValue" SG_ 2559071265 TypeOfVideoSignal_Output 1;
BA_ "GenSigStartValue" SG_ 2550158369 CCBC_DCAM_Preset 1;
BA_ "GenSigStartValue" SG_ 2550158369 CCBC_TI_NUC_mode_reset_p1 1;
BA_ "GenSigStartValue" SG_ 2550158369 CCBC_ProtectiveLid 2;
BA_ "GenSigStartValue" SG_ 2550158369 CCBC_VideoSource_ch0 2;
BA_ "GenSigStartValue" SG_ 2550158369 CCBC_TI_DDE 1;
BA_ "GenSigStartValue" SG_ 2550158369 CCBC_HorizontalFlip 2;
BA_ "GenSigStartValue" SG_ 2550158369 CCBC_OverlayGraphics 1;
BA_ "GenSigStartValue" SG_ 2550158369 CCBC_TI_Polarity 1;
BA_ "GenSigStartValue" SG_ 2550158369 CCBC_TI_Zoom 1;
BA_ "GenSigStartValue" SG_ 2550158369 CCBC_TI_ROI 1;
BA_ "GenSigStartValue" SG_ 2550158369 CCBC_VideoBlending_ch0 1;
BA_ "GenSigStartValue" SG_ 2015 IM_TI_Zoom 1;
BA_ "GenSigStartValue" SG_ 1416 CCD_DCAM_Preset 1;
BA_ "GenSigStartValue" SG_ 1416 CCD_TI_NUC_mode_reset_p1 1;
BA_ "GenSigStartValue" SG_ 1416 CCD_ProtectiveLid 2;
BA_ "GenSigStartValue" SG_ 1416 CCD_VideoSource_ch0 2;
BA_ "GenSigStartValue" SG_ 1416 CCD_TI_DDE 1;
BA_ "GenSigStartValue" SG_ 1416 CCD_HorizontalFlip 2;
BA_ "GenSigStartValue" SG_ 1416 CCD_OverlayGraphics 1;
BA_ "GenSigStartValue" SG_ 1416 CCD_TI_Polarity 1;
BA_ "GenSigStartValue" SG_ 1416 CCD_TI_Zoom 1;
BA_ "GenSigStartValue" SG_ 1416 CCD_TI_ROI 1;
BA_ "GenSigStartValue" SG_ 1416 CCD_VideoBlending_ch0 1;
BA_ "GenSigStartValue" SG_ 1415 CC7_DCAM_Preset 1;
BA_ "GenSigStartValue" SG_ 1415 CC7_TI_NUC_mode_reset_p1 1;
BA_ "GenSigStartValue" SG_ 1415 CC7_ProtectiveLid 2;
BA_ "GenSigStartValue" SG_ 1415 CC7_VideoSource_ch0 2;
BA_ "GenSigStartValue" SG_ 1415 CC7_TI_DDE 1;
BA_ "GenSigStartValue" SG_ 1415 CC7_HorizontalFlip 2;
BA_ "GenSigStartValue" SG_ 1415 CC7_OverlayGraphics 1;
BA_ "GenSigStartValue" SG_ 1415 CC7_TI_Polarity 1;
BA_ "GenSigStartValue" SG_ 1415 CC7_TI_Zoom 1;
BA_ "GenSigStartValue" SG_ 1415 CC7_TI_ROI 1;
BA_ "GenSigStartValue" SG_ 1415 CC7_VideoBlending_ch0 1;
BA_ "GenSigStartValue" SG_ 1414 CC6_DCAM_Preset 1;
BA_ "GenSigStartValue" SG_ 1414 CC6_TI_NUC_mode_reset_p1 1;
BA_ "GenSigStartValue" SG_ 1414 CC6_ProtectiveLid 2;
BA_ "GenSigStartValue" SG_ 1414 CC6_VideoSource_ch0 2;
BA_ "GenSigStartValue" SG_ 1414 CC6_TI_DDE 1;
BA_ "GenSigStartValue" SG_ 1414 CC6_HorizontalFlip 2;
BA_ "GenSigStartValue" SG_ 1414 CC6_OverlayGraphics 1;
BA_ "GenSigStartValue" SG_ 1414 CC6_TI_Polarity 1;
BA_ "GenSigStartValue" SG_ 1414 CC6_TI_Zoom 1;
BA_ "GenSigStartValue" SG_ 1414 CC6_TI_ROI 1;
BA_ "GenSigStartValue" SG_ 1414 CC6_VideoBlending_ch0 1;
BA_ "GenSigStartValue" SG_ 1413 CC5_DCAM_Preset 1;
BA_ "GenSigStartValue" SG_ 1413 CC5_TI_NUC_mode_reset_p1 1;
BA_ "GenSigStartValue" SG_ 1413 CC5_ProtectiveLid 2;
BA_ "GenSigStartValue" SG_ 1413 CC5_VideoSource_ch0 2;
BA_ "GenSigStartValue" SG_ 1413 CC5_TI_DDE 1;
BA_ "GenSigStartValue" SG_ 1413 CC5_HorizontalFlip 2;
BA_ "GenSigStartValue" SG_ 1413 CC5_OverlayGraphics 1;
BA_ "GenSigStartValue" SG_ 1413 CC5_TI_Polarity 1;
BA_ "GenSigStartValue" SG_ 1413 CC5_TI_Zoom 1;
BA_ "GenSigStartValue" SG_ 1413 CC5_TI_ROI 1;
BA_ "GenSigStartValue" SG_ 1413 CC5_VideoBlending_ch0 1;
BA_ "GenSigStartValue" SG_ 1412 CC4_DCAM_Preset 1;
BA_ "GenSigStartValue" SG_ 1412 CC4_TI_NUC_mode_reset_p1 1;
BA_ "GenSigStartValue" SG_ 1412 CC4_ProtectiveLid 2;
BA_ "GenSigStartValue" SG_ 1412 CC4_VideoSource_ch0 2;
BA_ "GenSigStartValue" SG_ 1412 CC4_TI_DDE 1;
BA_ "GenSigStartValue" SG_ 1412 CC4_HorizontalFlip 2;
BA_ "GenSigStartValue" SG_ 1412 CC4_OverlayGraphics 1;
BA_ "GenSigStartValue" SG_ 1412 CC4_TI_Polarity 1;
BA_ "GenSigStartValue" SG_ 1412 CC4_TI_Zoom 1;
BA_ "GenSigStartValue" SG_ 1412 CC4_TI_ROI 1;
BA_ "GenSigStartValue" SG_ 1412 CC4_VideoBlending_ch0 1;
BA_ "GenSigStartValue" SG_ 1411 CC3_DCAM_Preset 1;
BA_ "GenSigStartValue" SG_ 1411 CC3_TI_NUC_mode_reset_p1 1;
BA_ "GenSigStartValue" SG_ 1411 CC3_ProtectiveLid 2;
BA_ "GenSigStartValue" SG_ 1411 CC3_VideoSource_ch0 2;
BA_ "GenSigStartValue" SG_ 1411 CC3_TI_DDE 1;
BA_ "GenSigStartValue" SG_ 1411 CC3_HorizontalFlip 2;
BA_ "GenSigStartValue" SG_ 1411 CC3_OverlayGraphics 1;
BA_ "GenSigStartValue" SG_ 1411 CC3_TI_Polarity 1;
BA_ "GenSigStartValue" SG_ 1411 CC3_TI_Zoom 1;
BA_ "GenSigStartValue" SG_ 1411 CC3_TI_ROI 1;
BA_ "GenSigStartValue" SG_ 1411 CC3_VideoBlending_ch0 1;
BA_ "GenSigStartValue" SG_ 1410 CC2_DCAM_Preset 1;
BA_ "GenSigStartValue" SG_ 1410 CC2_TI_NUC_mode_reset_p1 1;
BA_ "GenSigStartValue" SG_ 1410 CC2_ProtectiveLid 2;
BA_ "GenSigStartValue" SG_ 1410 CC2_VideoSource_ch0 2;
BA_ "GenSigStartValue" SG_ 1410 CC2_TI_DDE 1;
BA_ "GenSigStartValue" SG_ 1410 CC2_HorizontalFlip 2;
BA_ "GenSigStartValue" SG_ 1410 CC2_OverlayGraphics 1;
BA_ "GenSigStartValue" SG_ 1410 CC2_TI_Polarity 1;
BA_ "GenSigStartValue" SG_ 1410 CC2_TI_Zoom 1;
BA_ "GenSigStartValue" SG_ 1410 CC2_TI_ROI 1;
BA_ "GenSigStartValue" SG_ 1410 CC2_VideoBlending_ch0 1;
BA_ "GenSigStartValue" SG_ 1409 CC1_DCAM_Preset 1;
BA_ "GenSigStartValue" SG_ 1409 CC1_TI_NUC_mode_reset_p1 1;
BA_ "GenSigStartValue" SG_ 1409 CC1_ProtectiveLid 2;
BA_ "GenSigStartValue" SG_ 1409 CC1_VideoSource_ch0 2;
BA_ "GenSigStartValue" SG_ 1409 CC1_TI_DDE 1;
BA_ "GenSigStartValue" SG_ 1409 CC1_HorizontalFlip 2;
BA_ "GenSigStartValue" SG_ 1409 CC1_OverlayGraphics 1;
BA_ "GenSigStartValue" SG_ 1409 CC1_TI_Polarity 1;
BA_ "GenSigStartValue" SG_ 1409 CC1_TI_Zoom 1;
BA_ "GenSigStartValue" SG_ 1409 CC1_TI_ROI 1;
BA_ "GenSigStartValue" SG_ 1409 CC1_VideoBlending_ch0 1;
BA_ "GenSigStartValue" SG_ 1408 CC0_DCAM_Preset 1;
BA_ "GenSigStartValue" SG_ 1408 CC0_TI_NUC_mode_reset_p1 1;
BA_ "GenSigStartValue" SG_ 1408 CC0_ProtectiveLid 2;
BA_ "GenSigStartValue" SG_ 1408 CC0_VideoSource_ch0 2;
BA_ "GenSigStartValue" SG_ 1408 CC0_TI_DDE 1;
BA_ "GenSigStartValue" SG_ 1408 CC0_HorizontalFlip 2;
BA_ "GenSigStartValue" SG_ 1408 CC0_OverlayGraphics 1;
BA_ "GenSigStartValue" SG_ 1408 CC0_TI_Polarity 1;
BA_ "GenSigStartValue" SG_ 1408 CC0_TI_Zoom 1;
BA_ "GenSigStartValue" SG_ 1408 CC0_TI_ROI 1;
BA_ "GenSigStartValue" SG_ 1408 CC0_VideoBlending_ch0 1;
BA_ "GenSigStartValue" SG_ 1407 SVS_GCM_Byte_0 170;
BA_ "GenSigStartValue" SG_ 1407 SVS_GCM_Byte_1 107;
BA_ "GenSigStartValue" SG_ 1407 SVS_GCM_Byte_2 136;
BA_ "GenSigStartValue" SG_ 1407 SVS_GCM_Byte_6b 5;
BA_ "GenSigStartValue" SG_ 1407 SVS_GCM_Byte_7 135;
BA_ "GenSigStartValue" SG_ 2566841884 ADB_Local_hour_offset 125;
BA_ "GenSigStartValue" SG_ 2566841884 ADB_Local_minute_offset 125;
BA_ "GenSigStartValue" SG_ 2566841884 ADB_Month 1;
BA_ "GenSigStartValue" SG_ 2566853283 BMS3_ADB_M1_Reserved_Cap 255;
BA_ "GenSigStartValue" SG_ 2566853027 BMS3_ADB_M2_Reserved_Cap 255;
BA_ "GenSigStartValue" SG_ 2566852771 BMS3_ADB_M3_Reserved_Cap 255;
BA_ "GenSigStartValue" SG_ 2566860963 BMS3_ADB_Maximum_Life_temp 1000;
BA_ "GenSigStartValue" SG_ 2566860963 BMS3_ADB_Minimum_Life_temp 1000;
BA_ "GenSigStartValue" SG_ 2566860963 BMS3_ADB_MAX_Charging_Temp 1000;
BA_ "GenSigStartValue" SG_ 2566860963 BMS3_ADB_MIN_Charging_Temp 1000;
BA_ "GenSigStartValue" SG_ 2566857379 BMS3_ADB_M3_Temperature_1 60;
BA_ "GenSigStartValue" SG_ 2566857379 BMS3_ADB_M3_Temperature_2 60;
BA_ "GenSigStartValue" SG_ 2566857379 BMS3_ADB_M3_Temperature_3 60;
BA_ "GenSigStartValue" SG_ 2566857379 BMS3_ADB_M3_Reserved_Dis1 255;
BA_ "GenSigStartValue" SG_ 2566857379 BMS3_ADB_M3_Reserved_Dis2 255;
BA_ "GenSigStartValue" SG_ 2566857123 BMS3_ADB_M2_Temperature_1 60;
BA_ "GenSigStartValue" SG_ 2566857123 BMS3_ADB_M2_Temperature_2 60;
BA_ "GenSigStartValue" SG_ 2566857123 BMS3_ADB_M2_Temperature_3 60;
BA_ "GenSigStartValue" SG_ 2566857123 BMS3_ADB_M2_Reserved_Dis1 255;
BA_ "GenSigStartValue" SG_ 2566857123 BMS3_ADB_M2_Reserved_Dis2 255;
BA_ "GenSigStartValue" SG_ 2566856867 BMS3_ADB_M1_Temperature_1 60;
BA_ "GenSigStartValue" SG_ 2566856867 BMS3_ADB_M1_Temperature_2 60;
BA_ "GenSigStartValue" SG_ 2566856867 BMS3_ADB_M1_Temperature_3 60;
BA_ "GenSigStartValue" SG_ 2566856867 BMS3_ADB_M1_Reserved_Dis1 255;
BA_ "GenSigStartValue" SG_ 2566856867 BMS3_ADB_M1_Reserved_Dis2 255;
BA_ "GenSigStartValue" SG_ 2566855331 BMS3_ADB_M3_FuelGauge1_Temp 1000;
BA_ "GenSigStartValue" SG_ 2566855331 BMS3_ADB_M3_Thermistor1_temp 1000;
BA_ "GenSigStartValue" SG_ 2566855331 BMS3_ADB_M3_Thermistor2_temp 1000;
BA_ "GenSigStartValue" SG_ 2566855331 BMS3_ADB_M3_FuelGauge2_Temp 1000;
BA_ "GenSigStartValue" SG_ 2566855075 BMS3_ADB_M2_FuelGauge1_Temp 1000;
BA_ "GenSigStartValue" SG_ 2566855075 BMS3_ADB_M2_Thermistor1_temp 1000;
BA_ "GenSigStartValue" SG_ 2566855075 BMS3_ADB_M2_Thermistor2_temp 1000;
BA_ "GenSigStartValue" SG_ 2566855075 BMS3_ADB_M2_FuelGauge2_Temp 1000;
BA_ "GenSigStartValue" SG_ 2566854819 BMS3_ADB_M1_FuelGauge1_Temp 1000;
BA_ "GenSigStartValue" SG_ 2566854819 BMS3_ADB_M1_Thermistor1_temp 1000;
BA_ "GenSigStartValue" SG_ 2566854819 BMS3_ADB_M1_Thermistor2_temp 1000;
BA_ "GenSigStartValue" SG_ 2566854819 BMS3_ADB_M1_FuelGauge2_Temp 1000;
BA_ "GenSigStartValue" SG_ 2566849187 BMS3_ADB_Maximum_Temperature 1000;
BA_ "GenSigStartValue" SG_ 2566849187 BMS3_ADB_Minimum_Temperature 1000;
BA_ "GenSigStartValue" SG_ 2566849187 BMS3_ADB_Average_Temperature 1000;
BA_ "GenSigStartValue" SG_ 2566848675 BMS3_ADB_Batt_Average_Current 55;
BA_ "GenSigStartValue" SG_ 2566803619 BMS3_ADB_Battery1_Temperature 40;
BA_ "GenSigStartValue" SG_ 2566803619 _nu_BMS3_ADB_Battery2_Temp 40;
VAL_ 2550202258 ALS_DX_POS_12_status 15 "NOT_AVAILABLE" 14 "TYPE_14_NU" 13 "TYPE_13_NU" 12 "TYPE_12_NU" 11 "TYPE_11_NU" 10 "TYPE_10_NU" 9 "TYPE_09_NU" 8 "TYPE_08_NU" 7 "TYPE_07_NU" 6 "TYPE_06_NU" 5 "TYPE_05_NU" 4 "TYPE_04_NU" 3 "TYPE_03_MP" 2 "TYPE_02_AP" 1 "TYPE_01_HE" 0 "EMPTY" ;
VAL_ 2550202258 ALS_DX_POS_11_status 15 "NOT_AVAILABLE" 14 "TYPE_14_NU" 13 "TYPE_13_NU" 12 "TYPE_12_NU" 11 "TYPE_11_NU" 10 "TYPE_10_NU" 9 "TYPE_09_NU" 8 "TYPE_08_NU" 7 "TYPE_07_NU" 6 "TYPE_06_NU" 5 "TYPE_05_NU" 4 "TYPE_04_NU" 3 "TYPE_03_MP" 2 "TYPE_02_AP" 1 "TYPE_01_HE" 0 "EMPTY" ;
VAL_ 2550202258 ALS_DX_POS_10_status 15 "NOT_AVAILABLE" 14 "TYPE_14_NU" 13 "TYPE_13_NU" 12 "TYPE_12_NU" 11 "TYPE_11_NU" 10 "TYPE_10_NU" 9 "TYPE_09_NU" 8 "TYPE_08_NU" 7 "TYPE_07_NU" 6 "TYPE_06_NU" 5 "TYPE_05_NU" 4 "TYPE_04_NU" 3 "TYPE_03_MP" 2 "TYPE_02_AP" 1 "TYPE_01_HE" 0 "EMPTY" ;
VAL_ 2550202258 ALS_DX_POS_09_status 15 "NOT_AVAILABLE" 14 "TYPE_14_NU" 13 "TYPE_13_NU" 12 "TYPE_12_NU" 11 "TYPE_11_NU" 10 "TYPE_10_NU" 9 "TYPE_09_NU" 8 "TYPE_08_NU" 7 "TYPE_07_NU" 6 "TYPE_06_NU" 5 "TYPE_05_NU" 4 "TYPE_04_NU" 3 "TYPE_03_MP" 2 "TYPE_02_AP" 1 "TYPE_01_HE" 0 "EMPTY" ;
VAL_ 2550202258 ALS_DX_POS_08_status 15 "NOT_AVAILABLE" 14 "TYPE_14_NU" 13 "TYPE_13_NU" 12 "TYPE_12_NU" 11 "TYPE_11_NU" 10 "TYPE_10_NU" 9 "TYPE_09_NU" 8 "TYPE_08_NU" 7 "TYPE_07_NU" 6 "TYPE_06_NU" 5 "TYPE_05_NU" 4 "TYPE_04_NU" 3 "TYPE_03_MP" 2 "TYPE_02_AP" 1 "TYPE_01_HE" 0 "EMPTY" ;
VAL_ 2550202258 ALS_DX_POS_07_status 15 "NOT_AVAILABLE" 14 "TYPE_14_NU" 13 "TYPE_13_NU" 12 "TYPE_12_NU" 11 "TYPE_11_NU" 10 "TYPE_10_NU" 9 "TYPE_09_NU" 8 "TYPE_08_NU" 7 "TYPE_07_NU" 6 "TYPE_06_NU" 5 "TYPE_05_NU" 4 "TYPE_04_NU" 3 "TYPE_03_MP" 2 "TYPE_02_AP" 1 "TYPE_01_HE" 0 "EMPTY" ;
VAL_ 2550202258 ALS_DX_POS_06_status 15 "NOT_AVAILABLE" 14 "TYPE_14_NU" 13 "TYPE_13_NU" 12 "TYPE_12_NU" 11 "TYPE_11_NU" 10 "TYPE_10_NU" 9 "TYPE_09_NU" 8 "TYPE_08_NU" 7 "TYPE_07_NU" 6 "TYPE_06_NU" 5 "TYPE_05_NU" 4 "TYPE_04_NU" 3 "TYPE_03_MP" 2 "TYPE_02_AP" 1 "TYPE_01_HE" 0 "EMPTY" ;
VAL_ 2550202258 ALS_DX_POS_05_status 15 "NOT_AVAILABLE" 14 "TYPE_14_NU" 13 "TYPE_13_NU" 12 "TYPE_12_NU" 11 "TYPE_11_NU" 10 "TYPE_10_NU" 9 "TYPE_09_NU" 8 "TYPE_08_NU" 7 "TYPE_07_NU" 6 "TYPE_06_NU" 5 "TYPE_05_NU" 4 "TYPE_04_NU" 3 "TYPE_03_MP" 2 "TYPE_02_AP" 1 "TYPE_01_HE" 0 "EMPTY" ;
VAL_ 2550202258 ALS_DX_POS_04_status 15 "NOT_AVAILABLE" 14 "TYPE_14_NU" 13 "TYPE_13_NU" 12 "TYPE_12_NU" 11 "TYPE_11_NU" 10 "TYPE_10_NU" 9 "TYPE_09_NU" 8 "TYPE_08_NU" 7 "TYPE_07_NU" 6 "TYPE_06_NU" 5 "TYPE_05_NU" 4 "TYPE_04_NU" 3 "TYPE_03_MP" 2 "TYPE_02_AP" 1 "TYPE_01_HE" 0 "EMPTY" ;
VAL_ 2550202258 ALS_DX_POS_03_status 15 "NOT_AVAILABLE" 14 "TYPE_14_NU" 13 "TYPE_13_NU" 12 "TYPE_12_NU" 11 "TYPE_11_NU" 10 "TYPE_10_NU" 9 "TYPE_09_NU" 8 "TYPE_08_NU" 7 "TYPE_07_NU" 6 "TYPE_06_NU" 5 "TYPE_05_NU" 4 "TYPE_04_NU" 3 "TYPE_03_MP" 2 "TYPE_02_AP" 1 "TYPE_01_HE" 0 "EMPTY" ;
VAL_ 2550202258 ALS_DX_POS_02_status 15 "NOT_AVAILABLE" 14 "TYPE_14_NU" 13 "TYPE_13_NU" 12 "TYPE_12_NU" 11 "TYPE_11_NU" 10 "TYPE_10_NU" 9 "TYPE_09_NU" 8 "TYPE_08_NU" 7 "TYPE_07_NU" 6 "TYPE_06_NU" 5 "TYPE_05_NU" 4 "TYPE_04_NU" 3 "TYPE_03_MP" 2 "TYPE_02_AP" 1 "TYPE_01_HE" 0 "EMPTY" ;
VAL_ 2550202258 ALS_DX_POS_01_status 15 "NOT_AVAILABLE" 14 "TYPE_14_NU" 13 "TYPE_13_NU" 12 "TYPE_12_NU" 11 "TYPE_11_NU" 10 "TYPE_10_NU" 9 "TYPE_09_NU" 8 "TYPE_08_NU" 7 "TYPE_07_NU" 6 "TYPE_06_NU" 5 "TYPE_05_NU" 4 "TYPE_04_NU" 3 "TYPE_03_MP" 2 "TYPE_02_AP" 1 "TYPE_01_HE" 0 "EMPTY" ;
VAL_ 2550202257 ALS_SX_POS_12_status 15 "NOT_AVAILABLE" 14 "TYPE_14_NU" 13 "TYPE_13_NU" 12 "TYPE_12_NU" 11 "TYPE_11_NU" 10 "TYPE_10_NU" 9 "TYPE_09_NU" 8 "TYPE_08_NU" 7 "TYPE_07_NU" 6 "TYPE_06_NU" 5 "TYPE_05_NU" 4 "TYPE_04_NU" 3 "TYPE_03_MP" 2 "TYPE_02_AP" 1 "TYPE_01_HE" 0 "EMPTY" ;
VAL_ 2550202257 ALS_SX_POS_11_status 15 "NOT_AVAILABLE" 14 "TYPE_14_NU" 13 "TYPE_13_NU" 12 "TYPE_12_NU" 11 "TYPE_11_NU" 10 "TYPE_10_NU" 9 "TYPE_09_NU" 8 "TYPE_08_NU" 7 "TYPE_07_NU" 6 "TYPE_06_NU" 5 "TYPE_05_NU" 4 "TYPE_04_NU" 3 "TYPE_03_MP" 2 "TYPE_02_AP" 1 "TYPE_01_HE" 0 "EMPTY" ;
VAL_ 2550202257 ALS_SX_POS_10_status 15 "NOT_AVAILABLE" 14 "TYPE_14_NU" 13 "TYPE_13_NU" 12 "TYPE_12_NU" 11 "TYPE_11_NU" 10 "TYPE_10_NU" 9 "TYPE_09_NU" 8 "TYPE_08_NU" 7 "TYPE_07_NU" 6 "TYPE_06_NU" 5 "TYPE_05_NU" 4 "TYPE_04_NU" 3 "TYPE_03_MP" 2 "TYPE_02_AP" 1 "TYPE_01_HE" 0 "EMPTY" ;
VAL_ 2550202257 ALS_SX_POS_09_status 15 "NOT_AVAILABLE" 14 "TYPE_14_NU" 13 "TYPE_13_NU" 12 "TYPE_12_NU" 11 "TYPE_11_NU" 10 "TYPE_10_NU" 9 "TYPE_09_NU" 8 "TYPE_08_NU" 7 "TYPE_07_NU" 6 "TYPE_06_NU" 5 "TYPE_05_NU" 4 "TYPE_04_NU" 3 "TYPE_03_MP" 2 "TYPE_02_AP" 1 "TYPE_01_HE" 0 "EMPTY" ;
VAL_ 2550202257 ALS_SX_POS_08_status 15 "NOT_AVAILABLE" 14 "TYPE_14_NU" 13 "TYPE_13_NU" 12 "TYPE_12_NU" 11 "TYPE_11_NU" 10 "TYPE_10_NU" 9 "TYPE_09_NU" 8 "TYPE_08_NU" 7 "TYPE_07_NU" 6 "TYPE_06_NU" 5 "TYPE_05_NU" 4 "TYPE_04_NU" 3 "TYPE_03_MP" 2 "TYPE_02_AP" 1 "TYPE_01_HE" 0 "EMPTY" ;
VAL_ 2550202257 ALS_SX_POS_07_status 15 "NOT_AVAILABLE" 14 "TYPE_14_NU" 13 "TYPE_13_NU" 12 "TYPE_12_NU" 11 "TYPE_11_NU" 10 "TYPE_10_NU" 9 "TYPE_09_NU" 8 "TYPE_08_NU" 7 "TYPE_07_NU" 6 "TYPE_06_NU" 5 "TYPE_05_NU" 4 "TYPE_04_NU" 3 "TYPE_03_MP" 2 "TYPE_02_AP" 1 "TYPE_01_HE" 0 "EMPTY" ;
VAL_ 2550202257 ALS_SX_POS_06_status 15 "NOT_AVAILABLE" 14 "TYPE_14_NU" 13 "TYPE_13_NU" 12 "TYPE_12_NU" 11 "TYPE_11_NU" 10 "TYPE_10_NU" 9 "TYPE_09_NU" 8 "TYPE_08_NU" 7 "TYPE_07_NU" 6 "TYPE_06_NU" 5 "TYPE_05_NU" 4 "TYPE_04_NU" 3 "TYPE_03_MP" 2 "TYPE_02_AP" 1 "TYPE_01_HE" 0 "EMPTY" ;
VAL_ 2550202257 ALS_SX_POS_05_status 15 "NOT_AVAILABLE" 14 "TYPE_14_NU" 13 "TYPE_13_NU" 12 "TYPE_12_NU" 11 "TYPE_11_NU" 10 "TYPE_10_NU" 9 "TYPE_09_NU" 8 "TYPE_08_NU" 7 "TYPE_07_NU" 6 "TYPE_06_NU" 5 "TYPE_05_NU" 4 "TYPE_04_NU" 3 "TYPE_03_MP" 2 "TYPE_02_AP" 1 "TYPE_01_HE" 0 "EMPTY" ;
VAL_ 2550202257 ALS_SX_POS_04_status 15 "NOT_AVAILABLE" 14 "TYPE_14_NU" 13 "TYPE_13_NU" 12 "TYPE_12_NU" 11 "TYPE_11_NU" 10 "TYPE_10_NU" 9 "TYPE_09_NU" 8 "TYPE_08_NU" 7 "TYPE_07_NU" 6 "TYPE_06_NU" 5 "TYPE_05_NU" 4 "TYPE_04_NU" 3 "TYPE_03_MP" 2 "TYPE_02_AP" 1 "TYPE_01_HE" 0 "EMPTY" ;
VAL_ 2550202257 ALS_SX_POS_03_status 15 "NOT_AVAILABLE" 14 "TYPE_14_NU" 13 "TYPE_13_NU" 12 "TYPE_12_NU" 11 "TYPE_11_NU" 10 "TYPE_10_NU" 9 "TYPE_09_NU" 8 "TYPE_08_NU" 7 "TYPE_07_NU" 6 "TYPE_06_NU" 5 "TYPE_05_NU" 4 "TYPE_04_NU" 3 "TYPE_03_MP" 2 "TYPE_02_AP" 1 "TYPE_01_HE" 0 "EMPTY" ;
VAL_ 2550202257 ALS_SX_POS_02_status 15 "NOT_AVAILABLE" 14 "TYPE_14_NU" 13 "TYPE_13_NU" 12 "TYPE_12_NU" 11 "TYPE_11_NU" 10 "TYPE_10_NU" 9 "TYPE_09_NU" 8 "TYPE_08_NU" 7 "TYPE_07_NU" 6 "TYPE_06_NU" 5 "TYPE_05_NU" 4 "TYPE_04_NU" 3 "TYPE_03_MP" 2 "TYPE_02_AP" 1 "TYPE_01_HE" 0 "EMPTY" ;
VAL_ 2550202257 ALS_SX_POS_01_status 15 "NOT_AVAILABLE" 14 "TYPE_14_NU" 13 "TYPE_13_NU" 12 "TYPE_12_NU" 11 "TYPE_11_NU" 10 "TYPE_10_NU" 9 "TYPE_09_NU" 8 "TYPE_08_NU" 7 "TYPE_07_NU" 6 "TYPE_06_NU" 5 "TYPE_05_NU" 4 "TYPE_04_NU" 3 "TYPE_03_MP" 2 "TYPE_02_AP" 1 "TYPE_01_HE" 0 "EMPTY" ;
VAL_ 2550210900 SVS_Turret_Hatch_Right_Status 3 "NOT_AVAILABLE" 2 "ERROR" 1 "OPEN" 0 "CLOSE" ;
VAL_ 2550210900 SVS_Turret_Hatch_Left_Status 3 "NOT_AVAILABLE" 2 "ERROR" 1 "OPEN" 0 "CLOSE" ;
VAL_ 2550210900 SVS_Battle_Short_Status 3 "NOT_AVAILABLE" 2 "ERROR" 1 "ACTIVE" 0 "NOT_ACTIVE" ;
VAL_ 2559071265 ALS_Configuration 3 "BOTH_NOT_PRESENT" 2 "SX_NOT_PRESENT" 1 "DX_NOT_PRESENT" 0 "BOTH_PRESENT" ;
VAL_ 2559071265 TLC_07_used_by_driver 1 "Not_used" 0 "Used" ;
VAL_ 2559071265 TLC_06_used_by_driver 1 "Not_used" 0 "Used" ;
VAL_ 2559071265 TLC_05_used_by_driver 1 "Not_used" 0 "Used" ;
VAL_ 2559071265 TLC_04_used_by_driver 1 "Not_used" 0 "Used" ;
VAL_ 2559071265 TLC_03_used_by_driver 1 "Not_used" 0 "Used" ;
VAL_ 2559071265 TLC_02_used_by_driver 1 "Not_used" 0 "Used" ;
VAL_ 2559071265 TLC_01_used_by_driver 1 "Not_used" 0 "Used" ;
VAL_ 2559071265 TLC_00_used_by_driver 1 "Not_used" 0 "Used" ;
VAL_ 2559071265 TypeOfVideoSignal_Output 2 "DOUBLE_MONITOR" 1 "COMPOSITE_MONITOR" 0 "NOT_REQUIRED" ;
VAL_ 2559005729 InputType_15 3 "NOT_VALID" 2 "RESERVED" 1 "INPUT_CAMERA" 0 "NOT_CONNECTED" ;
VAL_ 2559005729 InputType_14 3 "NOT_VALID" 2 "RESERVED" 1 "INPUT_CAMERA" 0 "NOT_CONNECTED" ;
VAL_ 2559005729 InputType_13 3 "NOT_VALID" 2 "RESERVED" 1 "INPUT_CAMERA" 0 "NOT_CONNECTED" ;
VAL_ 2559005729 InputType_12 3 "NOT_VALID" 2 "RESERVED" 1 "INPUT_CAMERA" 0 "NOT_CONNECTED" ;
VAL_ 2559005729 InputType_11 3 "NOT_VALID" 2 "RESERVED" 1 "INPUT_CAMERA" 0 "NOT_CONNECTED" ;
VAL_ 2559005729 InputType_10 3 "NOT_VALID" 2 "RESERVED" 1 "INPUT_CAMERA" 0 "NOT_CONNECTED" ;
VAL_ 2559005729 InputType_09 3 "NOT_VALID" 2 "RESERVED" 1 "INPUT_CAMERA" 0 "NOT_CONNECTED" ;
VAL_ 2559005729 InputType_08 3 "NOT_VALID" 2 "RESERVED" 1 "INPUT_CAMERA" 0 "NOT_CONNECTED" ;
VAL_ 2558940193 InputType_07 3 "NOT_VALID" 2 "RESERVED" 1 "INPUT_CAMERA" 0 "NOT_CONNECTED" ;
VAL_ 2558940193 InputType_06 3 "NOT_VALID" 2 "RESERVED" 1 "INPUT_CAMERA" 0 "NOT_CONNECTED" ;
VAL_ 2558940193 InputType_05 3 "NOT_VALID" 2 "RESERVED" 1 "INPUT_CAMERA" 0 "NOT_CONNECTED" ;
VAL_ 2558940193 InputType_04 3 "NOT_VALID" 2 "RESERVED" 1 "INPUT_CAMERA" 0 "NOT_CONNECTED" ;
VAL_ 2558940193 InputType_03 3 "NOT_VALID" 2 "RESERVED" 1 "INPUT_CAMERA" 0 "NOT_CONNECTED" ;
VAL_ 2558940193 InputType_02 3 "NOT_VALID" 2 "RESERVED" 1 "INPUT_CAMERA" 0 "NOT_CONNECTED" ;
VAL_ 2558940193 InputType_01 3 "NOT_VALID" 2 "RESERVED" 1 "INPUT_CAMERA" 0 "NOT_CONNECTED" ;
VAL_ 2558940193 InputType_00 3 "NOT_VALID" 2 "RESERVED" 1 "INPUT_CAMERA" 0 "NOT_CONNECTED" ;
VAL_ 2550145364 SVS_IN_31_status 3 "NOT_AVAILABLE_3" 2 "ERROR" 1 "CONNECTED" 0 "NOT_CONNECTED" ;
VAL_ 2550145364 SVS_IN_30_status 3 "NOT_AVAILABLE_3" 2 "ERROR" 1 "CONNECTED" 0 "NOT_CONNECTED" ;
VAL_ 2550145364 SVS_IN_29_status 3 "NOT_AVAILABLE_3" 2 "ERROR" 1 "CONNECTED" 0 "NOT_CONNECTED" ;
VAL_ 2550145364 SVS_IN_28_status 3 "NOT_AVAILABLE_3" 2 "ERROR" 1 "CONNECTED" 0 "NOT_CONNECTED" ;
VAL_ 2550145364 SVS_IN_27_status 3 "NOT_AVAILABLE_3" 2 "ERROR" 1 "CONNECTED" 0 "NOT_CONNECTED" ;
VAL_ 2550145364 SVS_IN_26_status 3 "NOT_AVAILABLE_3" 2 "ERROR" 1 "CONNECTED" 0 "NOT_CONNECTED" ;
VAL_ 2550145364 SVS_IN_25_status 3 "NOT_AVAILABLE_3" 2 "ERROR" 1 "CONNECTED" 0 "NOT_CONNECTED" ;
VAL_ 2550145364 SVS_IN_24_status 3 "NOT_AVAILABLE_3" 2 "ERROR" 1 "CONNECTED" 0 "NOT_CONNECTED" ;
VAL_ 2550145364 SVS_IN_23_status 3 "NOT_AVAILABLE_3" 2 "ERROR" 1 "CONNECTED" 0 "NOT_CONNECTED" ;
VAL_ 2550145364 SVS_IN_22_status 3 "NOT_AVAILABLE_3" 2 "ERROR" 1 "CONNECTED" 0 "NOT_CONNECTED" ;
VAL_ 2550145364 SVS_IN_21_status 3 "NOT_AVAILABLE_3" 2 "ERROR" 1 "CONNECTED" 0 "NOT_CONNECTED" ;
VAL_ 2550145364 SVS_IN_20_status 3 "NOT_AVAILABLE_3" 2 "ERROR" 1 "CONNECTED" 0 "NOT_CONNECTED" ;
VAL_ 2550145364 SVS_IN_19_status 3 "NOT_AVAILABLE_3" 2 "ERROR" 1 "CONNECTED" 0 "NOT_CONNECTED" ;
VAL_ 2550145364 SVS_IN_18_status 3 "NOT_AVAILABLE_3" 2 "ERROR" 1 "CONNECTED" 0 "NOT_CONNECTED" ;
VAL_ 2550145364 SVS_IN_17_status 3 "NOT_AVAILABLE_3" 2 "ERROR" 1 "CONNECTED" 0 "NOT_CONNECTED" ;
VAL_ 2550145364 SVS_IN_16_status 3 "NOT_AVAILABLE_3" 2 "ERROR" 1 "CONNECTED" 0 "NOT_CONNECTED" ;
VAL_ 2550145364 SVS_IN_15_status 3 "NOT_AVAILABLE_3" 2 "ERROR" 1 "CONNECTED" 0 "NOT_CONNECTED" ;
VAL_ 2550145364 SVS_IN_14_status 3 "NOT_AVAILABLE_3" 2 "ERROR" 1 "CONNECTED" 0 "NOT_CONNECTED" ;
VAL_ 2550145364 SVS_IN_13_status 3 "NOT_AVAILABLE_3" 2 "ERROR" 1 "CONNECTED" 0 "NOT_CONNECTED" ;
VAL_ 2550145364 SVS_IN_12_status 3 "NOT_AVAILABLE_3" 2 "ERROR" 1 "CONNECTED" 0 "NOT_CONNECTED" ;
VAL_ 2550145364 SVS_IN_11_status 3 "NOT_AVAILABLE_3" 2 "ERROR" 1 "CONNECTED" 0 "NOT_CONNECTED" ;
VAL_ 2550145364 SVS_IN_10_status 3 "NOT_AVAILABLE_3" 2 "ERROR" 1 "CONNECTED" 0 "NOT_CONNECTED" ;
VAL_ 2550145364 SVS_IN_09_status 3 "NOT_AVAILABLE_3" 2 "ERROR" 1 "CONNECTED" 0 "NOT_CONNECTED" ;
VAL_ 2550145364 SVS_IN_08_status 3 "NOT_AVAILABLE_3" 2 "ERROR" 1 "CONNECTED" 0 "NOT_CONNECTED" ;
VAL_ 2550145364 SVS_IN_07_status 3 "NOT_AVAILABLE_3" 2 "ERROR" 1 "CONNECTED" 0 "NOT_CONNECTED" ;
VAL_ 2550145364 SVS_IN_06_status 3 "NOT_AVAILABLE_3" 2 "ERROR" 1 "CONNECTED" 0 "NOT_CONNECTED" ;
VAL_ 2550145364 SVS_IN_05_status 3 "NOT_AVAILABLE_3" 2 "ERROR" 1 "CONNECTED" 0 "NOT_CONNECTED" ;
VAL_ 2550145364 SVS_IN_04_status 3 "NOT_AVAILABLE_3" 2 "ERROR" 1 "CONNECTED" 0 "NOT_CONNECTED" ;
VAL_ 2550145364 SVS_IN_03_status 3 "NOT_AVAILABLE_3" 2 "ERROR" 1 "CONNECTED" 0 "NOT_CONNECTED" ;
VAL_ 2550145364 SVS_IN_02_status 3 "NOT_AVAILABLE_3" 2 "ERROR" 1 "CONNECTED" 0 "NOT_CONNECTED" ;
VAL_ 2550145364 SVS_IN_01_status 3 "NOT_AVAILABLE_3" 2 "ERROR" 1 "CONNECTED" 0 "NOT_CONNECTED" ;
VAL_ 2550145364 SVS_IN_00_status 3 "NOT_AVAILABLE_3" 2 "ERROR" 1 "CONNECTED" 0 "NOT_CONNECTED" ;
VAL_ 2550158369 CCBC_DCAM_Preset 15 "NOT_USED" 14 "NOT_USED" 13 "NOT_USED" 12 "NOT_USED" 11 "NOT_USED" 10 "NOT_USED" 9 "NOT_USED" 8 "NORMAL_LUX_SET" 7 "NOT_USED" 6 "NOT_USED" 5 "NOT_USED" 4 "HIGH_LUX_SET" 3 "NOT_USED" 2 "LOW_LUX_SET" 1 "ULTRALOW_LUX_SET" 0 "UNCHANGED" ;
VAL_ 2550158369 CCBC_TI_NUC_mode_reset_p1 15 "NOT_USED" 14 "NOT_USED" 13 "NOT_USED" 12 "NOT_USED" 11 "NOT_USED" 10 "NOT_USED" 9 "NOT_USED" 8 "AUTOMATIC_NUC" 7 "NOT_USED" 6 "NOT_USED" 5 "NOT_USED" 4 "TI_CAMERA_DEFAULT" 3 "NOT_USED" 2 "NUC_INTERNAL" 1 "NUC_EXTERNAL" 0 "UNCHANGED" ;
VAL_ 2550158369 CCBC_ProtectiveLid 3 "NOT_USED" 2 "OPEN" 1 "CLOSE" 0 "UNCHANGED" ;
VAL_ 2550158369 CCBC_VideoSource_ch0 3 "NOT_USED" 2 "DCAM" 1 "TI" 0 "UNCHANGED" ;
VAL_ 2550158369 CCBC_TI_DDE 3 "NOT_USED" 2 "OFF" 1 "ON" 0 "UNCHANGED" ;
VAL_ 2550158369 CCBC_HorizontalFlip 3 "NOT_USED" 2 "OFF" 1 "ON" 0 "UNCHANGED" ;
VAL_ 2550158369 CCBC_OverlayGraphics 3 "NOT_USED" 2 "OFF" 1 "ON" 0 "UNCHANGED" ;
VAL_ 2550158369 CCBC_VideoSource_ch1 3 "NOT_USED" 2 "DCAM" 1 "TI" 0 "UNCHANGED" ;
VAL_ 2550158369 CCBC_TI_Polarity 3 "NOT_USED" 2 "BLACK_HOT" 1 "WHITE_HOT" 0 "UNCHANGED" ;
VAL_ 2550158369 CCBC_TI_Zoom 3 "NOT_USED" 2 "x2_ZOOM" 1 "x1_ZOOM" 0 "UNCHANGED" ;
VAL_ 2550158369 CCBC_TI_ROI 15 "NOT_USED" 14 "NOT_USED" 13 "NOT_USED" 12 "NOT_USED" 11 "NOT_USED" 10 "NOT_USED" 9 "NOT_USED" 8 "TOP_HALF" 7 "NOT_USED" 6 "NOT_USED" 5 "NOT_USED" 4 "CENTER_BLOCK" 3 "NOT_USED" 2 "BOTTOM_HALF" 1 "FULL_SCREEN" 0 "UNCHANGED" ;
VAL_ 2550158369 CCBC_VideoBlending_ch0 15 "NOT_USED" 14 "NOT_USED" 13 "NOT_USED" 12 "NOT_USED" 11 "NOT_USED" 10 "NOT_USED" 9 "NOT_USED" 8 "INCREASE_DCAM_AMOUNT" 7 "NOT_USED" 6 "NOT_USED" 5 "NOT_USED" 4 "INCREASE_TI_AMOUNT" 3 "NOT_USED" 2 "OFF_-_ONLY_TI" 1 "ON_-_EQUAL_TI_and_DCAM" 0 "UNCHANGED" ;
VAL_ 2550158369 CCBC_TI_NUC_mode_reset_p2 1 "AUTOMATIC_NUC_DISABLED" 0 "AUTOMATIC_NUC_ENABLED" ;
VAL_ 2550158369 CCBC_WindowHeaters 1 "REQUEST_ENABLED" 0 "NOT_REQUESTED" ;
VAL_ 2550158369 CCBC_TLC_07_Requested 1 "YES" 0 "NO" ;
VAL_ 2550158369 CCBC_TLC_06_Requested 1 "YES" 0 "NO" ;
VAL_ 2550158369 CCBC_TLC_05_Requested 1 "YES" 0 "NO" ;
VAL_ 2550158369 CCBC_TLC_04_Requested 1 "YES" 0 "NO" ;
VAL_ 2550158369 CCBC_TLC_03_Requested 1 "YES" 0 "NO" ;
VAL_ 2550158369 CCBC_TLC_02_Requested 1 "YES" 0 "NO" ;
VAL_ 2550158369 CCBC_TLC_01_Requested 1 "YES" 0 "NO" ;
VAL_ 2550158369 CCBC_TLC_00_Requested 1 "YES" 0 "NO" ;
VAL_ 2015 IM_VideoSource_ch1 1 "DCAM" 0 "TI" ;
VAL_ 2015 IM_ImageBlending_Available 1 "AVAILABLE" 0 "NOT_AVAILABLE" ;
VAL_ 2015 IM_DCAM_Available 1 "AVAILABLE" 0 "NOT_AVAILABLE" ;
VAL_ 2015 IM_TI_Available 1 "AVAILABLE" 0 "NOT_AVAILABLE" ;
VAL_ 2015 IM_Humidity_TooHigh 1 "HUMIDITY_TOO_HIGH" 0 "HUMIDITY_OK" ;
VAL_ 2015 IM_Temperature_TooHigh 1 "TEMPERATURE_TOO_HIGH" 0 "TEMPERATURE_OK" ;
VAL_ 2015 IM_POST_Failed 1 "FAILED" 0 "OK" ;
VAL_ 2015 IM_TI_Zoom 3 "NOT_USED" 2 "x2_ZOOM" 1 "x1_ZOOM" 0 "NOT_USED" ;
VAL_ 2015 IM_VideoHeaters 1 "ON" 0 "OFF" ;
VAL_ 2015 IM_HorizontalFlip 1 "ON" 0 "OFF" ;
VAL_ 2015 IM_NUC 1 "Automatic_NUC" 0 "Manual_NUC" ;
VAL_ 2015 IM_VideoBlendingMode 1 "ON" 0 "OFF" ;
VAL_ 2015 IM_DCAM_Preset 3 "ULTRALOW_LUX_SET" 2 "LOW_LUX_SET" 1 "HIGH_LUX_SET" 0 "NORMAL_LUX_SET" ;
VAL_ 2015 IM_ProtectiveLid 1 "OPEN" 0 "CLOSED" ;
VAL_ 2015 IM_VideoSource_ch0 1 "DCAM" 0 "TI" ;
VAL_ 2015 IM_PAL_Stretch 1 "REQUIRED" 0 "NOT_REQUIRED" ;
VAL_ 2015 IM_TI_DDE 1 "ON" 0 "OFF" ;
VAL_ 2015 IM_OverlayGraphic 1 "ON" 0 "OFF" ;
VAL_ 2015 IM_ROI 3 "TOP_HALF" 2 "CENTER_BLOCK" 1 "BOTTOM_HALF" 0 "FULL_SCREEN" ;
VAL_ 2015 IM_TI_Polarity 1 "BLACK_HOT" 0 "WHITE_HOT" ;
VAL_ 1416 CCD_DCAM_Preset 15 "NOT_USED" 14 "NOT_USED" 13 "NOT_USED" 12 "NOT_USED" 11 "NOT_USED" 10 "NOT_USED" 9 "NOT_USED" 8 "NORMAL_LUX_SET" 7 "NOT_USED" 6 "NOT_USED" 5 "NOT_USED" 4 "HIGH_LUX_SET" 3 "NOT_USED" 2 "LOW_LUX_SET" 1 "ULTRALOW_LUX_SET" 0 "UNCHANGED" ;
VAL_ 1416 CCD_TI_NUC_mode_reset_p1 15 "NOT_USED" 14 "NOT_USED" 13 "NOT_USED" 12 "NOT_USED" 11 "NOT_USED" 10 "NOT_USED" 9 "NOT_USED" 8 "AUTOMATIC_NUC" 7 "NOT_USED" 6 "NOT_USED" 5 "NOT_USED" 4 "TI_CAMERA_DEFAULT" 3 "NOT_USED" 2 "NUC_INTERNAL" 1 "NUC_EXTERNAL" 0 "UNCHANGED" ;
VAL_ 1416 CCD_ProtectiveLid 3 "NOT_USED" 2 "OPEN" 1 "CLOSE" 0 "UNCHANGED" ;
VAL_ 1416 CCD_VideoSource_ch0 3 "NOT_USED" 2 "DCAM" 1 "TI" 0 "UNCHANGED" ;
VAL_ 1416 CCD_TI_DDE 3 "NOT_USED" 2 "OFF" 1 "ON" 0 "UNCHANGED" ;
VAL_ 1416 CCD_HorizontalFlip 3 "NOT_USED" 2 "OFF" 1 "ON" 0 "UNCHANGED" ;
VAL_ 1416 CCD_OverlayGraphics 3 "NOT_USED" 2 "OFF" 1 "ON" 0 "UNCHANGED" ;
VAL_ 1416 CCD_VideoSource_ch1 3 "NOT_USED" 2 "DCAM" 1 "TI" 0 "UNCHANGED" ;
VAL_ 1416 CCD_TI_Polarity 3 "NOT_USED" 2 "BLACK_HOT" 1 "WHITE_HOT" 0 "UNCHANGED" ;
VAL_ 1416 CCD_TI_Zoom 3 "NOT_USED" 2 "x2_ZOOM" 1 "x1_ZOOM" 0 "UNCHANGED" ;
VAL_ 1416 CCD_TI_ROI 15 "NOT_USED" 14 "NOT_USED" 13 "NOT_USED" 12 "NOT_USED" 11 "NOT_USED" 10 "NOT_USED" 9 "NOT_USED" 8 "TOP_HALF" 7 "NOT_USED" 6 "NOT_USED" 5 "NOT_USED" 4 "CENTER_BLOCK" 3 "NOT_USED" 2 "BOTTOM_HALF" 1 "FULL_SCREEN" 0 "UNCHANGED" ;
VAL_ 1416 CCD_VideoBlending_ch0 15 "NOT_USED" 14 "NOT_USED" 13 "NOT_USED" 12 "NOT_USED" 11 "NOT_USED" 10 "NOT_USED" 9 "NOT_USED" 8 "INCREASE_DCAM_AMOUNT" 7 "NOT_USED" 6 "NOT_USED" 5 "NOT_USED" 4 "INCREASE_TI_AMOUNT" 3 "NOT_USED" 2 "OFF_-_ONLY_TI" 1 "ON_-_EQUAL_TI_and_DCAM" 0 "UNCHANGED" ;
VAL_ 1416 CCD_TI_NUC_mode_reset_p2 1 "AUTOMATIC_NUC_DISABLED" 0 "AUTOMATIC_NUC_ENABLED" ;
VAL_ 1416 CCD_WindowHeaters 1 "REQUEST_ENABLED" 0 "NOT_REQUESTED" ;
VAL_ 1415 CC7_DCAM_Preset 15 "NOT_USED" 14 "NOT_USED" 13 "NOT_USED" 12 "NOT_USED" 11 "NOT_USED" 10 "NOT_USED" 9 "NOT_USED" 8 "NORMAL_LUX_SET" 7 "NOT_USED" 6 "NOT_USED" 5 "NOT_USED" 4 "HIGH_LUX_SET" 3 "NOT_USED" 2 "LOW_LUX_SET" 1 "ULTRALOW_LUX_SET" 0 "UNCHANGED" ;
VAL_ 1415 CC7_TI_NUC_mode_reset_p1 15 "NOT_USED" 14 "NOT_USED" 13 "NOT_USED" 12 "NOT_USED" 11 "NOT_USED" 10 "NOT_USED" 9 "NOT_USED" 8 "AUTOMATIC_NUC" 7 "NOT_USED" 6 "NOT_USED" 5 "NOT_USED" 4 "TI_CAMERA_DEFAULT" 3 "NOT_USED" 2 "NUC_INTERNAL" 1 "NUC_EXTERNAL" 0 "UNCHANGED" ;
VAL_ 1415 CC7_ProtectiveLid 3 "NOT_USED" 2 "OPEN" 1 "CLOSE" 0 "UNCHANGED" ;
VAL_ 1415 CC7_VideoSource_ch0 3 "NOT_USED" 2 "DCAM" 1 "TI" 0 "UNCHANGED" ;
VAL_ 1415 CC7_TI_DDE 3 "NOT_USED" 2 "OFF" 1 "ON" 0 "UNCHANGED" ;
VAL_ 1415 CC7_HorizontalFlip 3 "NOT_USED" 2 "OFF" 1 "ON" 0 "UNCHANGED" ;
VAL_ 1415 CC7_OverlayGraphics 3 "NOT_USED" 2 "OFF" 1 "ON" 0 "UNCHANGED" ;
VAL_ 1415 CC7_VideoSource_ch1 3 "NOT_USED" 2 "DCAM" 1 "TI" 0 "UNCHANGED" ;
VAL_ 1415 CC7_TI_Polarity 3 "NOT_USED" 2 "BLACK_HOT" 1 "WHITE_HOT" 0 "UNCHANGED" ;
VAL_ 1415 CC7_TI_Zoom 3 "NOT_USED" 2 "x2_ZOOM" 1 "x1_ZOOM" 0 "UNCHANGED" ;
VAL_ 1415 CC7_TI_ROI 15 "NOT_USED" 14 "NOT_USED" 13 "NOT_USED" 12 "NOT_USED" 11 "NOT_USED" 10 "NOT_USED" 9 "NOT_USED" 8 "TOP_HALF" 7 "NOT_USED" 6 "NOT_USED" 5 "NOT_USED" 4 "CENTER_BLOCK" 3 "NOT_USED" 2 "BOTTOM_HALF" 1 "FULL_SCREEN" 0 "UNCHANGED" ;
VAL_ 1415 CC7_VideoBlending_ch0 15 "NOT_USED" 14 "NOT_USED" 13 "NOT_USED" 12 "NOT_USED" 11 "NOT_USED" 10 "NOT_USED" 9 "NOT_USED" 8 "INCREASE_DCAM_AMOUNT" 7 "NOT_USED" 6 "NOT_USED" 5 "NOT_USED" 4 "INCREASE_TI_AMOUNT" 3 "NOT_USED" 2 "OFF_-_ONLY_TI" 1 "ON_-_EQUAL_TI_and_DCAM" 0 "UNCHANGED" ;
VAL_ 1415 CC7_TI_NUC_mode_reset_p2 1 "AUTOMATIC_NUC_DISABLED" 0 "AUTOMATIC_NUC_ENABLED" ;
VAL_ 1415 CC7_WindowHeaters 1 "REQUEST_ENABLED" 0 "NOT_REQUESTED" ;
VAL_ 1414 CC6_DCAM_Preset 15 "NOT_USED" 14 "NOT_USED" 13 "NOT_USED" 12 "NOT_USED" 11 "NOT_USED" 10 "NOT_USED" 9 "NOT_USED" 8 "NORMAL_LUX_SET" 7 "NOT_USED" 6 "NOT_USED" 5 "NOT_USED" 4 "HIGH_LUX_SET" 3 "NOT_USED" 2 "LOW_LUX_SET" 1 "ULTRALOW_LUX_SET" 0 "UNCHANGED" ;
VAL_ 1414 CC6_TI_NUC_mode_reset_p1 15 "NOT_USED" 14 "NOT_USED" 13 "NOT_USED" 12 "NOT_USED" 11 "NOT_USED" 10 "NOT_USED" 9 "NOT_USED" 8 "AUTOMATIC_NUC" 7 "NOT_USED" 6 "NOT_USED" 5 "NOT_USED" 4 "TI_CAMERA_DEFAULT" 3 "NOT_USED" 2 "NUC_INTERNAL" 1 "NUC_EXTERNAL" 0 "UNCHANGED" ;
VAL_ 1414 CC6_ProtectiveLid 3 "NOT_USED" 2 "OPEN" 1 "CLOSE" 0 "UNCHANGED" ;
VAL_ 1414 CC6_VideoSource_ch0 3 "NOT_USED" 2 "DCAM" 1 "TI" 0 "UNCHANGED" ;
VAL_ 1414 CC6_TI_DDE 3 "NOT_USED" 2 "OFF" 1 "ON" 0 "UNCHANGED" ;
VAL_ 1414 CC6_HorizontalFlip 3 "NOT_USED" 2 "OFF" 1 "ON" 0 "UNCHANGED" ;
VAL_ 1414 CC6_OverlayGraphics 3 "NOT_USED" 2 "OFF" 1 "ON" 0 "UNCHANGED" ;
VAL_ 1414 CC6_VideoSource_ch1 3 "NOT_USED" 2 "DCAM" 1 "TI" 0 "UNCHANGED" ;
VAL_ 1414 CC6_TI_Polarity 3 "NOT_USED" 2 "BLACK_HOT" 1 "WHITE_HOT" 0 "UNCHANGED" ;
VAL_ 1414 CC6_TI_Zoom 3 "NOT_USED" 2 "x2_ZOOM" 1 "x1_ZOOM" 0 "UNCHANGED" ;
VAL_ 1414 CC6_TI_ROI 15 "NOT_USED" 14 "NOT_USED" 13 "NOT_USED" 12 "NOT_USED" 11 "NOT_USED" 10 "NOT_USED" 9 "NOT_USED" 8 "TOP_HALF" 7 "NOT_USED" 6 "NOT_USED" 5 "NOT_USED" 4 "CENTER_BLOCK" 3 "NOT_USED" 2 "BOTTOM_HALF" 1 "FULL_SCREEN" 0 "UNCHANGED" ;
VAL_ 1414 CC6_VideoBlending_ch0 15 "NOT_USED" 14 "NOT_USED" 13 "NOT_USED" 12 "NOT_USED" 11 "NOT_USED" 10 "NOT_USED" 9 "NOT_USED" 8 "INCREASE_DCAM_AMOUNT" 7 "NOT_USED" 6 "NOT_USED" 5 "NOT_USED" 4 "INCREASE_TI_AMOUNT" 3 "NOT_USED" 2 "OFF_-_ONLY_TI" 1 "ON_-_EQUAL_TI_and_DCAM" 0 "UNCHANGED" ;
VAL_ 1414 CC6_TI_NUC_mode_reset_p2 1 "AUTOMATIC_NUC_DISABLED" 0 "AUTOMATIC_NUC_ENABLED" ;
VAL_ 1414 CC6_WindowHeaters 1 "REQUEST_ENABLED" 0 "NOT_REQUESTED" ;
VAL_ 1413 CC5_DCAM_Preset 15 "NOT_USED" 14 "NOT_USED" 13 "NOT_USED" 12 "NOT_USED" 11 "NOT_USED" 10 "NOT_USED" 9 "NOT_USED" 8 "NORMAL_LUX_SET" 7 "NOT_USED" 6 "NOT_USED" 5 "NOT_USED" 4 "HIGH_LUX_SET" 3 "NOT_USED" 2 "LOW_LUX_SET" 1 "ULTRALOW_LUX_SET" 0 "UNCHANGED" ;
VAL_ 1413 CC5_TI_NUC_mode_reset_p1 15 "NOT_USED" 14 "NOT_USED" 13 "NOT_USED" 12 "NOT_USED" 11 "NOT_USED" 10 "NOT_USED" 9 "NOT_USED" 8 "AUTOMATIC_NUC" 7 "NOT_USED" 6 "NOT_USED" 5 "NOT_USED" 4 "TI_CAMERA_DEFAULT" 3 "NOT_USED" 2 "NUC_INTERNAL" 1 "NUC_EXTERNAL" 0 "UNCHANGED" ;
VAL_ 1413 CC5_ProtectiveLid 3 "NOT_USED" 2 "OPEN" 1 "CLOSE" 0 "UNCHANGED" ;
VAL_ 1413 CC5_VideoSource_ch0 3 "NOT_USED" 2 "DCAM" 1 "TI" 0 "UNCHANGED" ;
VAL_ 1413 CC5_TI_DDE 3 "NOT_USED" 2 "OFF" 1 "ON" 0 "UNCHANGED" ;
VAL_ 1413 CC5_HorizontalFlip 3 "NOT_USED" 2 "OFF" 1 "ON" 0 "UNCHANGED" ;
VAL_ 1413 CC5_OverlayGraphics 3 "NOT_USED" 2 "OFF" 1 "ON" 0 "UNCHANGED" ;
VAL_ 1413 CC5_VideoSource_ch1 3 "NOT_USED" 2 "DCAM" 1 "TI" 0 "UNCHANGED" ;
VAL_ 1413 CC5_TI_Polarity 3 "NOT_USED" 2 "BLACK_HOT" 1 "WHITE_HOT" 0 "UNCHANGED" ;
VAL_ 1413 CC5_TI_Zoom 3 "NOT_USED" 2 "x2_ZOOM" 1 "x1_ZOOM" 0 "UNCHANGED" ;
VAL_ 1413 CC5_TI_ROI 15 "NOT_USED" 14 "NOT_USED" 13 "NOT_USED" 12 "NOT_USED" 11 "NOT_USED" 10 "NOT_USED" 9 "NOT_USED" 8 "TOP_HALF" 7 "NOT_USED" 6 "NOT_USED" 5 "NOT_USED" 4 "CENTER_BLOCK" 3 "NOT_USED" 2 "BOTTOM_HALF" 1 "FULL_SCREEN" 0 "UNCHANGED" ;
VAL_ 1413 CC5_VideoBlending_ch0 15 "NOT_USED" 14 "NOT_USED" 13 "NOT_USED" 12 "NOT_USED" 11 "NOT_USED" 10 "NOT_USED" 9 "NOT_USED" 8 "INCREASE_DCAM_AMOUNT" 7 "NOT_USED" 6 "NOT_USED" 5 "NOT_USED" 4 "INCREASE_TI_AMOUNT" 3 "NOT_USED" 2 "OFF_-_ONLY_TI" 1 "ON_-_EQUAL_TI_and_DCAM" 0 "UNCHANGED" ;
VAL_ 1413 CC5_TI_NUC_mode_reset_p2 1 "AUTOMATIC_NUC_DISABLED" 0 "AUTOMATIC_NUC_ENABLED" ;
VAL_ 1413 CC5_WindowHeaters 1 "REQUEST_ENABLED" 0 "NOT_REQUESTED" ;
VAL_ 1412 CC4_DCAM_Preset 15 "NOT_USED" 14 "NOT_USED" 13 "NOT_USED" 12 "NOT_USED" 11 "NOT_USED" 10 "NOT_USED" 9 "NOT_USED" 8 "NORMAL_LUX_SET" 7 "NOT_USED" 6 "NOT_USED" 5 "NOT_USED" 4 "HIGH_LUX_SET" 3 "NOT_USED" 2 "LOW_LUX_SET" 1 "ULTRALOW_LUX_SET" 0 "UNCHANGED" ;
VAL_ 1412 CC4_TI_NUC_mode_reset_p1 15 "NOT_USED" 14 "NOT_USED" 13 "NOT_USED" 12 "NOT_USED" 11 "NOT_USED" 10 "NOT_USED" 9 "NOT_USED" 8 "AUTOMATIC_NUC" 7 "NOT_USED" 6 "NOT_USED" 5 "NOT_USED" 4 "TI_CAMERA_DEFAULT" 3 "NOT_USED" 2 "NUC_INTERNAL" 1 "NUC_EXTERNAL" 0 "UNCHANGED" ;
VAL_ 1412 CC4_ProtectiveLid 3 "NOT_USED" 2 "OPEN" 1 "CLOSE" 0 "UNCHANGED" ;
VAL_ 1412 CC4_VideoSource_ch0 3 "NOT_USED" 2 "DCAM" 1 "TI" 0 "UNCHANGED" ;
VAL_ 1412 CC4_TI_DDE 3 "NOT_USED" 2 "OFF" 1 "ON" 0 "UNCHANGED" ;
VAL_ 1412 CC4_HorizontalFlip 3 "NOT_USED" 2 "OFF" 1 "ON" 0 "UNCHANGED" ;
VAL_ 1412 CC4_OverlayGraphics 3 "NOT_USED" 2 "OFF" 1 "ON" 0 "UNCHANGED" ;
VAL_ 1412 CC4_VideoSource_ch1 3 "NOT_USED" 2 "DCAM" 1 "TI" 0 "UNCHANGED" ;
VAL_ 1412 CC4_TI_Polarity 3 "NOT_USED" 2 "BLACK_HOT" 1 "WHITE_HOT" 0 "UNCHANGED" ;
VAL_ 1412 CC4_TI_Zoom 3 "NOT_USED" 2 "x2_ZOOM" 1 "x1_ZOOM" 0 "UNCHANGED" ;
VAL_ 1412 CC4_TI_ROI 15 "NOT_USED" 14 "NOT_USED" 13 "NOT_USED" 12 "NOT_USED" 11 "NOT_USED" 10 "NOT_USED" 9 "NOT_USED" 8 "TOP_HALF" 7 "NOT_USED" 6 "NOT_USED" 5 "NOT_USED" 4 "CENTER_BLOCK" 3 "NOT_USED" 2 "BOTTOM_HALF" 1 "FULL_SCREEN" 0 "UNCHANGED" ;
VAL_ 1412 CC4_VideoBlending_ch0 15 "NOT_USED" 14 "NOT_USED" 13 "NOT_USED" 12 "NOT_USED" 11 "NOT_USED" 10 "NOT_USED" 9 "NOT_USED" 8 "INCREASE_DCAM_AMOUNT" 7 "NOT_USED" 6 "NOT_USED" 5 "NOT_USED" 4 "INCREASE_TI_AMOUNT" 3 "NOT_USED" 2 "OFF_-_ONLY_TI" 1 "ON_-_EQUAL_TI_and_DCAM" 0 "UNCHANGED" ;
VAL_ 1412 CC4_TI_NUC_mode_reset_p2 1 "AUTOMATIC_NUC_DISABLED" 0 "AUTOMATIC_NUC_ENABLED" ;
VAL_ 1412 CC4_WindowHeaters 1 "REQUEST_ENABLED" 0 "NOT_REQUESTED" ;
VAL_ 1411 CC3_DCAM_Preset 15 "NOT_USED" 14 "NOT_USED" 13 "NOT_USED" 12 "NOT_USED" 11 "NOT_USED" 10 "NOT_USED" 9 "NOT_USED" 8 "NORMAL_LUX_SET" 7 "NOT_USED" 6 "NOT_USED" 5 "NOT_USED" 4 "HIGH_LUX_SET" 3 "NOT_USED" 2 "LOW_LUX_SET" 1 "ULTRALOW_LUX_SET" 0 "UNCHANGED" ;
VAL_ 1411 CC3_TI_NUC_mode_reset_p1 15 "NOT_USED" 14 "NOT_USED" 13 "NOT_USED" 12 "NOT_USED" 11 "NOT_USED" 10 "NOT_USED" 9 "NOT_USED" 8 "AUTOMATIC_NUC" 7 "NOT_USED" 6 "NOT_USED" 5 "NOT_USED" 4 "TI_CAMERA_DEFAULT" 3 "NOT_USED" 2 "NUC_INTERNAL" 1 "NUC_EXTERNAL" 0 "UNCHANGED" ;
VAL_ 1411 CC3_ProtectiveLid 3 "NOT_USED" 2 "OPEN" 1 "CLOSE" 0 "UNCHANGED" ;
VAL_ 1411 CC3_VideoSource_ch0 3 "NOT_USED" 2 "DCAM" 1 "TI" 0 "UNCHANGED" ;
VAL_ 1411 CC3_TI_DDE 3 "NOT_USED" 2 "OFF" 1 "ON" 0 "UNCHANGED" ;
VAL_ 1411 CC3_HorizontalFlip 3 "NOT_USED" 2 "OFF" 1 "ON" 0 "UNCHANGED" ;
VAL_ 1411 CC3_OverlayGraphics 3 "NOT_USED" 2 "OFF" 1 "ON" 0 "UNCHANGED" ;
VAL_ 1411 CC3_VideoSource_ch1 3 "NOT_USED" 2 "DCAM" 1 "TI" 0 "UNCHANGED" ;
VAL_ 1411 CC3_TI_Polarity 3 "NOT_USED" 2 "BLACK_HOT" 1 "WHITE_HOT" 0 "UNCHANGED" ;
VAL_ 1411 CC3_TI_Zoom 3 "NOT_USED" 2 "x2_ZOOM" 1 "x1_ZOOM" 0 "UNCHANGED" ;
VAL_ 1411 CC3_TI_ROI 15 "NOT_USED" 14 "NOT_USED" 13 "NOT_USED" 12 "NOT_USED" 11 "NOT_USED" 10 "NOT_USED" 9 "NOT_USED" 8 "TOP_HALF" 7 "NOT_USED" 6 "NOT_USED" 5 "NOT_USED" 4 "CENTER_BLOCK" 3 "NOT_USED" 2 "BOTTOM_HALF" 1 "FULL_SCREEN" 0 "UNCHANGED" ;
VAL_ 1411 CC3_VideoBlending_ch0 15 "NOT_USED" 14 "NOT_USED" 13 "NOT_USED" 12 "NOT_USED" 11 "NOT_USED" 10 "NOT_USED" 9 "NOT_USED" 8 "INCREASE_DCAM_AMOUNT" 7 "NOT_USED" 6 "NOT_USED" 5 "NOT_USED" 4 "INCREASE_TI_AMOUNT" 3 "NOT_USED" 2 "OFF_-_ONLY_TI" 1 "ON_-_EQUAL_TI_and_DCAM" 0 "UNCHANGED" ;
VAL_ 1411 CC3_TI_NUC_mode_reset_p2 1 "AUTOMATIC_NUC_DISABLED" 0 "AUTOMATIC_NUC_ENABLED" ;
VAL_ 1411 CC3_WindowHeaters 1 "REQUEST_ENABLED" 0 "NOT_REQUESTED" ;
VAL_ 1410 CC2_DCAM_Preset 15 "NOT_USED" 14 "NOT_USED" 13 "NOT_USED" 12 "NOT_USED" 11 "NOT_USED" 10 "NOT_USED" 9 "NOT_USED" 8 "NORMAL_LUX_SET" 7 "NOT_USED" 6 "NOT_USED" 5 "NOT_USED" 4 "HIGH_LUX_SET" 3 "NOT_USED" 2 "LOW_LUX_SET" 1 "ULTRALOW_LUX_SET" 0 "UNCHANGED" ;
VAL_ 1410 CC2_TI_NUC_mode_reset_p1 15 "NOT_USED" 14 "NOT_USED" 13 "NOT_USED" 12 "NOT_USED" 11 "NOT_USED" 10 "NOT_USED" 9 "NOT_USED" 8 "AUTOMATIC_NUC" 7 "NOT_USED" 6 "NOT_USED" 5 "NOT_USED" 4 "TI_CAMERA_DEFAULT" 3 "NOT_USED" 2 "NUC_INTERNAL" 1 "NUC_EXTERNAL" 0 "UNCHANGED" ;
VAL_ 1410 CC2_ProtectiveLid 3 "NOT_USED" 2 "OPEN" 1 "CLOSE" 0 "UNCHANGED" ;
VAL_ 1410 CC2_VideoSource_ch0 3 "NOT_USED" 2 "DCAM" 1 "TI" 0 "UNCHANGED" ;
VAL_ 1410 CC2_TI_DDE 3 "NOT_USED" 2 "OFF" 1 "ON" 0 "UNCHANGED" ;
VAL_ 1410 CC2_HorizontalFlip 3 "NOT_USED" 2 "OFF" 1 "ON" 0 "UNCHANGED" ;
VAL_ 1410 CC2_OverlayGraphics 3 "NOT_USED" 2 "OFF" 1 "ON" 0 "UNCHANGED" ;
VAL_ 1410 CC2_VideoSource_ch1 3 "NOT_USED" 2 "DCAM" 1 "TI" 0 "UNCHANGED" ;
VAL_ 1410 CC2_TI_Polarity 3 "NOT_USED" 2 "BLACK_HOT" 1 "WHITE_HOT" 0 "UNCHANGED" ;
VAL_ 1410 CC2_TI_Zoom 3 "NOT_USED" 2 "x2_ZOOM" 1 "x1_ZOOM" 0 "UNCHANGED" ;
VAL_ 1410 CC2_TI_ROI 15 "NOT_USED" 14 "NOT_USED" 13 "NOT_USED" 12 "NOT_USED" 11 "NOT_USED" 10 "NOT_USED" 9 "NOT_USED" 8 "TOP_HALF" 7 "NOT_USED" 6 "NOT_USED" 5 "NOT_USED" 4 "CENTER_BLOCK" 3 "NOT_USED" 2 "BOTTOM_HALF" 1 "FULL_SCREEN" 0 "UNCHANGED" ;
VAL_ 1410 CC2_VideoBlending_ch0 15 "NOT_USED" 14 "NOT_USED" 13 "NOT_USED" 12 "NOT_USED" 11 "NOT_USED" 10 "NOT_USED" 9 "NOT_USED" 8 "INCREASE_DCAM_AMOUNT" 7 "NOT_USED" 6 "NOT_USED" 5 "NOT_USED" 4 "INCREASE_TI_AMOUNT" 3 "NOT_USED" 2 "OFF_-_ONLY_TI" 1 "ON_-_EQUAL_TI_and_DCAM" 0 "UNCHANGED" ;
VAL_ 1410 CC2_TI_NUC_mode_reset_p2 1 "AUTOMATIC_NUC_DISABLED" 0 "AUTOMATIC_NUC_ENABLED" ;
VAL_ 1410 CC2_WindowHeaters 1 "REQUEST_ENABLED" 0 "NOT_REQUESTED" ;
VAL_ 1409 CC1_DCAM_Preset 15 "NOT_USED" 14 "NOT_USED" 13 "NOT_USED" 12 "NOT_USED" 11 "NOT_USED" 10 "NOT_USED" 9 "NOT_USED" 8 "NORMAL_LUX_SET" 7 "NOT_USED" 6 "NOT_USED" 5 "NOT_USED" 4 "HIGH_LUX_SET" 3 "NOT_USED" 2 "LOW_LUX_SET" 1 "ULTRALOW_LUX_SET" 0 "UNCHANGED" ;
VAL_ 1409 CC1_TI_NUC_mode_reset_p1 15 "NOT_USED" 14 "NOT_USED" 13 "NOT_USED" 12 "NOT_USED" 11 "NOT_USED" 10 "NOT_USED" 9 "NOT_USED" 8 "AUTOMATIC_NUC" 7 "NOT_USED" 6 "NOT_USED" 5 "NOT_USED" 4 "TI_CAMERA_DEFAULT" 3 "NOT_USED" 2 "NUC_INTERNAL" 1 "NUC_EXTERNAL" 0 "UNCHANGED" ;
VAL_ 1409 CC1_ProtectiveLid 3 "NOT_USED" 2 "OPEN" 1 "CLOSE" 0 "UNCHANGED" ;
VAL_ 1409 CC1_VideoSource_ch0 3 "NOT_USED" 2 "DCAM" 1 "TI" 0 "UNCHANGED" ;
VAL_ 1409 CC1_TI_DDE 3 "NOT_USED" 2 "OFF" 1 "ON" 0 "UNCHANGED" ;
VAL_ 1409 CC1_HorizontalFlip 3 "NOT_USED" 2 "OFF" 1 "ON" 0 "UNCHANGED" ;
VAL_ 1409 CC1_OverlayGraphics 3 "NOT_USED" 2 "OFF" 1 "ON" 0 "UNCHANGED" ;
VAL_ 1409 CC1_VideoSource_ch1 3 "NOT_USED" 2 "DCAM" 1 "TI" 0 "UNCHANGED" ;
VAL_ 1409 CC1_TI_Polarity 3 "NOT_USED" 2 "BLACK_HOT" 1 "WHITE_HOT" 0 "UNCHANGED" ;
VAL_ 1409 CC1_TI_Zoom 3 "NOT_USED" 2 "x2_ZOOM" 1 "x1_ZOOM" 0 "UNCHANGED" ;
VAL_ 1409 CC1_TI_ROI 15 "NOT_USED" 14 "NOT_USED" 13 "NOT_USED" 12 "NOT_USED" 11 "NOT_USED" 10 "NOT_USED" 9 "NOT_USED" 8 "TOP_HALF" 7 "NOT_USED" 6 "NOT_USED" 5 "NOT_USED" 4 "CENTER_BLOCK" 3 "NOT_USED" 2 "BOTTOM_HALF" 1 "FULL_SCREEN" 0 "UNCHANGED" ;
VAL_ 1409 CC1_VideoBlending_ch0 15 "NOT_USED" 14 "NOT_USED" 13 "NOT_USED" 12 "NOT_USED" 11 "NOT_USED" 10 "NOT_USED" 9 "NOT_USED" 8 "INCREASE_DCAM_AMOUNT" 7 "NOT_USED" 6 "NOT_USED" 5 "NOT_USED" 4 "INCREASE_TI_AMOUNT" 3 "NOT_USED" 2 "OFF_-_ONLY_TI" 1 "ON_-_EQUAL_TI_and_DCAM" 0 "UNCHANGED" ;
VAL_ 1409 CC1_TI_NUC_mode_reset_p2 1 "AUTOMATIC_NUC_DISABLED" 0 "AUTOMATIC_NUC_ENABLED" ;
VAL_ 1409 CC1_WindowHeaters 1 "REQUEST_ENABLED" 0 "NOT_REQUESTED" ;
VAL_ 1408 CC0_DCAM_Preset 15 "NOT_USED" 14 "NOT_USED" 13 "NOT_USED" 12 "NOT_USED" 11 "NOT_USED" 10 "NOT_USED" 9 "NOT_USED" 8 "NORMAL_LUX_SET" 7 "NOT_USED" 6 "NOT_USED" 5 "NOT_USED" 4 "HIGH_LUX_SET" 3 "NOT_USED" 2 "LOW_LUX_SET" 1 "ULTRALOW_LUX_SET" 0 "UNCHANGED" ;
VAL_ 1408 CC0_TI_NUC_mode_reset_p1 15 "NOT_USED" 14 "NOT_USED" 13 "NOT_USED" 12 "NOT_USED" 11 "NOT_USED" 10 "NOT_USED" 9 "NOT_USED" 8 "AUTOMATIC_NUC" 7 "NOT_USED" 6 "NOT_USED" 5 "NOT_USED" 4 "TI_CAMERA_DEFAULT" 3 "NOT_USED" 2 "NUC_INTERNAL" 1 "NUC_EXTERNAL" 0 "UNCHANGED" ;
VAL_ 1408 CC0_ProtectiveLid 3 "NOT_USED" 2 "OPEN" 1 "CLOSE" 0 "UNCHANGED" ;
VAL_ 1408 CC0_VideoSource_ch0 3 "NOT_USED" 2 "DCAM" 1 "TI" 0 "UNCHANGED" ;
VAL_ 1408 CC0_TI_DDE 3 "NOT_USED" 2 "OFF" 1 "ON" 0 "UNCHANGED" ;
VAL_ 1408 CC0_HorizontalFlip 3 "NOT_USED" 2 "OFF" 1 "ON" 0 "UNCHANGED" ;
VAL_ 1408 CC0_OverlayGraphics 3 "NOT_USED" 2 "OFF" 1 "ON" 0 "UNCHANGED" ;
VAL_ 1408 CC0_VideoSource_ch1 3 "NOT_USED" 2 "DCAM" 1 "TI" 0 "UNCHANGED" ;
VAL_ 1408 CC0_TI_Polarity 3 "NOT_USED" 2 "BLACK_HOT" 1 "WHITE_HOT" 0 "UNCHANGED" ;
VAL_ 1408 CC0_TI_Zoom 3 "NOT_USED" 2 "x2_ZOOM" 1 "x1_ZOOM" 0 "UNCHANGED" ;
VAL_ 1408 CC0_TI_ROI 15 "NOT_USED" 14 "NOT_USED" 13 "NOT_USED" 12 "NOT_USED" 11 "NOT_USED" 10 "NOT_USED" 9 "NOT_USED" 8 "TOP_HALF" 7 "NOT_USED" 6 "NOT_USED" 5 "NOT_USED" 4 "CENTER_BLOCK" 3 "NOT_USED" 2 "BOTTOM_HALF" 1 "FULL_SCREEN" 0 "UNCHANGED" ;
VAL_ 1408 CC0_VideoBlending_ch0 15 "NOT_USED" 14 "NOT_USED" 13 "NOT_USED" 12 "NOT_USED" 11 "NOT_USED" 10 "NOT_USED" 9 "NOT_USED" 8 "INCREASE_DCAM_AMOUNT" 7 "NOT_USED" 6 "NOT_USED" 5 "NOT_USED" 4 "INCREASE_TI_AMOUNT" 3 "NOT_USED" 2 "OFF_-_ONLY_TI" 1 "ON_-_EQUAL_TI_and_DCAM" 0 "UNCHANGED" ;
VAL_ 1408 CC0_TI_NUC_mode_reset_p2 1 "AUTOMATIC_NUC_DISABLED" 0 "AUTOMATIC_NUC_ENABLED" ;
VAL_ 1408 CC0_WindowHeaters 1 "REQUEST_ENABLED" 0 "NOT_REQUESTED" ;
VAL_ 2566849955 BMS3_ADB_BatSumS_State_of_Health 3 "Health_is_wrong" 2 "Health_is_good" 1 "Health_is_medium" 0 "Health_is_poor" ;
VAL_ 2566849955 BMS3_ADB_BatSumS_Temp_Alarm 3 "Wrong_Temperature_Alarm" 2 "High_Temperature_Alarm" 1 "Low_Temperature_Alarm" 0 "No_fault" ;
VAL_ 2566849955 BMS3_ADB_BatSumS_DischargeDis 1 "Discharge_Disable" 0 "Discharge_Enable" ;
VAL_ 2566849955 BMS3_ADB_BatSumS_ChargingDisable 1 "Charging_Disable" 0 "Charging_Enable" ;
VAL_ 2566849955 BMS3_ADB_BatSumS_HeaterEnabled 1 "Heater_Enabled" 0 "Heater_Disabled" ;
VAL_ 2566849955 BMS3_ADB_BatSumS_BypassEnabled 1 "Bypass_Enabled" 0 "Bypass_Disabled" ;
VAL_ 2566849955 BMS3_ADB_BatSumS_Voltage_Alarm 1 "Active" 0 "NotActive" ;
VAL_ 2566851235 BMS3_ADB_M3_Module_StateOfHealth 3 "Health_is_wrong" 2 "Health_is_good" 1 "Health_is_medium" 0 "Health_is_poor" ;
VAL_ 2566851235 BMS3_ADB_M3_DiscProtectTrigg 1 "Fault_Present" 0 "No_Fault" ;
VAL_ 2566851235 BMS3_ADB_M3_ChargeProtectTrigg 1 "Fault_Present" 0 "No_Fault" ;
VAL_ 2566851235 BMS3_ADB_M3_ModulesMissingFailed 1 "Fault_Present" 0 "No_Fault" ;
VAL_ 2566851235 BMS3_ADB_M3_OverTemp_detect 1 "Fault_Present" 0 "No_Fault" ;
VAL_ 2566851235 BMS3_ADB_M3_UnderVoltage_detect 1 "Fault_Present" 0 "No_Fault" ;
VAL_ 2566851235 BMS3_ADB_M3_OverVoltage_detected 1 "Fault_Present" 0 "No_Fault" ;
VAL_ 2566851235 BMS3_ADB_M3_Overload_detected 1 "Fault_Present" 0 "No_Fault" ;
VAL_ 2566851235 BMS3_ADB_M3_ShortCircuit_detect 1 "Fault_Present" 0 "No_Fault" ;
VAL_ 2566850979 BMS3_ADB_M2_Module_StateOfHealth 3 "Health_is_wrong" 2 "Health_is_good" 1 "Health_is_medium" 0 "Health_is_poor" ;
VAL_ 2566850979 BMS3_ADB_M2_DiscProtectTrigg 1 "Fault_Present" 0 "No_Fault" ;
VAL_ 2566850979 BMS3_ADB_M2_ChargeProtectTrigg 1 "Fault_Present" 0 "No_Fault" ;
VAL_ 2566850979 BMS3_ADB_M2_ModulesMissingFailed 1 "Fault_Present" 0 "No_Fault" ;
VAL_ 2566850979 BMS3_ADB_M2_OverTemp_detect 1 "Fault_Present" 0 "No_Fault" ;
VAL_ 2566850979 BMS3_ADB_M2_UnderVoltage_detect 1 "Fault_Present" 0 "No_Fault" ;
VAL_ 2566850979 BMS3_ADB_M2_OverVoltage_detected 1 "Fault_Present" 0 "No_Fault" ;
VAL_ 2566850979 BMS3_ADB_M2_Overload_detected 1 "Fault_Present" 0 "No_Fault" ;
VAL_ 2566850979 BMS3_ADB_M2_ShortCircuit_detect 1 "Fault_Present" 0 "No_Fault" ;
VAL_ 2566850723 BMS3_ADB_M1_Module_StateOfHealth 3 "Health_is_wrong" 2 "Health_is_good" 1 "Health_is_medium" 0 "Health_is_poor" ;
VAL_ 2566850723 BMS3_ADB_M1_DiscProtectTrigg 1 "Fault_Present" 0 "No_Fault" ;
VAL_ 2566850723 BMS3_ADB_M1_ChargeProtectTrigg 1 "Fault_Present" 0 "No_Fault" ;
VAL_ 2566850723 BMS3_ADB_M1_ModulesMissingFailed 1 "Fault_Present" 0 "No_Fault" ;
VAL_ 2566850723 BMS3_ADB_M1_OverTemp_detect 1 "Fault_Present" 0 "No_Fault" ;
VAL_ 2566850723 BMS3_ADB_M1_UnderVoltage_detect 1 "Fault_Present" 0 "No_Fault" ;
VAL_ 2566850723 BMS3_ADB_M1_OverVoltage_detected 1 "Fault_Present" 0 "No_Fault" ;
VAL_ 2566850723 BMS3_ADB_M1_Overload_detected 1 "Fault_Present" 0 "No_Fault" ;
VAL_ 2566850723 BMS3_ADB_M1_ShortCircuit_detect 1 "Fault_Present" 0 "No_Fault" ;
VAL_ 2566848931 BMS3_ADB_Overall_10_alarm 1 "Alarm_ON" 0 "Alarm_OFF" ;
VAL_ 2566848931 BMS3_ADB_Silent_Watch_20_alarm 1 "Alarm_ON" 0 "Alarm_OFF" ;
VAL_ 2566848931 BMS3_ADB_EngStartCapacity_alarm 1 "Alarm_ON" 0 "Alarm_OFF" ;
VAL_ 2566848675 BMS3_ADB_Batt_StsOfHealth 3 "Health_is_wrong" 2 "Health_is_good" 1 "Health_is_medium" 0 "Health_is_poor" ;
VAL_ 2566848675 BMS3_ADB_Batt_PS8_discharge_prot 1 "Fault_Present" 0 "No_Fault" ;
VAL_ 2566848675 BMS3_ADB_Batt_PS7_charge_prot 1 "Fault_Present" 0 "No_Fault" ;
VAL_ 2566848675 BMS3_ADB_Batt_PS6_mod_failed 1 "Fault_Present" 0 "No_Fault" ;
VAL_ 2566848675 BMS3_ADB_Batt_PS5_over_temp 1 "Fault_Present" 0 "No_Fault" ;
VAL_ 2566848675 BMS3_ADB_Batt_PS4_under_voltage 1 "Fault_Present" 0 "No_Fault" ;
VAL_ 2566848675 BMS3_ADB_Batt_PS3_over_voltage 1 "Fault_Present" 0 "No_Fault" ;
VAL_ 2566848675 BMS3_ADB_Batt_PS2_overload 1 "Fault_Present" 0 "No_Fault" ;
VAL_ 2566848675 BMS3_ADB_Batt_PS1_short_circuit 1 "Fault_Present" 0 "No_Fault" ;
VAL_ 2566848675 BMS3_ADB_Batt_OS_8_sleep_mode 1 "Sleep_pending" 0 "Awake" ;
VAL_ 2566848675 BMS3_ADB_Batt_OS_7_emerg_used 1 "used" 0 "never_used" ;
VAL_ 2566848675 BMS3_ADB_Batt_OS_6_emergency 1 "Active" 0 "NotActive" ;
VAL_ 2566848675 BMS3_ADB_Batt_OS_45_charge_level 3 "100%" 2 "50%" 1 "25%" 0 "OFF" ;
VAL_ 2566848675 BMS3_ADB_Batt_OS_3_charge_cont 1 "ON" 0 "OFF" ;
VAL_ 2566848675 BMS3_ADB_Batt_OS_2_heater_cont 1 "ON" 0 "OFF" ;
VAL_ 2566848675 BMS3_ADB_Batt_OS_1_master_prot 1 "Protect" 0 "OFF" ;
